VERSION ""

NS_ :

BS_:

BU_: Turbocharger OnBoardDataLogger OffBoardDiagnosticTool2 OffBoardDiagnosticTool1 FileServer ParkingBrakeController SeatControl2 FanDriveController SteeringColumnUnit CommunicationUnitRadio CommunicationUnitSatellite CommunicationUnitCellular PropulsionBatteryCharger ChassisController2 ChassisController1 EngineValveControl AuxiliaryHeater2 AuxiliaryHeater1 ClutchUnit RampControl InformationSystem1 SuspensionSystemController2 OilSensor VehicleDynamicStability ExhaustEmissionController TransmissionDisplay2 TransmissionDisplay1 ClimateControl2 WaterPumpController RearAxleSteeringController LightingOperatorControl SeatController1 IgnitionController2 IgnitionController1 TirePressureController CabController2 CabController1 PneumaticSystemController SuspensionSystemController1 HydraulicPumpController EnduranceBrakingSystem RetarderExhaustEngine2 OnBoardDiagnosticUnit HeadwayController RetarderExhaustEngine1 CabDisplay1 ManagementComputer VirtualTerminal OffVehicleGateway PowerTakeOffFront HitchControl AuxiliaryValveControl BodyController TractorTrailerBridge1 StarterSystem ElectricalSystem VehicleSecurity VehicleNavigation AerodynamicControl ElectricalChargingSystem ClimateControl1 TripRecorder InstrumentCluster SuspensionDriveAxle2 SuspensionDriveAxle1 SuspensionSteerAxle SteeringController FuelSystem CruiseControl RetarderDriveline RetarderEngine BrakesDriveAxle2 BrakesDriveAxle1 BrakesSystemController BrakesSteerAxle AxleDrive2 AxleDrive1 AxleSteering PowerTakeOff ShiftConsoleSecondary ShiftConsolePrimary Transmission2 Transmission1 Engine2 Engine1

BO_ 3221225472 VECTOR__INDEPENDENT_SIG_MSG: 0 Vector__XXX
 SG_ TrailerWeight : 0|16@1+ (2,0) [0|128510] "kg" Vector__XXX
 SG_ ReferenceTirePressSetting : 0|8@1+ (8,0) [0|2000] "kPa" Vector__XXX
 SG_ ReferenceTirePress : 0|8@1+ (8,0) [0|2000] "kPa" Vector__XXX
 SG_ TirePressThresholdDetection : 0|3@1+ (1,0) [0|7] "" Vector__XXX
 SG_ TireAirLeakageRate : 0|16@1+ (0.1,0) [0|6425.5] "Pa/s" Vector__XXX
 SG_ CTIWheelEndElectricalFault : 0|2@1+ (1,0) [0|3] "" Vector__XXX
 SG_ CTITireStatus : 0|2@1+ (1,0) [0|3] "" Vector__XXX
 SG_ CTIWheelSensorStatus : 0|2@1+ (1,0) [0|3] "" Vector__XXX
 SG_ TireTemp : 0|16@1+ (0.03125,-273) [-273|1734.96875] "deg C" Vector__XXX
 SG_ TirePress : 0|8@1+ (4,0) [0|1000] "kPa" Vector__XXX
 SG_ EngTorqueMode : 0|4@1+ (1,0) [0|15] "" Vector__XXX
 SG_ EngTrqMd_Corrected : 0|8@1+ (1,0) [0|255] "" Vector__XXX
 SG_ EngTrqMd_Corrected : 0|8@1+ (1,0) [0|255] "" Vector__XXX
 SG_ SrcAddrssOfCtrllngDvcFrEngCntrl : 0|8@1+ (1,0) [0|255] "" Vector__XXX
 SG_ ActlEngPrcntTrqueHighResolution : 0|4@1+ (0.125,0) [0|0.875] "%" Vector__XXX
 SG_ EngDemandPercentTorque : 0|8@1+ (1,-125) [-125|125] "%" Vector__XXX
 SG_ EngStarterMode : 0|4@1+ (1,0) [0|15] "" Vector__XXX
 SG_ EngSpeed : 0|16@1+ (0.125,0) [0|8031.875] "rpm" Vector__XXX
 SG_ ActualEngPercentTorque : 0|8@1+ (1,-125) [-125|125] "%" Vector__XXX
 SG_ DriversDemandEngPercentTorque : 0|8@1+ (1,-125) [-125|125] "%" Vector__XXX
 SG_ MessageCounter : 0|4@1+ (1,0) [0|15] "" Vector__XXX
 SG_ ControlPurpose : 0|5@1+ (1,0) [0|31] "" Vector__XXX
 SG_ TransmissionRate : 0|3@1+ (1,0) [0|7] "" Vector__XXX
 SG_ EngRqedTorque_TorqueLimit : 0|8@1+ (1,-125) [-125|125] "%" Vector__XXX
 SG_ EngRqedSpeed_SpeedLimit : 0|16@1+ (0.125,0) [0|8031.875] "rpm" Vector__XXX
 SG_ OverrideCtrlModePriority : 0|2@1+ (1,0) [0|3] "" Vector__XXX
 SG_ EngRqedSpeedCtrlConditions : 0|2@1+ (1,0) [0|3] "" Vector__XXX
 SG_ EngOverrideCtrlMode : 0|2@1+ (1,0) [0|3] "" Vector__XXX
 SG_ MessageChecksum : 0|4@1+ (1,0) [0|15] "" Vector__XXX
 SG_ EngineRequestedTorqueHiRes : 0|4@1+ (0.125,0) [0|0.875] "%" Vector__XXX
 SG_ TransCurrentRange : 0|16@1+ (1,0) [0|255] "" Vector__XXX
 SG_ TransRqedRange : 0|16@1+ (1,0) [0|255] "per" Vector__XXX
 SG_ TransCurrentGear : 0|8@1+ (1,-125) [-125|125] "" Vector__XXX
 SG_ TransActualGearRatio : 0|16@1+ (0.001,0) [0|64.255] "" Vector__XXX
 SG_ TransSelectedGear : 0|8@1+ (1,-125) [-125|125] "" Vector__XXX
 SG_ TrnsTrqueConverterLockupEngaged : 0|2@1+ (1,0) [0|3] "" Vector__XXX
 SG_ TrnsTrqCnvrtrLckpTrnstnInPrcess : 0|2@1+ (1,0) [0|3] "" Vector__XXX
 SG_ SrcAddrssOfCtrllngDvcFrTrnsCntrl : 0|8@1+ (1,0) [0|255] "" Vector__XXX
 SG_ MomentaryEngMaxPowerEnable : 0|2@1+ (1,0) [0|3] "" Vector__XXX
 SG_ TransInputShaftSpeed : 0|16@1+ (0.125,0) [0|8031.875] "rpm" Vector__XXX
 SG_ ProgressiveShiftDisable : 0|2@1+ (1,0) [0|3] "" Vector__XXX
 SG_ EngMomentaryOverspeedEnable : 0|2@1+ (1,0) [0|3] "" Vector__XXX
 SG_ PercentClutchSlip : 0|8@1+ (0.4,0) [0|100] "%" Vector__XXX
 SG_ TransOutputShaftSpeed : 0|16@1+ (0.125,0) [0|8031.875] "rpm" Vector__XXX
 SG_ TransShiftInProcess : 0|2@1+ (1,0) [0|3] "" Vector__XXX
 SG_ TransDrivelineEngaged : 0|2@1+ (1,0) [0|3] "" Vector__XXX
 SG_ UnitNumber : 0|8@1+ (1,0) [0|255] "" Vector__XXX
 SG_ SerialNumber : 0|8@1+ (1,0) [0|255] "" Vector__XXX
 SG_ Model : 0|8@1+ (1,0) [0|255] "" Vector__XXX
 SG_ Make : 0|8@1+ (1,0) [0|255] "" Vector__XXX
 SG_ DTC5 : 0|32@1+ (1,0) [0|4294967295] "" Vector__XXX
 SG_ DTC4 : 0|32@1+ (1,0) [0|4294967295] "" Vector__XXX
 SG_ DTC3 : 0|32@1+ (1,0) [0|4294967295] "" Vector__XXX
 SG_ DTC2 : 0|32@1+ (1,0) [0|4294967295] "" Vector__XXX

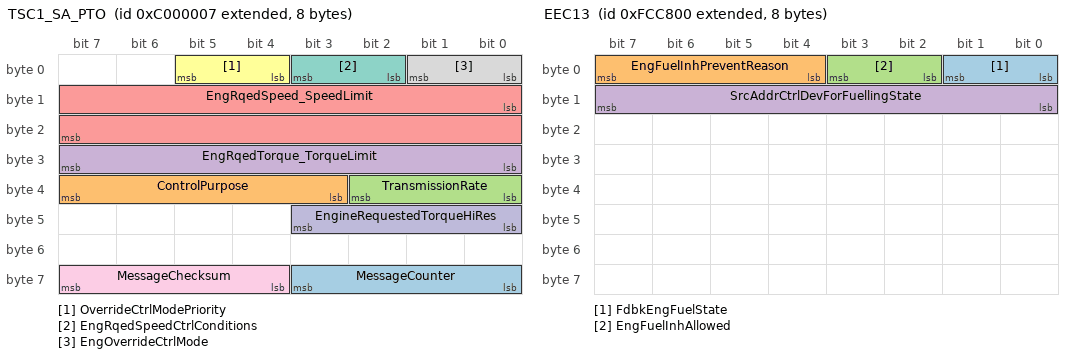
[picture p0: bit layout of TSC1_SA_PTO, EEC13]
BO_ 2348810247 TSC1_SA_PTO: 8 Vector__XXX
 SG_ MessageCounter : 56|4@1+ (1,0) [0|15] "" Vector__XXX
 SG_ ControlPurpose : 35|5@1+ (1,0) [0|31] "" Vector__XXX
 SG_ TransmissionRate : 32|3@1+ (1,0) [0|7] "" Vector__XXX
 SG_ EngRqedTorque_TorqueLimit : 24|8@1+ (1,-125) [-125|125] "%" Vector__XXX
 SG_ EngRqedSpeed_SpeedLimit : 8|16@1+ (0.125,0) [0|8031.875] "rpm" Vector__XXX
 SG_ OverrideCtrlModePriority : 4|2@1+ (1,0) [0|3] "" Vector__XXX
 SG_ EngRqedSpeedCtrlConditions : 2|2@1+ (1,0) [0|3] "" Vector__XXX
 SG_ EngOverrideCtrlMode : 0|2@1+ (1,0) [0|3] "" Vector__XXX
 SG_ MessageChecksum : 60|4@1+ (1,0) [0|15] "" Vector__XXX
 SG_ EngineRequestedTorqueHiRes : 40|4@1+ (0.125,0) [0|0.875] "%" Vector__XXX

BO_ 2558984192 ESR: 8 Vector__XXX
 SG_ DesEngFuelState : 0|2@1+ (1,0) [0|0] "" Vector__XXX

BO_ 2164049920 EEC13: 8 Vector__XXX
 SG_ FdbkEngFuelState : 0|2@1+ (1,0) [0|0] "" Vector__XXX
 SG_ EngFuelInhPreventReason : 4|4@1+ (1,0) [0|0] "" Vector__XXX
 SG_ EngFuelInhAllowed : 2|2@1+ (1,0) [0|0] "" Vector__XXX
 SG_ SrcAddrCtrlDevForFuellingState : 8|8@1+ (1,0) [0|255] "" Vector__XXX

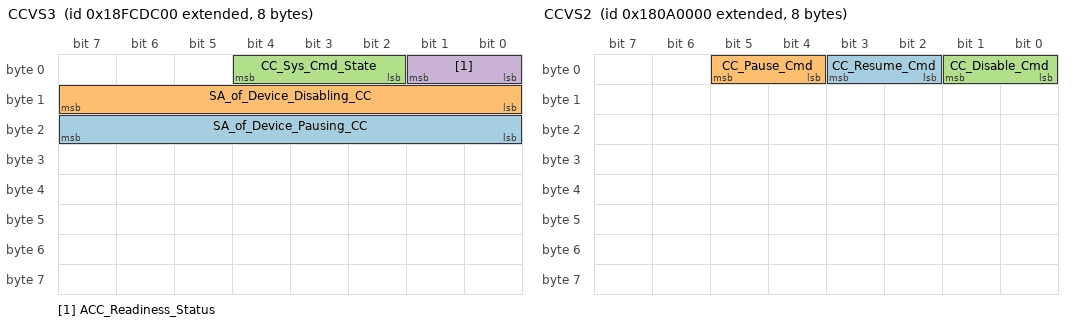
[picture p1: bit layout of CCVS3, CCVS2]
BO_ 2566708224 CCVS3: 8 Vector__XXX
 SG_ SA_of_Device_Pausing_CC : 16|8@1+ (1,0) [0|255] "" Vector__XXX
 SG_ SA_of_Device_Disabling_CC : 8|8@1+ (1,0) [0|255] "" Vector__XXX
 SG_ CC_Sys_Cmd_State : 2|3@1+ (1,0) [0|3] "" Vector__XXX
 SG_ ACC_Readiness_Status : 0|2@1+ (1,0) [0|3] "" Vector__XXX

BO_ 2550792192 CCVS2: 8 Vector__XXX
 SG_ CC_Resume_Cmd : 2|2@1+ (1,0) [0|3] "" Vector__XXX
 SG_ CC_Pause_Cmd : 4|2@1+ (1,0) [0|3] "" Vector__XXX
 SG_ CC_Disable_Cmd : 0|2@1+ (1,0) [0|3] "" Vector__XXX

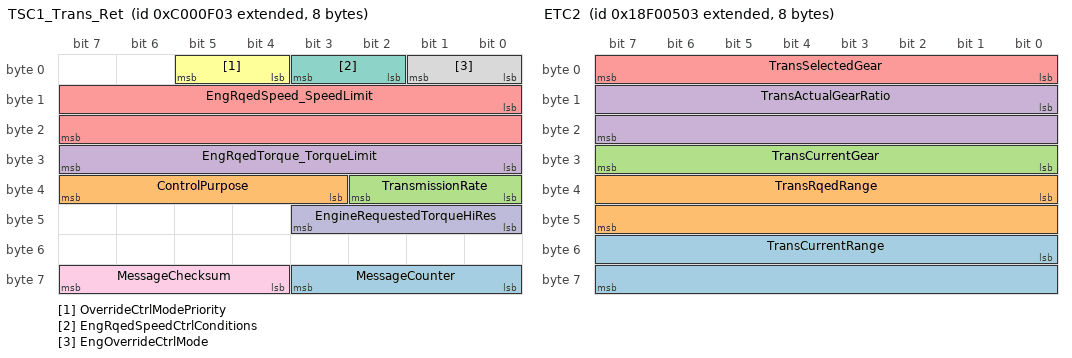
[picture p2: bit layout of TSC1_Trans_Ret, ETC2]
BO_ 2348814083 TSC1_Trans_Ret: 8 Vector__XXX
 SG_ MessageCounter : 56|4@1+ (1,0) [0|15] "" Vector__XXX
 SG_ ControlPurpose : 35|5@1+ (1,0) [0|31] "" Vector__XXX
 SG_ TransmissionRate : 32|3@1+ (1,0) [0|7] "" Vector__XXX
 SG_ EngRqedTorque_TorqueLimit : 24|8@1+ (1,-125) [-125|125] "%" Vector__XXX
 SG_ EngRqedSpeed_SpeedLimit : 8|16@1+ (0.125,0) [0|8031.875] "rpm" Vector__XXX
 SG_ OverrideCtrlModePriority : 4|2@1+ (1,0) [0|3] "" Vector__XXX
 SG_ EngRqedSpeedCtrlConditions : 2|2@1+ (1,0) [0|3] "" Vector__XXX
 SG_ EngOverrideCtrlMode : 0|2@1+ (1,0) [0|3] "" Vector__XXX
 SG_ MessageChecksum : 60|4@1+ (1,0) [0|15] "" Vector__XXX
 SG_ EngineRequestedTorqueHiRes : 40|4@1+ (0.125,0) [0|0.875] "%" Vector__XXX

BO_ 2565866755 ETC2: 8 Vector__XXX
 SG_ TransCurrentRange : 48|16@1+ (1,0) [0|255] "" Vector__XXX
 SG_ TransRqedRange : 32|16@1+ (1,0) [0|255] "per" Vector__XXX
 SG_ TransCurrentGear : 24|8@1+ (1,-125) [-125|125] "" Vector__XXX
 SG_ TransActualGearRatio : 8|16@1+ (0.001,0) [0|64.255] "" Vector__XXX
 SG_ TransSelectedGear : 0|8@1+ (1,-125) [-125|125] "" Vector__XXX

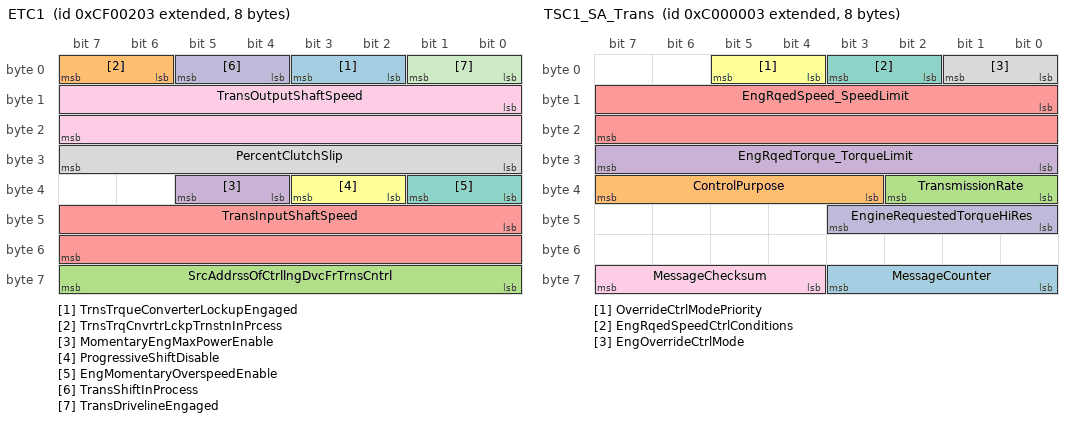
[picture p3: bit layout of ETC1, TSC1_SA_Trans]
BO_ 2364539395 ETC1: 8 Vector__XXX
 SG_ TrnsTrqueConverterLockupEngaged : 2|2@1+ (1,0) [0|3] "" Vector__XXX
 SG_ TrnsTrqCnvrtrLckpTrnstnInPrcess : 6|2@1+ (1,0) [0|3] "" Vector__XXX
 SG_ SrcAddrssOfCtrllngDvcFrTrnsCntrl : 56|8@1+ (1,0) [0|255] "" Vector__XXX
 SG_ MomentaryEngMaxPowerEnable : 36|2@1+ (1,0) [0|3] "" Vector__XXX
 SG_ TransInputShaftSpeed : 40|16@1+ (0.125,0) [0|8031.875] "rpm" Vector__XXX
 SG_ ProgressiveShiftDisable : 34|2@1+ (1,0) [0|3] "" Vector__XXX
 SG_ EngMomentaryOverspeedEnable : 32|2@1+ (1,0) [0|3] "" Vector__XXX
 SG_ PercentClutchSlip : 24|8@1+ (0.4,0) [0|100] "%" Vector__XXX
 SG_ TransOutputShaftSpeed : 8|16@1+ (0.125,0) [0|8031.875] "rpm" Vector__XXX
 SG_ TransShiftInProcess : 4|2@1+ (1,0) [0|3] "" Vector__XXX
 SG_ TransDrivelineEngaged : 0|2@1+ (1,0) [0|3] "" Vector__XXX

BO_ 2348810243 TSC1_SA_Trans: 8 Vector__XXX
 SG_ MessageCounter : 56|4@1+ (1,0) [0|15] "" Vector__XXX
 SG_ ControlPurpose : 35|5@1+ (1,0) [0|31] "" Vector__XXX
 SG_ TransmissionRate : 32|3@1+ (1,0) [0|7] "" Vector__XXX
 SG_ EngRqedTorque_TorqueLimit : 24|8@1+ (1,-125) [-125|125] "%" Vector__XXX
 SG_ EngRqedSpeed_SpeedLimit : 8|16@1+ (0.125,0) [0|8031.875] "rpm" Vector__XXX
 SG_ OverrideCtrlModePriority : 4|2@1+ (1,0) [0|3] "" Vector__XXX
 SG_ EngRqedSpeedCtrlConditions : 2|2@1+ (1,0) [0|3] "" Vector__XXX
 SG_ EngOverrideCtrlMode : 0|2@1+ (1,0) [0|3] "" Vector__XXX
 SG_ MessageChecksum : 60|4@1+ (1,0) [0|15] "" Vector__XXX
 SG_ EngineRequestedTorqueHiRes : 40|4@1+ (0.125,0) [0|0.875] "%" Vector__XXX

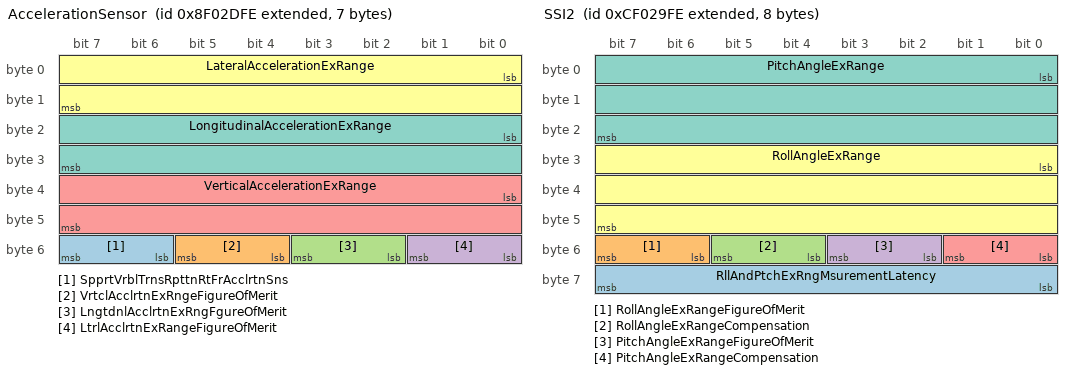
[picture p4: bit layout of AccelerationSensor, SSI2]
BO_ 2297441790 AccelerationSensor: 7 Vector__XXX
 SG_ SpprtVrblTrnsRpttnRtFrAcclrtnSns : 54|2@1+ (1,0) [0|3] "" Vector__XXX
 SG_ VrtclAcclrtnExRngeFigureOfMerit : 52|2@1+ (1,0) [0|3] "" Vector__XXX
 SG_ LngtdnlAcclrtnExRngFgureOfMerit : 50|2@1+ (1,0) [0|3] "" Vector__XXX
 SG_ LtrlAcclrtnExRangeFigureOfMerit : 48|2@1+ (1,0) [0|3] "" Vector__XXX
 SG_ VerticalAccelerationExRange : 32|16@1+ (0.01,-320) [-320|322.55] "m/s²" Vector__XXX
 SG_ LateralAccelerationExRange : 0|16@1+ (0.01,-320) [-320|322.55] "m/s²" Vector__XXX
 SG_ LongitudinalAccelerationExRange : 16|16@1+ (0.01,-320) [-320|322.55] "m/s²" Vector__XXX

BO_ 2566712062 VEP4: 8 Vector__XXX
 SG_ HybrdBatteryPackRemainingCharge : 0|16@1+ (0.0025,0) [0|160.6375] "%" Vector__XXX

BO_ 2364549630 SSI2: 8 Vector__XXX
 SG_ RllAndPtchExRngMsurementLatency : 56|8@1+ (0.5,0) [0|125] "ms" Vector__XXX
 SG_ RollAngleExRangeFigureOfMerit : 54|2@1+ (1,0) [0|3] "" Vector__XXX
 SG_ RollAngleExRangeCompensation : 52|2@1+ (1,0) [0|3] "" Vector__XXX
 SG_ PitchAngleExRangeFigureOfMerit : 50|2@1+ (1,0) [0|3] "" Vector__XXX
 SG_ PitchAngleExRangeCompensation : 48|2@1+ (1,0) [0|3] "" Vector__XXX
 SG_ RollAngleExRange : 24|24@1+ (3.0517578125E-005,-250) [-250|250.9999] "deg" Vector__XXX
 SG_ PitchAngleExRange : 0|24@1+ (3.0517578125E-005,-250) [-250|250.9999] "deg" Vector__XXX

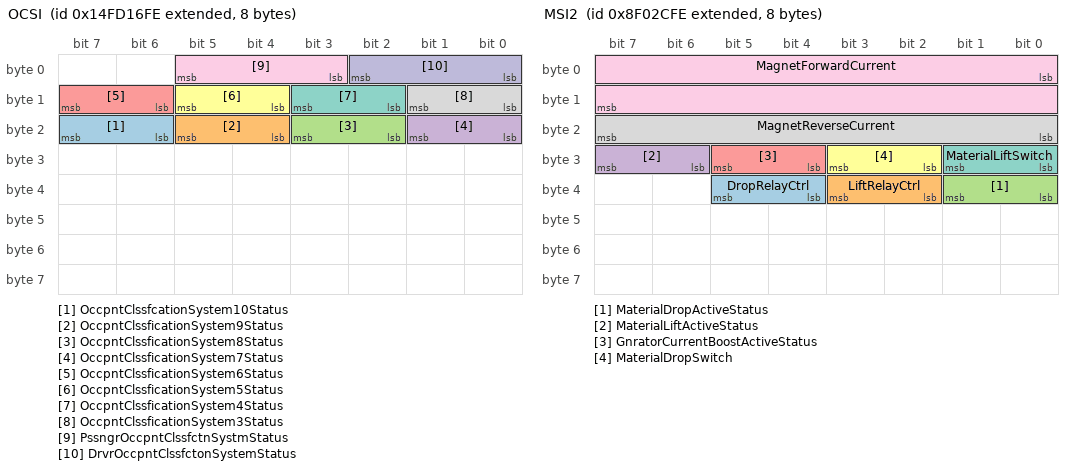
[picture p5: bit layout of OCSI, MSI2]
BO_ 2499614462 OCSI: 8 Vector__XXX
 SG_ OccpntClssfcationSystem10Status : 22|2@1+ (1,0) [0|3] "" Vector__XXX
 SG_ OccpntClssficationSystem9Status : 20|2@1+ (1,0) [0|3] "" Vector__XXX
 SG_ OccpntClssficationSystem8Status : 18|2@1+ (1,0) [0|3] "" Vector__XXX
 SG_ OccpntClssficationSystem7Status : 16|2@1+ (1,0) [0|3] "" Vector__XXX
 SG_ OccpntClssficationSystem6Status : 14|2@1+ (1,0) [0|3] "" Vector__XXX
 SG_ OccpntClssficationSystem5Status : 12|2@1+ (1,0) [0|3] "" Vector__XXX
 SG_ OccpntClssficationSystem4Status : 10|2@1+ (1,0) [0|3] "" Vector__XXX
 SG_ OccpntClssficationSystem3Status : 8|2@1+ (1,0) [0|3] "" Vector__XXX
 SG_ PssngrOccpntClssfctnSystmStatus : 3|3@1+ (1,0) [0|7] "" Vector__XXX
 SG_ DrvrOccpntClssfctonSystemStatus : 0|3@1+ (1,0) [0|7] "" Vector__XXX

BO_ 2560098046 NCS: 8 Vector__XXX
 SG_ CabNoiseCtrlTuningStatus : 2|4@1+ (1,0) [0|15] "" Vector__XXX
 SG_ CabNoiseCtrlStatus : 0|2@1+ (1,0) [0|3] "" Vector__XXX

BO_ 2560163582 NC1: 8 Vector__XXX
 SG_ CabNoiseCtrlTuningState : 2|3@1+ (1,0) [0|7] "" Vector__XXX
 SG_ CabNoiseCtrlState : 0|2@1+ (1,0) [0|3] "" Vector__XXX

BO_ 2297441534 MSI2: 8 Vector__XXX
 SG_ DropRelayCtrl : 36|2@1+ (1,0) [0|3] "" Vector__XXX
 SG_ LiftRelayCtrl : 34|2@1+ (1,0) [0|3] "" Vector__XXX
 SG_ MaterialDropActiveStatus : 32|2@1+ (1,0) [0|3] "" Vector__XXX
 SG_ MaterialLiftActiveStatus : 30|2@1+ (1,0) [0|3] "" Vector__XXX
 SG_ GnratorCurrentBoostActiveStatus : 28|2@1+ (1,0) [0|3] "" Vector__XXX
 SG_ MaterialDropSwitch : 26|2@1+ (1,0) [0|3] "" Vector__XXX
 SG_ MaterialLiftSwitch : 24|2@1+ (1,0) [0|3] "" Vector__XXX
 SG_ MagnetReverseCurrent : 16|8@1+ (1,0) [0|250] "A" Vector__XXX
 SG_ MagnetForwardCurrent : 0|16@1+ (1,0) [0|64255] "Amps" Vector__XXX

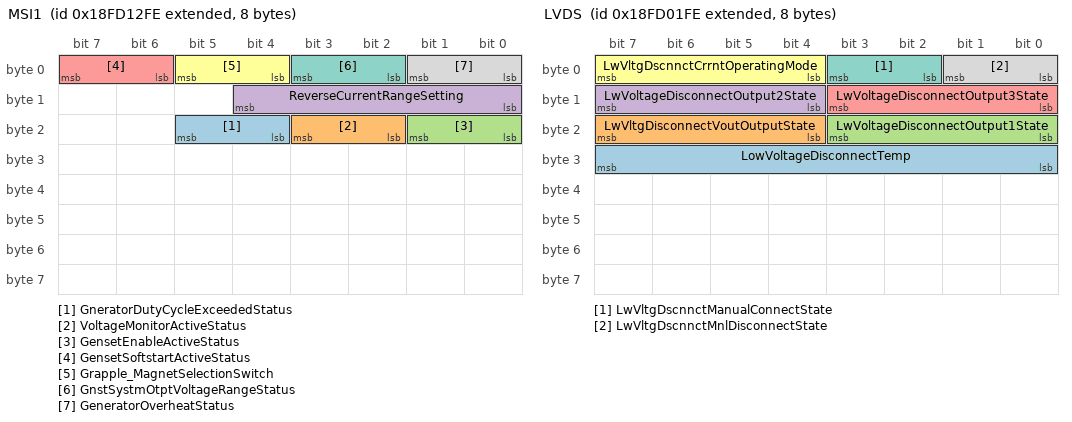
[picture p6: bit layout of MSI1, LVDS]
BO_ 2566722302 MSI1: 8 Vector__XXX
 SG_ GneratorDutyCycleExceededStatus : 20|2@1+ (1,0) [0|3] "" Vector__XXX
 SG_ VoltageMonitorActiveStatus : 18|2@1+ (1,0) [0|3] "" Vector__XXX
 SG_ GensetEnableActiveStatus : 16|2@1+ (1,0) [0|3] "" Vector__XXX
 SG_ ReverseCurrentRangeSetting : 8|5@1+ (1,0) [0|31] "" Vector__XXX
 SG_ GensetSoftstartActiveStatus : 6|2@1+ (1,0) [0|3] "" Vector__XXX
 SG_ Grapple_MagnetSelectionSwitch : 4|2@1+ (1,0) [0|3] "" Vector__XXX
 SG_ GnstSystmOtptVoltageRangeStatus : 2|2@1+ (1,0) [0|3] "" Vector__XXX
 SG_ GeneratorOverheatStatus : 0|2@1+ (1,0) [0|3] "" Vector__XXX

BO_ 2566722558 MSCI: 8 Vector__XXX
 SG_ MagnetRatedPower : 8|16@1+ (0.5,0) [0|32127.5] "kW" Vector__XXX
 SG_ MagnetBoostTime : 0|8@1+ (0.25,0) [0|62.5] "s" Vector__XXX

BO_ 2560032510 LVDSOM: 8 Vector__XXX
 SG_ LwVltgDscnnctDsredOperatingMode : 0|4@1+ (1,0) [0|15] "" Vector__XXX

BO_ 2566717950 LVDS: 8 Vector__XXX
 SG_ LowVoltageDisconnectTemp : 24|8@1+ (1,-40) [-40|210] "deg C" Vector__XXX
 SG_ LwVltgDisconnectVoutOutputState : 20|4@1+ (1,0) [0|15] "" Vector__XXX
 SG_ LwVoltageDisconnectOutput1State : 16|4@1+ (1,0) [0|15] "" Vector__XXX
 SG_ LwVoltageDisconnectOutput2State : 12|4@1+ (1,0) [0|15] "" Vector__XXX
 SG_ LwVoltageDisconnectOutput3State : 8|4@1+ (1,0) [0|15] "" Vector__XXX
 SG_ LwVltgDscnnctCrrntOperatingMode : 4|4@1+ (1,0) [0|15] "" Vector__XXX
 SG_ LwVltgDscnnctManualConnectState : 2|2@1+ (1,0) [0|3] "" Vector__XXX
 SG_ LwVltgDscnnctMnlDisconnectState : 0|2@1+ (1,0) [0|3] "" Vector__XXX

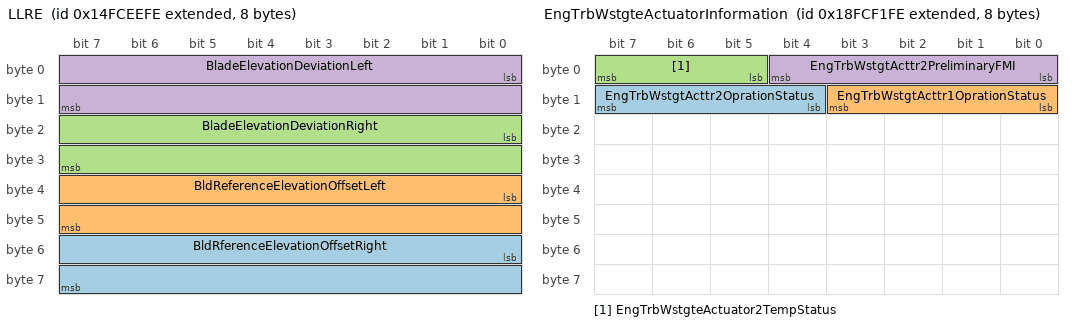
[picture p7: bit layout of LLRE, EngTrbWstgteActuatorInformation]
BO_ 2499604222 LLRE: 8 Vector__XXX
 SG_ BldRferenceElevationOffsetRight : 48|16@1+ (1,-32000) [-32000|32255] "mm" Vector__XXX
 SG_ BldReferenceElevationOffsetLeft : 32|16@1+ (1,-32000) [-32000|32255] "mm" Vector__XXX
 SG_ BladeElevationDeviationRight : 16|16@1+ (1,-32000) [-32000|32255] "mm" Vector__XXX
 SG_ BladeElevationDeviationLeft : 0|16@1+ (1,-32000) [-32000|32255] "mm" Vector__XXX

BO_ 2358902526 JLCM: 8 Vector__XXX
 SG_ Joystick3Lamp10Cmd : 58|2@1+ (1,0) [0|3] "" Vector__XXX
 SG_ Joystick3Lamp9Cmd : 56|2@1+ (1,0) [0|3] "" Vector__XXX
 SG_ Joystick3Lamp8Cmd : 54|2@1+ (1,0) [0|3] "" Vector__XXX
 SG_ Joystick3Lamp7Cmd : 52|2@1+ (1,0) [0|3] "" Vector__XXX
 SG_ Joystick3Lamp6Cmd : 50|2@1+ (1,0) [0|3] "" Vector__XXX
 SG_ Joystick3Lamp5Cmd : 48|2@1+ (1,0) [0|3] "" Vector__XXX
 SG_ Joystick3Lamp4Cmd : 46|2@1+ (1,0) [0|3] "" Vector__XXX
 SG_ Joystick3Lamp3Cmd : 44|2@1+ (1,0) [0|3] "" Vector__XXX
 SG_ Joystick3Lamp2Cmd : 42|2@1+ (1,0) [0|3] "" Vector__XXX
 SG_ Joystick3Lamp1Cmd : 40|2@1+ (1,0) [0|3] "" Vector__XXX
 SG_ Joystick2Lamp10Cmd : 38|2@1+ (1,0) [0|3] "" Vector__XXX
 SG_ Joystick2Lamp9Cmd : 36|2@1+ (1,0) [0|3] "" Vector__XXX
 SG_ Joystick2Lamp8Cmd : 34|2@1+ (1,0) [0|3] "" Vector__XXX
 SG_ Joystick2Lamp7Cmd : 32|2@1+ (1,0) [0|3] "" Vector__XXX
 SG_ Joystick2Lamp6Cmd : 30|2@1+ (1,0) [0|3] "" Vector__XXX
 SG_ Joystick2Lamp5Cmd : 28|2@1+ (1,0) [0|3] "" Vector__XXX
 SG_ Joystick2Lamp4Cmd : 26|2@1+ (1,0) [0|3] "" Vector__XXX
 SG_ Joystick2Lamp3Cmd : 24|2@1+ (1,0) [0|3] "" Vector__XXX
 SG_ Joystick2Lamp2Cmd : 22|2@1+ (1,0) [0|3] "" Vector__XXX
 SG_ Joystick2Lamp1Cmd : 20|2@1+ (1,0) [0|3] "" Vector__XXX
 SG_ Joystick1Lamp10Cmd : 18|2@1+ (1,0) [0|3] "" Vector__XXX
 SG_ Joystick1Lamp9Cmd : 16|2@1+ (1,0) [0|3] "" Vector__XXX
 SG_ Joystick1Lamp8Cmd : 14|2@1+ (1,0) [0|3] "" Vector__XXX
 SG_ Joystick1Lamp7Cmd : 12|2@1+ (1,0) [0|3] "" Vector__XXX
 SG_ Joystick1Lamp6Cmd : 10|2@1+ (1,0) [0|3] "" Vector__XXX
 SG_ Joystick1Lamp5Cmd : 8|2@1+ (1,0) [0|3] "" Vector__XXX
 SG_ Joystick1Lamp4Cmd : 6|2@1+ (1,0) [0|3] "" Vector__XXX
 SG_ Joystick1Lamp3Cmd : 4|2@1+ (1,0) [0|3] "" Vector__XXX
 SG_ Joystick1Lamp2Cmd : 2|2@1+ (1,0) [0|3] "" Vector__XXX
 SG_ Joystick1Lamp1Cmd : 0|2@1+ (1,0) [0|3] "" Vector__XXX

BO_ 2566711550 IVAC: 8 Vector__XXX
 SG_ IntkVlvActtnSystmOlPrss2SlndCtrl : 2|2@1+ (1,0) [0|3] "" Vector__XXX
 SG_ IntkVlvActtnSystmOlPrss1SlndCtrl : 0|2@1+ (1,0) [0|3] "" Vector__XXX

BO_ 2633832958 ILI: 200 Vector__XXX
 SG_ SpecialIgnitorLoop90Resistance : 1584|16@1+ (0.1,0) [0|6425.5] "ohm" Vector__XXX
 SG_ SpecialIgnitorLoop89Resistance : 1568|16@1+ (0.1,0) [0|6425.5] "ohm" Vector__XXX
 SG_ SpecialIgnitorLoop88Resistance : 1552|16@1+ (0.1,0) [0|6425.5] "ohm" Vector__XXX
 SG_ SpecialIgnitorLoop87Resistance : 1536|16@1+ (0.1,0) [0|6425.5] "ohm" Vector__XXX
 SG_ SpecialIgnitorLoop86Resistance : 1520|16@1+ (0.1,0) [0|6425.5] "ohm" Vector__XXX
 SG_ SpecialIgnitorLoop85Resistance : 1504|16@1+ (0.1,0) [0|6425.5] "ohm" Vector__XXX
 SG_ SpecialIgnitorLoop84Resistance : 1488|16@1+ (0.1,0) [0|6425.5] "ohm" Vector__XXX
 SG_ SpecialIgnitorLoop83Resistance : 1472|16@1+ (0.1,0) [0|6425.5] "ohm" Vector__XXX
 SG_ SpecialIgnitorLoop82Resistance : 1456|16@1+ (0.1,0) [0|6425.5] "ohm" Vector__XXX
 SG_ SpecialIgnitorLoop81Resistance : 1440|16@1+ (0.1,0) [0|6425.5] "ohm" Vector__XXX
 SG_ SpecialIgnitorLoop80Resistance : 1424|16@1+ (0.1,0) [0|6425.5] "ohm" Vector__XXX
 SG_ SpecialIgnitorLoop79Resistance : 1408|16@1+ (0.1,0) [0|6425.5] "ohm" Vector__XXX
 SG_ SpecialIgnitorLoop78Resistance : 1392|16@1+ (0.1,0) [0|6425.5] "ohm" Vector__XXX
 SG_ SpecialIgnitorLoop77Resistance : 1376|16@1+ (0.1,0) [0|6425.5] "ohm" Vector__XXX
 SG_ SpecialIgnitorLoop76Resistance : 1360|16@1+ (0.1,0) [0|6425.5] "ohm" Vector__XXX
 SG_ SpecialIgnitorLoop75Resistance : 1344|16@1+ (0.1,0) [0|6425.5] "ohm" Vector__XXX
 SG_ SpecialIgnitorLoop74Resistance : 1328|16@1+ (0.1,0) [0|6425.5] "ohm" Vector__XXX
 SG_ SpecialIgnitorLoop73Resistance : 1312|16@1+ (0.1,0) [0|6425.5] "ohm" Vector__XXX
 SG_ SpecialIgnitorLoop72Resistance : 1296|16@1+ (0.1,0) [0|6425.5] "ohm" Vector__XXX
 SG_ SpecialIgnitorLoop71Resistance : 1280|16@1+ (0.1,0) [0|6425.5] "ohm" Vector__XXX
 SG_ SpecialIgnitorLoop70Resistance : 1264|16@1+ (0.1,0) [0|6425.5] "ohm" Vector__XXX
 SG_ SpecialIgnitorLoop69Resistance : 1248|16@1+ (0.1,0) [0|6425.5] "ohm" Vector__XXX
 SG_ SpecialIgnitorLoop68Resistance : 1232|16@1+ (0.1,0) [0|6425.5] "ohm" Vector__XXX
 SG_ SpecialIgnitorLoop67Resistance : 1216|16@1+ (0.1,0) [0|6425.5] "ohm" Vector__XXX
 SG_ SpecialIgnitorLoop66Resistance : 1200|16@1+ (0.1,0) [0|6425.5] "ohm" Vector__XXX
 SG_ SpecialIgnitorLoop65Resistance : 1184|16@1+ (0.1,0) [0|6425.5] "ohm" Vector__XXX
 SG_ SpecialIgnitorLoop64Resistance : 1168|16@1+ (0.1,0) [0|6425.5] "ohm" Vector__XXX
 SG_ SpecialIgnitorLoop63Resistance : 1152|16@1+ (0.1,0) [0|6425.5] "ohm" Vector__XXX
 SG_ SpecialIgnitorLoop61Resistance : 1120|16@1+ (0.1,0) [0|6425.5] "ohm" Vector__XXX
 SG_ SpecialIgnitorLoop60Resistance : 1104|16@1+ (0.1,0) [0|6425.5] "ohm" Vector__XXX
 SG_ SpecialIgnitorLoop59Resistance : 1088|16@1+ (0.1,0) [0|6425.5] "ohm" Vector__XXX
 SG_ SpecialIgnitorLoop58Resistance : 1072|16@1+ (0.1,0) [0|6425.5] "ohm" Vector__XXX
 SG_ SpecialIgnitorLoop57Resistance : 1056|16@1+ (0.1,0) [0|6425.5] "ohm" Vector__XXX
 SG_ SpecialIgnitorLoop56Resistance : 1040|16@1+ (0.1,0) [0|6425.5] "ohm" Vector__XXX
 SG_ SpecialIgnitorLoop55Resistance : 1024|16@1+ (0.1,0) [0|6425.5] "ohm" Vector__XXX
 SG_ SpecialIgnitorLoop54Resistance : 1008|16@1+ (0.1,0) [0|6425.5] "ohm" Vector__XXX
 SG_ SpecialIgnitorLoop53Resistance : 992|16@1+ (0.1,0) [0|6425.5] "ohm" Vector__XXX
 SG_ SpecialIgnitorLoop52Resistance : 976|16@1+ (0.1,0) [0|6425.5] "ohm" Vector__XXX
 SG_ SpecialIgnitorLoop51Resistance : 960|16@1+ (0.1,0) [0|6425.5] "ohm" Vector__XXX
 SG_ SpecialIgnitorLoop50Resistance : 944|16@1+ (0.1,0) [0|6425.5] "ohm" Vector__XXX
 SG_ SpecialIgnitorLoop49Resistance : 928|16@1+ (0.1,0) [0|6425.5] "ohm" Vector__XXX
 SG_ SpecialIgnitorLoop48Resistance : 912|16@1+ (0.1,0) [0|6425.5] "ohm" Vector__XXX
 SG_ SpecialIgnitorLoop47Resistance : 896|16@1+ (0.1,0) [0|6425.5] "ohm" Vector__XXX
 SG_ SpecialIgnitorLoop46Resistance : 880|16@1+ (0.1,0) [0|6425.5] "ohm" Vector__XXX
 SG_ SpecialIgnitorLoop45Resistance : 864|16@1+ (0.1,0) [0|6425.5] "ohm" Vector__XXX
 SG_ SpecialIgnitorLoop44Resistance : 848|16@1+ (0.1,0) [0|6425.5] "ohm" Vector__XXX
 SG_ SpecialIgnitorLoop43Resistance : 832|16@1+ (0.1,0) [0|6425.5] "ohm" Vector__XXX
 SG_ SpecialIgnitorLoop42Resistance : 816|16@1+ (0.1,0) [0|6425.5] "ohm" Vector__XXX
 SG_ SpecialIgnitorLoop41Resistance : 800|16@1+ (0.1,0) [0|6425.5] "ohm" Vector__XXX
 SG_ SpecialIgnitorLoop40Resistance : 784|16@1+ (0.1,0) [0|6425.5] "ohm" Vector__XXX
 SG_ SpecialIgnitorLoop39Resistance : 768|16@1+ (0.1,0) [0|6425.5] "ohm" Vector__XXX
 SG_ SpecialIgnitorLoop38Resistance : 752|16@1+ (0.1,0) [0|6425.5] "ohm" Vector__XXX
 SG_ SpecialIgnitorLoop37Resistance : 736|16@1+ (0.1,0) [0|6425.5] "ohm" Vector__XXX
 SG_ SpecialIgnitorLoop36Resistance : 720|16@1+ (0.1,0) [0|6425.5] "ohm" Vector__XXX
 SG_ SpecialIgnitorLoop35Resistance : 704|16@1+ (0.1,0) [0|6425.5] "ohm" Vector__XXX
 SG_ SpecialIgnitorLoop34Resistance : 688|16@1+ (0.1,0) [0|6425.5] "ohm" Vector__XXX
 SG_ SpecialIgnitorLoop33Resistance : 672|16@1+ (0.1,0) [0|6425.5] "ohm" Vector__XXX
 SG_ SpecialIgnitorLoop32Resistance : 656|16@1+ (0.1,0) [0|6425.5] "ohm" Vector__XXX
 SG_ SpecialIgnitorLoop31Resistance : 640|16@1+ (0.1,0) [0|6425.5] "ohm" Vector__XXX
 SG_ SpecialIgnitorLoop30Resistance : 624|16@1+ (0.1,0) [0|6425.5] "ohm" Vector__XXX
 SG_ SpecialIgnitorLoop29Resistance : 608|16@1+ (0.1,0) [0|6425.5] "ohm" Vector__XXX
 SG_ SpecialIgnitorLoop28Resistance : 592|16@1+ (0.1,0) [0|6425.5] "ohm" Vector__XXX
 SG_ SpecialIgnitorLoop27Resistance : 576|16@1+ (0.1,0) [0|6425.5] "ohm" Vector__XXX
 SG_ SpecialIgnitorLoop26Resistance : 560|16@1+ (0.1,0) [0|6425.5] "ohm" Vector__XXX
 SG_ SpecialIgnitorLoop25Resistance : 544|16@1+ (0.1,0) [0|6425.5] "ohm" Vector__XXX
 SG_ SpecialIgnitorLoop24Resistance : 528|16@1+ (0.1,0) [0|6425.5] "ohm" Vector__XXX
 SG_ SpecialIgnitorLoop23Resistance : 512|16@1+ (0.1,0) [0|6425.5] "ohm" Vector__XXX
 SG_ SpecialIgnitorLoop22Resistance : 496|16@1+ (0.1,0) [0|6425.5] "ohm" Vector__XXX
 SG_ SpecialIgnitorLoop21Resistance : 480|16@1+ (0.1,0) [0|6425.5] "ohm" Vector__XXX
 SG_ SpecialIgnitorLoop20Resistance : 464|16@1+ (0.1,0) [0|6425.5] "ohm" Vector__XXX
 SG_ SpecialIgnitorLoop19Resistance : 448|16@1+ (0.1,0) [0|6425.5] "ohm" Vector__XXX
 SG_ SpecialIgnitorLoop18Resistance : 432|16@1+ (0.1,0) [0|6425.5] "ohm" Vector__XXX
 SG_ SpecialIgnitorLoop17Resistance : 416|16@1+ (0.1,0) [0|6425.5] "ohm" Vector__XXX
 SG_ SpecialIgnitorLoop16Resistance : 400|16@1+ (0.1,0) [0|6425.5] "ohm" Vector__XXX
 SG_ SpecialIgnitorLoop15Resistance : 384|16@1+ (0.1,0) [0|6425.5] "ohm" Vector__XXX
 SG_ SpecialIgnitorLoop14Resistance : 368|16@1+ (0.1,0) [0|6425.5] "ohm" Vector__XXX
 SG_ SpecialIgnitorLoop13Resistance : 352|16@1+ (0.1,0) [0|6425.5] "ohm" Vector__XXX
 SG_ SpecialIgnitorLoop12Resistance : 336|16@1+ (0.1,0) [0|6425.5] "ohm" Vector__XXX
 SG_ SpecialIgnitorLoop11Resistance : 320|16@1+ (0.1,0) [0|6425.5] "ohm" Vector__XXX
 SG_ SpecialIgnitorLoop10Resistance : 304|16@1+ (0.1,0) [0|6425.5] "ohm" Vector__XXX
 SG_ SpecialIgnitorLoop9Resistance : 288|16@1+ (0.1,0) [0|6425.5] "ohm" Vector__XXX
 SG_ SpecialIgnitorLoop8Resistance : 272|16@1+ (0.1,0) [0|6425.5] "ohm" Vector__XXX
 SG_ SpecialIgnitorLoop7Resistance : 256|16@1+ (0.1,0) [0|6425.5] "ohm" Vector__XXX
 SG_ SpecialIgnitorLoop6Resistance : 240|16@1+ (0.1,0) [0|6425.5] "ohm" Vector__XXX
 SG_ SpecialIgnitorLoop5Resistance : 224|16@1+ (0.1,0) [0|6425.5] "ohm" Vector__XXX
 SG_ SpecialIgnitorLoop4Resistance : 208|16@1+ (0.1,0) [0|6425.5] "ohm" Vector__XXX
 SG_ SpecialIgnitorLoop3Resistance : 192|16@1+ (0.1,0) [0|6425.5] "ohm" Vector__XXX
 SG_ SpecialIgnitorLoop2Resistance : 176|16@1+ (0.1,0) [0|6425.5] "ohm" Vector__XXX
 SG_ SpecialIgnitorLoop1Resistance : 160|16@1+ (0.1,0) [0|6425.5] "ohm" Vector__XXX
 SG_ SdBgIgnitorLoop2RightResistance : 144|16@1+ (0.1,0) [0|6425.5] "ohm" Vector__XXX
 SG_ SdBgIgnitorLoop1RightResistance : 128|16@1+ (0.1,0) [0|6425.5] "ohm" Vector__XXX
 SG_ SdBagIgnitorLoop2LeftResistance : 112|16@1+ (0.1,0) [0|6425.5] "ohm" Vector__XXX
 SG_ SdBagIgnitorLoop1LeftResistance : 96|16@1+ (0.1,0) [0|6425.5] "ohm" Vector__XXX
 SG_ PssngrBltTnsnrIgntrLpResistance : 80|16@1+ (0.1,0) [0|6425.5] "ohm" Vector__XXX
 SG_ DrvrBltTnsnrIgntrLoopResistance : 64|16@1+ (0.1,0) [0|6425.5] "ohm" Vector__XXX
 SG_ PssngrArbgIgntrLp2ndStgRsstance : 48|16@1+ (0.1,0) [0|6425.5] "ohm" Vector__XXX
 SG_ DrvrArbgIgntrLp2ndStgResistance : 32|16@1+ (0.1,0) [0|6425.5] "ohm" Vector__XXX
 SG_ PssngrArbgIgntrLp1stStgRsstance : 16|16@1+ (0.1,0) [0|6425.5] "ohm" Vector__XXX
 SG_ DrvrArbgIgntrLp1stStgResistance : 0|16@1+ (0.1,0) [0|6425.5] "ohm" Vector__XXX

BO_ 2566719998 HRLFC: 8 Vector__XXX
 SG_ HighResolutionEngTotalFuelUsed : 32|32@1+ (0.001,0) [0|4211081.215] "L" Vector__XXX
 SG_ HighResolutionEngTripFuel : 0|32@1+ (0.001,0) [0|4211081.215] "L" Vector__XXX

BO_ 2565877502 EngTrboWastegateActuatorCtrlCmd: 8 Vector__XXX
 SG_ EngTurboWastegateActuator2Cmd : 16|16@1+ (0.0025,0) [0|160.6375] "%" Vector__XXX
 SG_ EngTurboWastegateActuator1Cmd : 0|16@1+ (0.0025,0) [0|160.6375] "%" Vector__XXX

BO_ 2566713854 EngTrbWstgteActuatorInformation: 8 Vector__XXX
 SG_ EngTrbWstgtActtr2OprationStatus : 12|4@1+ (1,0) [0|15] "" Vector__XXX
 SG_ EngTrbWstgtActtr1OprationStatus : 8|4@1+ (1,0) [0|15] "" Vector__XXX
 SG_ EngTrbWstgteActuator2TempStatus : 5|3@1+ (1,0) [0|7] "" Vector__XXX
 SG_ EngTrbWstgtActtr2PreliminaryFMI : 0|5@1+ (1,0) [0|31] "" Vector__XXX

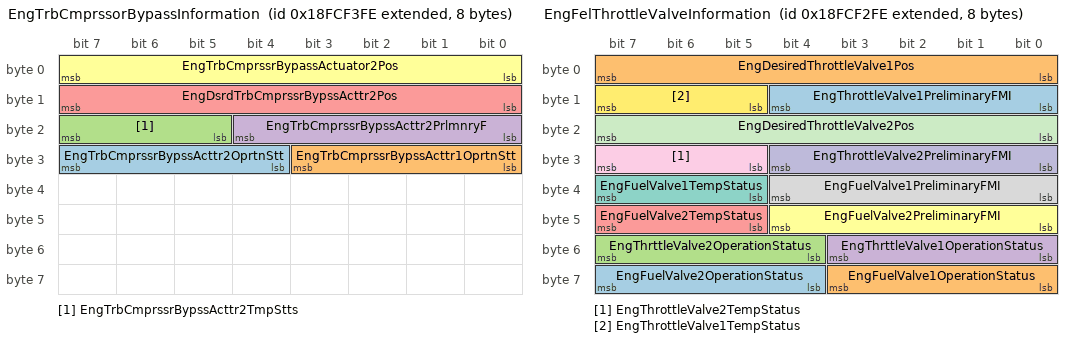
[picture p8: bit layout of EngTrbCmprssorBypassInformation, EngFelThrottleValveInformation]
BO_ 2566714366 EngTrbCmprssorBypassInformation: 8 Vector__XXX
 SG_ EngTrbCmprssrBypssActtr2OprtnStt : 28|4@1+ (1,0) [0|15] "" Vector__XXX
 SG_ EngTrbCmprssrBypssActtr1OprtnStt : 24|4@1+ (1,0) [0|15] "" Vector__XXX
 SG_ EngTrbCmprssrBypssActtr2TmpStts : 21|3@1+ (1,0) [0|7] "" Vector__XXX
 SG_ EngTrbCmprssrBypssActtr2PrlmnryF : 16|5@1+ (1,0) [0|31] "" Vector__XXX
 SG_ EngDsrdTrbCmprssrBypssActtr2Pos : 8|8@1+ (0.4,0) [0|100] "%" Vector__XXX
 SG_ EngTrbCmprssrBypassActuator2Pos : 0|8@1+ (0.4,0) [0|100] "%" Vector__XXX

BO_ 2566714110 EngFelThrottleValveInformation: 8 Vector__XXX
 SG_ EngFuelValve2OperationStatus : 60|4@1+ (1,0) [0|15] "" Vector__XXX
 SG_ EngFuelValve1OperationStatus : 56|4@1+ (1,0) [0|15] "" Vector__XXX
 SG_ EngThrttleValve2OperationStatus : 52|4@1+ (1,0) [0|15] "" Vector__XXX
 SG_ EngThrttleValve1OperationStatus : 48|4@1+ (1,0) [0|15] "" Vector__XXX
 SG_ EngFuelValve2TempStatus : 45|3@1+ (1,0) [0|7] "" Vector__XXX
 SG_ EngFuelValve2PreliminaryFMI : 40|5@1+ (1,0) [0|31] "" Vector__XXX
 SG_ EngFuelValve1TempStatus : 37|3@1+ (1,0) [0|7] "" Vector__XXX
 SG_ EngFuelValve1PreliminaryFMI : 32|5@1+ (1,0) [0|31] "" Vector__XXX
 SG_ EngThrottleValve2TempStatus : 29|3@1+ (1,0) [0|7] "" Vector__XXX
 SG_ EngThrottleValve2PreliminaryFMI : 24|5@1+ (1,0) [0|31] "" Vector__XXX
 SG_ EngDesiredThrottleValve2Pos : 16|8@1+ (0.4,0) [0|100] "%" Vector__XXX
 SG_ EngThrottleValve1TempStatus : 13|3@1+ (1,0) [0|7] "" Vector__XXX
 SG_ EngThrottleValve1PreliminaryFMI : 8|5@1+ (1,0) [0|31] "" Vector__XXX
 SG_ EngDesiredThrottleValve1Pos : 0|8@1+ (0.4,0) [0|100] "%" Vector__XXX

BO_ 2566717438 ET5: 8 Vector__XXX
 SG_ EngExhstGsRcrcltn2MxrIntakeTemp : 16|16@1+ (0.03125,-273) [-273|1734.96875] "deg C" Vector__XXX
 SG_ EngExhaustGasRecirculation2Temp : 0|16@1+ (0.03125,-273) [-273|1734.96875] "deg C" Vector__XXX

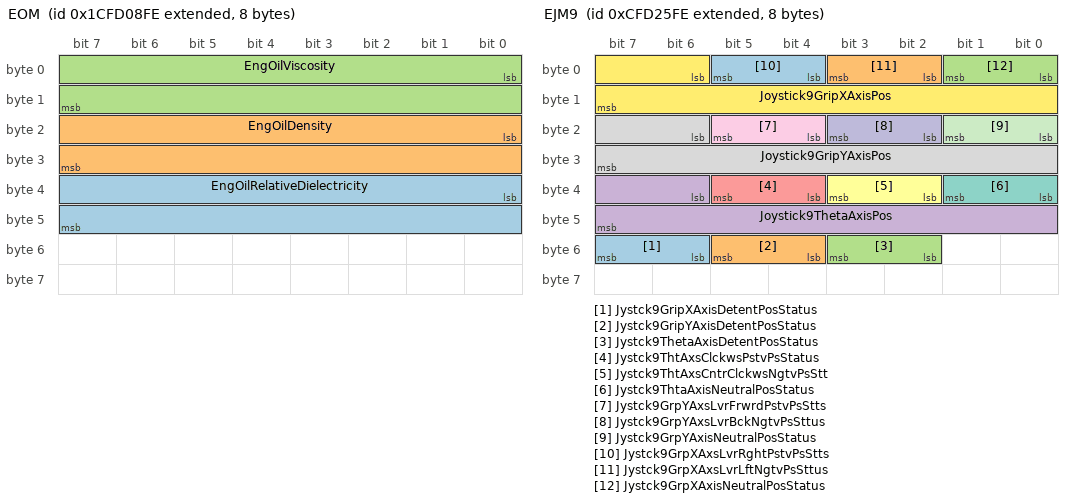
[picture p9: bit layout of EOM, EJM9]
BO_ 2633828606 EOM: 8 Vector__XXX
 SG_ EngOilRelativeDielectricity : 32|16@1+ (0.0001220703125,0) [0|7.844] "" Vector__XXX
 SG_ EngOilDensity : 16|16@1+ (3.052E-005,0) [0|1.961] "g/cc" Vector__XXX
 SG_ EngOilViscosity : 0|16@1+ (0.015625,0) [0|1003.984375] "Cp" Vector__XXX

BO_ 2499607550 EMAP: 8 Vector__XXX
 SG_ EngExhstMnfldBnk2FlwBlncVlvActtr : 16|16@1+ (0.0025,0) [0|160.6375] "%" Vector__XXX
 SG_ EngExhstMnfldBnk1FlwBlncVlvActtr : 0|16@1+ (0.0025,0) [0|160.6375] "%" Vector__XXX

BO_ 2633825534 EMAC: 8 Vector__XXX
 SG_ EngExhstMnfldBnk2FlwBlncVlv_0000 : 16|16@1+ (0.0025,0) [0|160.6375] "%" Vector__XXX
 SG_ EngExhstMnfldBnk1FlwBlncVlv_0000 : 0|16@1+ (0.0025,0) [0|160.6375] "%" Vector__XXX

BO_ 2365400574 EJM9: 8 Vector__XXX
 SG_ Jystck9GripXAxisDetentPosStatus : 54|2@1+ (1,0) [0|3] "" Vector__XXX
 SG_ Jystck9GripYAxisDetentPosStatus : 52|2@1+ (1,0) [0|3] "" Vector__XXX
 SG_ Jystck9ThetaAxisDetentPosStatus : 50|2@1+ (1,0) [0|3] "" Vector__XXX
 SG_ Joystick9ThetaAxisPos : 38|10@1+ (0.1,0) [0|102] "%" Vector__XXX
 SG_ Jystck9ThtAxsClckwsPstvPsStatus : 36|2@1+ (1,0) [0|3] "" Vector__XXX
 SG_ Jystck9ThtAxsCntrClckwsNgtvPsStt : 34|2@1+ (1,0) [0|3] "" Vector__XXX
 SG_ Jystck9ThtaAxisNeutralPosStatus : 32|2@1+ (1,0) [0|3] "" Vector__XXX
 SG_ Joystick9GripYAxisPos : 22|10@1+ (0.1,0) [0|102] "%" Vector__XXX
 SG_ Jystck9GrpYAxsLvrFrwrdPstvPsStts : 20|2@1+ (1,0) [0|3] "" Vector__XXX
 SG_ Jystck9GrpYAxsLvrBckNgtvPsSttus : 18|2@1+ (1,0) [0|3] "" Vector__XXX
 SG_ Jystck9GrpYAxisNeutralPosStatus : 16|2@1+ (1,0) [0|3] "" Vector__XXX
 SG_ Joystick9GripXAxisPos : 6|10@1+ (0.1,0) [0|102] "%" Vector__XXX
 SG_ Jystck9GrpXAxsLvrRghtPstvPsStts : 4|2@1+ (1,0) [0|3] "" Vector__XXX
 SG_ Jystck9GrpXAxsLvrLftNgtvPsSttus : 2|2@1+ (1,0) [0|3] "" Vector__XXX
 SG_ Jystck9GrpXAxisNeutralPosStatus : 0|2@1+ (1,0) [0|3] "" Vector__XXX

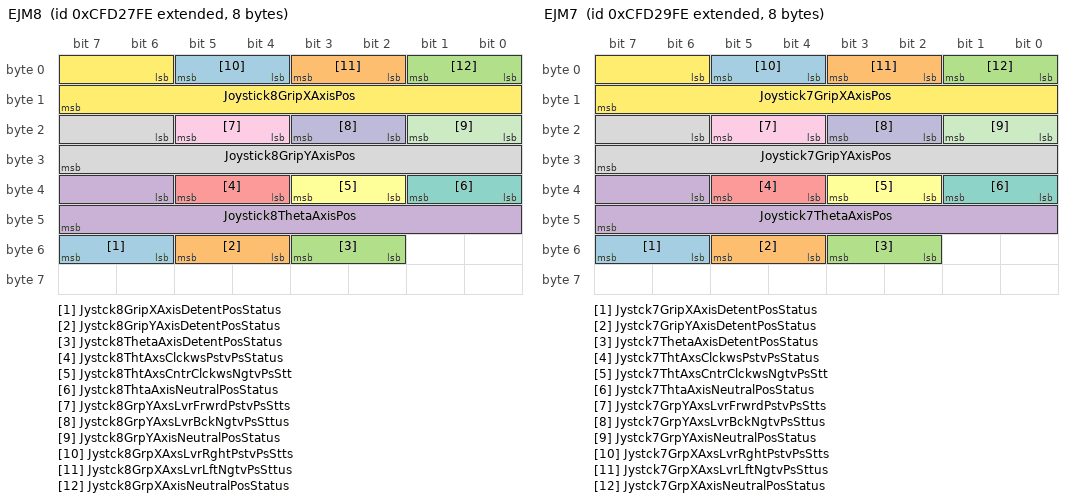
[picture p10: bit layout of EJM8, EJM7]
BO_ 2365401086 EJM8: 8 Vector__XXX
 SG_ Jystck8GripXAxisDetentPosStatus : 54|2@1+ (1,0) [0|3] "" Vector__XXX
 SG_ Jystck8GripYAxisDetentPosStatus : 52|2@1+ (1,0) [0|3] "" Vector__XXX
 SG_ Jystck8ThetaAxisDetentPosStatus : 50|2@1+ (1,0) [0|3] "" Vector__XXX
 SG_ Joystick8ThetaAxisPos : 38|10@1+ (0.1,0) [0|102] "%" Vector__XXX
 SG_ Jystck8ThtAxsClckwsPstvPsStatus : 36|2@1+ (1,0) [0|3] "" Vector__XXX
 SG_ Jystck8ThtAxsCntrClckwsNgtvPsStt : 34|2@1+ (1,0) [0|3] "" Vector__XXX
 SG_ Jystck8ThtaAxisNeutralPosStatus : 32|2@1+ (1,0) [0|3] "" Vector__XXX
 SG_ Joystick8GripYAxisPos : 22|10@1+ (0.1,0) [0|102] "%" Vector__XXX
 SG_ Jystck8GrpYAxsLvrFrwrdPstvPsStts : 20|2@1+ (1,0) [0|3] "" Vector__XXX
 SG_ Jystck8GrpYAxsLvrBckNgtvPsSttus : 18|2@1+ (1,0) [0|3] "" Vector__XXX
 SG_ Jystck8GrpYAxisNeutralPosStatus : 16|2@1+ (1,0) [0|3] "" Vector__XXX
 SG_ Joystick8GripXAxisPos : 6|10@1+ (0.1,0) [0|102] "%" Vector__XXX
 SG_ Jystck8GrpXAxsLvrRghtPstvPsStts : 4|2@1+ (1,0) [0|3] "" Vector__XXX
 SG_ Jystck8GrpXAxsLvrLftNgtvPsSttus : 2|2@1+ (1,0) [0|3] "" Vector__XXX
 SG_ Jystck8GrpXAxisNeutralPosStatus : 0|2@1+ (1,0) [0|3] "" Vector__XXX

BO_ 2365401598 EJM7: 8 Vector__XXX
 SG_ Jystck7GripXAxisDetentPosStatus : 54|2@1+ (1,0) [0|3] "" Vector__XXX
 SG_ Jystck7GripYAxisDetentPosStatus : 52|2@1+ (1,0) [0|3] "" Vector__XXX
 SG_ Jystck7ThetaAxisDetentPosStatus : 50|2@1+ (1,0) [0|3] "" Vector__XXX
 SG_ Joystick7ThetaAxisPos : 38|10@1+ (0.1,0) [0|102] "%" Vector__XXX
 SG_ Jystck7ThtAxsClckwsPstvPsStatus : 36|2@1+ (1,0) [0|3] "" Vector__XXX
 SG_ Jystck7ThtAxsCntrClckwsNgtvPsStt : 34|2@1+ (1,0) [0|3] "" Vector__XXX
 SG_ Jystck7ThtaAxisNeutralPosStatus : 32|2@1+ (1,0) [0|3] "" Vector__XXX
 SG_ Joystick7GripYAxisPos : 22|10@1+ (0.1,0) [0|102] "%" Vector__XXX
 SG_ Jystck7GrpYAxsLvrFrwrdPstvPsStts : 20|2@1+ (1,0) [0|3] "" Vector__XXX
 SG_ Jystck7GrpYAxsLvrBckNgtvPsSttus : 18|2@1+ (1,0) [0|3] "" Vector__XXX
 SG_ Jystck7GrpYAxisNeutralPosStatus : 16|2@1+ (1,0) [0|3] "" Vector__XXX
 SG_ Joystick7GripXAxisPos : 6|10@1+ (0.1,0) [0|102] "%" Vector__XXX
 SG_ Jystck7GrpXAxsLvrRghtPstvPsStts : 4|2@1+ (1,0) [0|3] "" Vector__XXX
 SG_ Jystck7GrpXAxsLvrLftNgtvPsSttus : 2|2@1+ (1,0) [0|3] "" Vector__XXX
 SG_ Jystck7GrpXAxisNeutralPosStatus : 0|2@1+ (1,0) [0|3] "" Vector__XXX

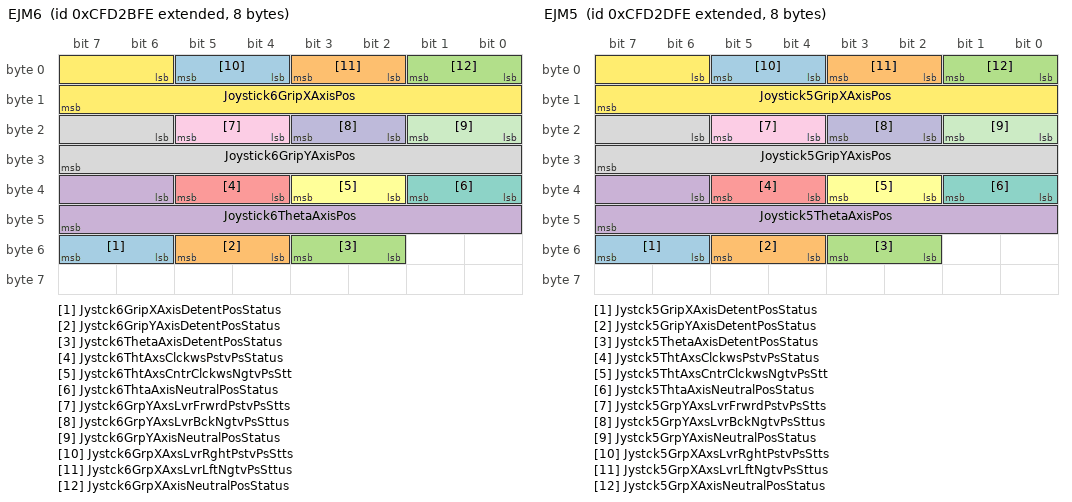
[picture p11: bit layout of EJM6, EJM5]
BO_ 2365402110 EJM6: 8 Vector__XXX
 SG_ Jystck6GripXAxisDetentPosStatus : 54|2@1+ (1,0) [0|3] "" Vector__XXX
 SG_ Jystck6GripYAxisDetentPosStatus : 52|2@1+ (1,0) [0|3] "" Vector__XXX
 SG_ Jystck6ThetaAxisDetentPosStatus : 50|2@1+ (1,0) [0|3] "" Vector__XXX
 SG_ Joystick6ThetaAxisPos : 38|10@1+ (0.1,0) [0|102] "%" Vector__XXX
 SG_ Jystck6ThtAxsClckwsPstvPsStatus : 36|2@1+ (1,0) [0|3] "" Vector__XXX
 SG_ Jystck6ThtAxsCntrClckwsNgtvPsStt : 34|2@1+ (1,0) [0|3] "" Vector__XXX
 SG_ Jystck6ThtaAxisNeutralPosStatus : 32|2@1+ (1,0) [0|3] "" Vector__XXX
 SG_ Joystick6GripYAxisPos : 22|10@1+ (0.1,0) [0|102] "%" Vector__XXX
 SG_ Jystck6GrpYAxsLvrFrwrdPstvPsStts : 20|2@1+ (1,0) [0|3] "" Vector__XXX
 SG_ Jystck6GrpYAxsLvrBckNgtvPsSttus : 18|2@1+ (1,0) [0|3] "" Vector__XXX
 SG_ Jystck6GrpYAxisNeutralPosStatus : 16|2@1+ (1,0) [0|3] "" Vector__XXX
 SG_ Joystick6GripXAxisPos : 6|10@1+ (0.1,0) [0|102] "%" Vector__XXX
 SG_ Jystck6GrpXAxsLvrRghtPstvPsStts : 4|2@1+ (1,0) [0|3] "" Vector__XXX
 SG_ Jystck6GrpXAxsLvrLftNgtvPsSttus : 2|2@1+ (1,0) [0|3] "" Vector__XXX
 SG_ Jystck6GrpXAxisNeutralPosStatus : 0|2@1+ (1,0) [0|3] "" Vector__XXX

BO_ 2365402622 EJM5: 8 Vector__XXX
 SG_ Jystck5GripXAxisDetentPosStatus : 54|2@1+ (1,0) [0|3] "" Vector__XXX
 SG_ Jystck5GripYAxisDetentPosStatus : 52|2@1+ (1,0) [0|3] "" Vector__XXX
 SG_ Jystck5ThetaAxisDetentPosStatus : 50|2@1+ (1,0) [0|3] "" Vector__XXX
 SG_ Joystick5ThetaAxisPos : 38|10@1+ (0.1,0) [0|102] "%" Vector__XXX
 SG_ Jystck5ThtAxsClckwsPstvPsStatus : 36|2@1+ (1,0) [0|3] "" Vector__XXX
 SG_ Jystck5ThtAxsCntrClckwsNgtvPsStt : 34|2@1+ (1,0) [0|3] "" Vector__XXX
 SG_ Jystck5ThtaAxisNeutralPosStatus : 32|2@1+ (1,0) [0|3] "" Vector__XXX
 SG_ Joystick5GripYAxisPos : 22|10@1+ (0.1,0) [0|102] "%" Vector__XXX
 SG_ Jystck5GrpYAxsLvrFrwrdPstvPsStts : 20|2@1+ (1,0) [0|3] "" Vector__XXX
 SG_ Jystck5GrpYAxsLvrBckNgtvPsSttus : 18|2@1+ (1,0) [0|3] "" Vector__XXX
 SG_ Jystck5GrpYAxisNeutralPosStatus : 16|2@1+ (1,0) [0|3] "" Vector__XXX
 SG_ Joystick5GripXAxisPos : 6|10@1+ (0.1,0) [0|102] "%" Vector__XXX
 SG_ Jystck5GrpXAxsLvrRghtPstvPsStts : 4|2@1+ (1,0) [0|3] "" Vector__XXX
 SG_ Jystck5GrpXAxsLvrLftNgtvPsSttus : 2|2@1+ (1,0) [0|3] "" Vector__XXX
 SG_ Jystck5GrpXAxisNeutralPosStatus : 0|2@1+ (1,0) [0|3] "" Vector__XXX

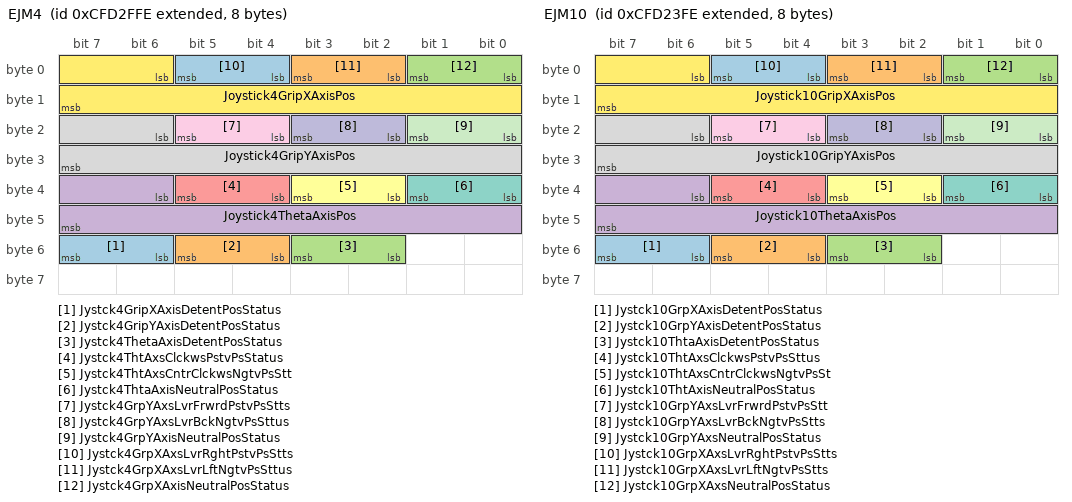
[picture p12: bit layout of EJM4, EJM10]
BO_ 2365403134 EJM4: 8 Vector__XXX
 SG_ Jystck4GripXAxisDetentPosStatus : 54|2@1+ (1,0) [0|3] "" Vector__XXX
 SG_ Jystck4GripYAxisDetentPosStatus : 52|2@1+ (1,0) [0|3] "" Vector__XXX
 SG_ Jystck4ThetaAxisDetentPosStatus : 50|2@1+ (1,0) [0|3] "" Vector__XXX
 SG_ Joystick4ThetaAxisPos : 38|10@1+ (0.1,0) [0|102] "%" Vector__XXX
 SG_ Jystck4ThtAxsClckwsPstvPsStatus : 36|2@1+ (1,0) [0|3] "" Vector__XXX
 SG_ Jystck4ThtAxsCntrClckwsNgtvPsStt : 34|2@1+ (1,0) [0|3] "" Vector__XXX
 SG_ Jystck4ThtaAxisNeutralPosStatus : 32|2@1+ (1,0) [0|3] "" Vector__XXX
 SG_ Joystick4GripYAxisPos : 22|10@1+ (0.1,0) [0|102] "%" Vector__XXX
 SG_ Jystck4GrpYAxsLvrFrwrdPstvPsStts : 20|2@1+ (1,0) [0|3] "" Vector__XXX
 SG_ Jystck4GrpYAxsLvrBckNgtvPsSttus : 18|2@1+ (1,0) [0|3] "" Vector__XXX
 SG_ Jystck4GrpYAxisNeutralPosStatus : 16|2@1+ (1,0) [0|3] "" Vector__XXX
 SG_ Joystick4GripXAxisPos : 6|10@1+ (0.1,0) [0|102] "%" Vector__XXX
 SG_ Jystck4GrpXAxsLvrRghtPstvPsStts : 4|2@1+ (1,0) [0|3] "" Vector__XXX
 SG_ Jystck4GrpXAxsLvrLftNgtvPsSttus : 2|2@1+ (1,0) [0|3] "" Vector__XXX
 SG_ Jystck4GrpXAxisNeutralPosStatus : 0|2@1+ (1,0) [0|3] "" Vector__XXX

BO_ 2365400062 EJM10: 8 Vector__XXX
 SG_ Jystck10GrpXAxisDetentPosStatus : 54|2@1+ (1,0) [0|3] "" Vector__XXX
 SG_ Jystck10GrpYAxisDetentPosStatus : 52|2@1+ (1,0) [0|3] "" Vector__XXX
 SG_ Jystck10ThtaAxisDetentPosStatus : 50|2@1+ (1,0) [0|3] "" Vector__XXX
 SG_ Joystick10ThetaAxisPos : 38|10@1+ (0.1,0) [0|102] "%" Vector__XXX
 SG_ Jystck10ThtAxsClckwsPstvPsSttus : 36|2@1+ (1,0) [0|3] "" Vector__XXX
 SG_ Jystck10ThtAxsCntrClckwsNgtvPsSt : 34|2@1+ (1,0) [0|3] "" Vector__XXX
 SG_ Jystck10ThtAxisNeutralPosStatus : 32|2@1+ (1,0) [0|3] "" Vector__XXX
 SG_ Joystick10GripYAxisPos : 22|10@1+ (0.1,0) [0|102] "%" Vector__XXX
 SG_ Jystck10GrpYAxsLvrFrwrdPstvPsStt : 20|2@1+ (1,0) [0|3] "" Vector__XXX
 SG_ Jystck10GrpYAxsLvrBckNgtvPsStts : 18|2@1+ (1,0) [0|3] "" Vector__XXX
 SG_ Jystck10GrpYAxsNeutralPosStatus : 16|2@1+ (1,0) [0|3] "" Vector__XXX
 SG_ Joystick10GripXAxisPos : 6|10@1+ (0.1,0) [0|102] "%" Vector__XXX
 SG_ Jystck10GrpXAxsLvrRghtPstvPsStts : 4|2@1+ (1,0) [0|3] "" Vector__XXX
 SG_ Jystck10GrpXAxsLvrLftNgtvPsStts : 2|2@1+ (1,0) [0|3] "" Vector__XXX
 SG_ Jystck10GrpXAxsNeutralPosStatus : 0|2@1+ (1,0) [0|3] "" Vector__XXX

BO_ 2566713598 EFS2: 8 Vector__XXX
 SG_ EngFuelFilterIntakeAbsPress : 0|8@1+ (2,0) [0|500] "kPa" Vector__XXX

BO_ 2499604478 EFL_P11: 8 Vector__XXX
 SG_ EngExhstGsRcrcltn1IntkeAbsPress : 0|16@1+ (0.1,0) [0|6425.5] "kPa" Vector__XXX

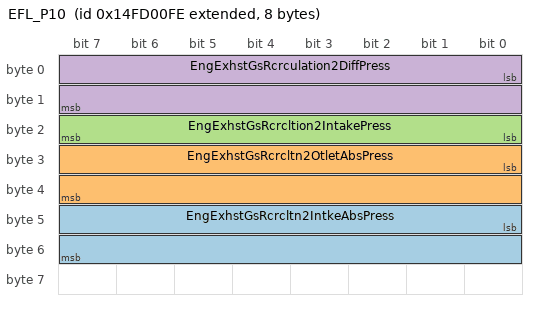
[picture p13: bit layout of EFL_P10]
BO_ 2499608830 EFL_P10: 8 Vector__XXX
 SG_ EngExhstGsRcrcltn2IntkeAbsPress : 40|16@1+ (0.1,0) [0|6425.5] "kPa" Vector__XXX
 SG_ EngExhstGsRcrcltn2OtletAbsPress : 24|16@1+ (0.1,0) [0|6425.5] "kPa" Vector__XXX
 SG_ EngExhstGsRcrcltion2IntakePress : 16|8@1+ (2,0) [0|500] "kPa" Vector__XXX
 SG_ EngExhstGsRcrculation2DiffPress : 0|16@1+ (0.0078125,-250) [-250|251.99] "kPa" Vector__XXX

CM_ BO_ 3221225472 "This is a message for not used signals, created by Vector CANdb++ DBC OLE DB Provider.";
CM_ SG_ 3221225472 TrailerWeight "Total mass of freight-carrying vehicle designed to be pulled by truck, including the weight of the contents.";
CM_ SG_ 3221225472 ReferenceTirePressSetting "Reference value of the tire pressure setting as basis for the tire pressure monitoring";
CM_ SG_ 3221225472 ReferenceTirePress "Reference value of the tire pressure as basis for the tire pressure monitoring";
CM_ SG_ 3221225472 TirePressThresholdDetection "Signal indicating the pressure level of the tire.";
CM_ SG_ 3221225472 TireAirLeakageRate "The pressure loss rate of a tire.";
CM_ SG_ 3221225472 CTIWheelEndElectricalFault "Indicates the status of electrical fault on CTI wheel interface.";
CM_ SG_ 3221225472 CTITireStatus "Indicates the status of the tire.";
CM_ SG_ 3221225472 CTIWheelSensorStatus "Indicates whether the wheel is being monitored by the CTI controller.";
CM_ SG_ 3221225472 TireTemp "Temperature at the surface of the tire sidewall.";
CM_ SG_ 3221225472 TirePress "Pressure at which air is contained in cavity formed by tire and rim.";
CM_ SG_ 3221225472 EngTorqueMode "State signal which indicates which engine torque mode is currently generating, limiting, or controlling the torque.";
CM_ SG_ 3221225472 EngTrqMd_Corrected "State signal which indicates which engine torque mode is currently generating, limiting, or controlling the torque.State signal which indicates which engine torque mode is currently generating, limiting, or controlling the torque.";
CM_ SG_ 3221225472 SrcAddrssOfCtrllngDvcFrEngCntrl "The source address of the SAE J1939 device currently controlling the engine.";
CM_ SG_ 3221225472 ActlEngPrcntTrqueHighResolution "This parameter displays an additional torque in percent of the reference engine torque.";
CM_ SG_ 3221225472 EngDemandPercentTorque "The requested torque output of the engine by all dynamic internal inputs, including smoke control, noise control and low";
CM_ SG_ 3221225472 EngStarterMode "There are several phases in a starting action and different reasons why a start cannot take place.";
CM_ SG_ 3221225472 EngSpeed "Actual engine speed which is calculated over a minimum crankshaft angle of 720 degrees divided by the number of cylinders.";
CM_ SG_ 3221225472 ActualEngPercentTorque "The calculated output torque of the engine.";
CM_ SG_ 3221225472 DriversDemandEngPercentTorque "The requested torque output of the engine by the driver.";
CM_ SG_ 3221225472 MessageCounter "The message counter is used to detect situations where the transmitting ECU malfunction repeats the same frame all the time.";
CM_ SG_ 3221225472 ControlPurpose "State signal which indicates which control mode the sending device is using to generate the TSC1 command.";
CM_ SG_ 3221225472 TransmissionRate "This parameter indicates the transmission rate at which the sending device will transmit the TSC1 message.";
CM_ SG_ 3221225472 EngRqedTorque_TorqueLimit "Parameter provided to the engine or retarder in the torque/speed control message for controlling or limiting the output torque.";
CM_ SG_ 3221225472 EngRqedSpeed_SpeedLimit "Parameter provided to the engine from external sources in the torque/speed control message.";
CM_ SG_ 3221225472 EngRqedSpeedCtrlConditions "This mode tells the engine control system the governor characteristics that are desired during speed control.";
CM_ SG_ 3221225472 MessageChecksum "The checksum is used to verify the signal path from the transmitting device to the receiving device.";
CM_ SG_ 3221225472 EngineRequestedTorqueHiRes "This parameter displays an additional torque in percent of the reference engine torque.";
CM_ SG_ 3221225472 TransCurrentRange "Range currently being commanded by the transmission control system.";
CM_ SG_ 3221225472 TransRqedRange "Range selected by the operator.";
CM_ SG_ 3221225472 TransCurrentGear "The gear currently engaged in the transmission or the last gear engaged while the transmission is in the process of";
CM_ SG_ 3221225472 TransActualGearRatio "Actual ratio of input shaft speed to output shaft speed.";
CM_ SG_ 3221225472 TransSelectedGear "The gear that the transmission will attempt to achieve during the current shift if a shift is in progress, or the next shift if one";
CM_ SG_ 3221225472 TrnsTrqueConverterLockupEngaged "State signal which indicates whether the torque converter lockup is engaged.";
CM_ SG_ 3221225472 TrnsTrqCnvrtrLckpTrnstnInPrcess "State signal indicating whether or not the transmission torque converter lock up clutch is transitioning between being";
CM_ SG_ 3221225472 SrcAddrssOfCtrllngDvcFrTrnsCntrl "The source address of the SAE J1939 device currently controlling the transmission.";
CM_ SG_ 3221225472 MomentaryEngMaxPowerEnable "Momentarily Requesting highest torque map from the engine control";
CM_ SG_ 3221225472 TransInputShaftSpeed "Rotational velocity of the primary shaft transferring power into the transmission.";
CM_ SG_ 3221225472 ProgressiveShiftDisable "Command signal used to indicate that progressive shifting by the engine should be disallowed.";
CM_ SG_ 3221225472 EngMomentaryOverspeedEnable "Command signal used to indicate that the engine speed may be boosted up to the maximum engine overspeed value to";
CM_ SG_ 3221225472 PercentClutchSlip "Parameter which represents the ratio of input shaft speed to current engine speed (in percent).";
CM_ SG_ 3221225472 TransOutputShaftSpeed "Calculated speed of the transmission output shaft.";
CM_ SG_ 3221225472 TransShiftInProcess "Indicates that the transmission is in process of shifting from the current gear to the selected gear.";
CM_ SG_ 3221225472 TransDrivelineEngaged "Driveline engaged indicates the transmission controlled portion of the driveline is engaged sufficiently to allow a transfer";
CM_ BO_ 2348810247 "Torque/Speed Control 1";
CM_ SG_ 2348810247 MessageCounter "The message counter is used to detect situations where the transmitting ECU malfunction repeats the same frame all the time.";
CM_ SG_ 2348810247 ControlPurpose "State signal which indicates which control mode the sending device is using to generate the TSC1 command.";
CM_ SG_ 2348810247 TransmissionRate "This parameter indicates the transmission rate at which the sending device will transmit the TSC1 message.";
CM_ SG_ 2348810247 EngRqedTorque_TorqueLimit "Parameter provided to the engine or retarder in the torque/speed control message for controlling or limiting the output torque.";
CM_ SG_ 2348810247 EngRqedSpeed_SpeedLimit "Parameter provided to the engine from external sources in the torque/speed control message.";
CM_ SG_ 2348810247 EngRqedSpeedCtrlConditions "This mode tells the engine control system the governor characteristics that are desired during speed control.";
CM_ SG_ 2348810247 MessageChecksum "The checksum is used to verify the signal path from the transmitting device to the receiving device.";
CM_ SG_ 2348810247 EngineRequestedTorqueHiRes "This parameter displays an additional torque in percent of the reference engine torque.";
CM_ BO_ 2348814083 "Torque/Speed Control 1";
CM_ SG_ 2348814083 MessageCounter "The message counter is used to detect situations where the transmitting ECU malfunction repeats the same frame all the time.";
CM_ SG_ 2348814083 ControlPurpose "State signal which indicates which control mode the sending device is using to generate the TSC1 command.";
CM_ SG_ 2348814083 TransmissionRate "This parameter indicates the transmission rate at which the sending device will transmit the TSC1 message.";
CM_ SG_ 2348814083 EngRqedTorque_TorqueLimit "Parameter provided to the engine or retarder in the torque/speed control message for controlling or limiting the output torque.";
CM_ SG_ 2348814083 EngRqedSpeed_SpeedLimit "Parameter provided to the engine from external sources in the torque/speed control message.";
CM_ SG_ 2348814083 EngRqedSpeedCtrlConditions "This mode tells the engine control system the governor characteristics that are desired during speed control.";
CM_ SG_ 2348814083 MessageChecksum "The checksum is used to verify the signal path from the transmitting device to the receiving device.";
CM_ SG_ 2348814083 EngineRequestedTorqueHiRes "This parameter displays an additional torque in percent of the reference engine torque.";
CM_ BO_ 2565866755 "Electronic Transmission Controller 2";
CM_ SG_ 2565866755 TransCurrentRange "Range currently being commanded by the transmission control system.";
CM_ SG_ 2565866755 TransRqedRange "Range selected by the operator.";
CM_ SG_ 2565866755 TransCurrentGear "The gear currently engaged in the transmission or the last gear engaged while the transmission is in the process of";
CM_ SG_ 2565866755 TransActualGearRatio "Actual ratio of input shaft speed to output shaft speed.";
CM_ SG_ 2565866755 TransSelectedGear "The gear that the transmission will attempt to achieve during the current shift if a shift is in progress, or the next shift if one";
CM_ BO_ 2364539395 "Electronic Transmission Controller 1";
CM_ SG_ 2364539395 TrnsTrqueConverterLockupEngaged "State signal which indicates whether the torque converter lockup is engaged.";
CM_ SG_ 2364539395 TrnsTrqCnvrtrLckpTrnstnInPrcess "State signal indicating whether or not the transmission torque converter lock up clutch is transitioning between being";
CM_ SG_ 2364539395 SrcAddrssOfCtrllngDvcFrTrnsCntrl "The source address of the SAE J1939 device currently controlling the transmission.";
CM_ SG_ 2364539395 MomentaryEngMaxPowerEnable "Momentarily Requesting highest torque map from the engine control";
CM_ SG_ 2364539395 TransInputShaftSpeed "Rotational velocity of the primary shaft transferring power into the transmission.";
CM_ SG_ 2364539395 ProgressiveShiftDisable "Command signal used to indicate that progressive shifting by the engine should be disallowed.";
CM_ SG_ 2364539395 EngMomentaryOverspeedEnable "Command signal used to indicate that the engine speed may be boosted up to the maximum engine overspeed value to";
CM_ SG_ 2364539395 PercentClutchSlip "Parameter which represents the ratio of input shaft speed to current engine speed (in percent).";
CM_ SG_ 2364539395 TransOutputShaftSpeed "Calculated speed of the transmission output shaft.";
CM_ SG_ 2364539395 TransShiftInProcess "Indicates that the transmission is in process of shifting from the current gear to the selected gear.";
CM_ SG_ 2364539395 TransDrivelineEngaged "Driveline engaged indicates the transmission controlled portion of the driveline is engaged sufficiently to allow a transfer";
CM_ BO_ 2348810243 "Torque/Speed Control 1";
CM_ SG_ 2348810243 MessageCounter "The message counter is used to detect situations where the transmitting ECU malfunction repeats the same frame all the time.";
CM_ SG_ 2348810243 ControlPurpose "State signal which indicates which control mode the sending device is using to generate the TSC1 command.";
CM_ SG_ 2348810243 TransmissionRate "This parameter indicates the transmission rate at which the sending device will transmit the TSC1 message.";
CM_ SG_ 2348810243 EngRqedTorque_TorqueLimit "Parameter provided to the engine or retarder in the torque/speed control message for controlling or limiting the output torque.";
CM_ SG_ 2348810243 EngRqedSpeed_SpeedLimit "Parameter provided to the engine from external sources in the torque/speed control message.";
CM_ SG_ 2348810243 EngRqedSpeedCtrlConditions "This mode tells the engine control system the governor characteristics that are desired during speed control.";
CM_ SG_ 2348810243 MessageChecksum "The checksum is used to verify the signal path from the transmitting device to the receiving device.";
CM_ SG_ 2348810243 EngineRequestedTorqueHiRes "This parameter displays an additional torque in percent of the reference engine torque.";
CM_ BO_ 2297441790 "The acceleration sensor message shall provide a measurement of the vehicle's acceleration in the lateral, longitudinal,
and vertical axes.";
CM_ SG_ 2297441790 SpprtVrblTrnsRpttnRtFrAcclrtnSns "Indicates which acceleration transmission rate are supported by the ECU in addition to the required 10 ms transmission";
CM_ SG_ 2297441790 VrtclAcclrtnExRngeFigureOfMerit "Figure of merit for vertical acceleration measurement.";
CM_ SG_ 2297441790 LngtdnlAcclrtnExRngFgureOfMerit "Figure of merit for longitudinal acceleration measurement.";
CM_ SG_ 2297441790 LtrlAcclrtnExRangeFigureOfMerit "Figure of merit for lateral acceleration measurement.";
CM_ SG_ 2297441790 VerticalAccelerationExRange "Indicates vertical acceleration of the vehicle and the effect of gravity.";
CM_ SG_ 2297441790 LateralAccelerationExRange "Indicates lateral acceleration of the vehicle.";
CM_ SG_ 2297441790 LongitudinalAccelerationExRange "Indicates longitudinal acceleration of the vehicle.";
CM_ BO_ 2566712062 "Vehicle Electrical Power #4";
CM_ SG_ 2566712062 HybrdBatteryPackRemainingCharge "Indicates the hybrid battery pack remaining charge.";
CM_ BO_ 2364549630 "Slope Sensor Information 2";
CM_ SG_ 2364549630 RllAndPtchExRngMsurementLatency "Time between start of sensor processing and CAN transmission";
CM_ SG_ 2364549630 RollAngleExRangeFigureOfMerit "Figure of merit for roll angle measurement.";
CM_ SG_ 2364549630 RollAngleExRangeCompensation "Compensated mode for the roll measurement.";
CM_ SG_ 2364549630 PitchAngleExRangeFigureOfMerit "Figure of merit for pitch angle measurement.";
CM_ SG_ 2364549630 PitchAngleExRangeCompensation "Compensated mode for the pitch measurement.";
CM_ SG_ 2364549630 RollAngleExRange "The angle between the vehicle y-axis and the ground plane.";
CM_ SG_ 2364549630 PitchAngleExRange "The angle between the vehicle x-axis and the ground plane.";
CM_ BO_ 2499614462 "Occupant Classification System Information";
CM_ SG_ 2499614462 OccpntClssfcationSystem10Status "State of Occupant Classification System for seat position 10.";
CM_ SG_ 2499614462 OccpntClssficationSystem9Status "State of Occupant Classification System for seat position 9.";
CM_ SG_ 2499614462 OccpntClssficationSystem8Status "State of Occupant Classification System for seat position 8.";
CM_ SG_ 2499614462 OccpntClssficationSystem7Status "State of Occupant Classification System for seat position 7.";
CM_ SG_ 2499614462 OccpntClssficationSystem6Status "State of Occupant Classification System for seat position 6.";
CM_ SG_ 2499614462 OccpntClssficationSystem5Status "State of Occupant Classification System for seat position 5.";
CM_ SG_ 2499614462 OccpntClssficationSystem4Status "State of Occupant Classification System for seat position 4.";
CM_ SG_ 2499614462 OccpntClssficationSystem3Status "State of Occupant Classification System for seat position 3.";
CM_ SG_ 2499614462 PssngrOccpntClssfctnSystmStatus "State of Occupant Classification System for passenger.";
CM_ SG_ 2499614462 DrvrOccpntClssfctonSystemStatus "State of Occupant Classification System for driver.";
CM_ BO_ 2560098046 "Noise Control Status";
CM_ SG_ 2560098046 CabNoiseCtrlTuningStatus "This parameter returns the current status of tuning function of the Cab Noise Control system.";
CM_ SG_ 2560098046 CabNoiseCtrlStatus "This parameter returns the current status of the Cab Noise Control system.";
CM_ BO_ 2560163582 "Noise Control 1";
CM_ SG_ 2560163582 CabNoiseCtrlTuningState "Command values for the Tuning State of the Cab Noise Control System.";
CM_ SG_ 2560163582 CabNoiseCtrlState "Command signal to change the state of the Cab Noise Control System to on-line or off-line";
CM_ BO_ 2297441534 "Magnet Status Information 2";
CM_ SG_ 2297441534 DropRelayCtrl "Command signal used to Engage and Disengage the Drop Relay controlling a Steady-State Magnet.";
CM_ SG_ 2297441534 LiftRelayCtrl "Command signal used to Engage and Disengage the Lift Relay controlling a Steady-State Magnet.";
CM_ SG_ 2297441534 MaterialDropActiveStatus "The status of Material Drop Relay.";
CM_ SG_ 2297441534 MaterialLiftActiveStatus "The status of Material Lift Relay.";
CM_ SG_ 2297441534 GnratorCurrentBoostActiveStatus "Status of generator current boost relay that can boost the generator output current for picking-up material operations.";
CM_ SG_ 2297441534 MaterialDropSwitch "This is a switch that can be used to enable the drop functionality of the Material Handler machine.";
CM_ SG_ 2297441534 MaterialLiftSwitch "This is a switch that can be used to enable the lift functionality of the Material Handler machine.";
CM_ SG_ 2297441534 MagnetReverseCurrent "A reverse current being supplied to the electric magnet to reduce the forward current generated magnet field as quick as";
CM_ SG_ 2297441534 MagnetForwardCurrent "The forward current being supplied by the generator to the electric magnet to create a magnet field to lift material.";
CM_ BO_ 2566722302 "Magnet Status Information 1";
CM_ SG_ 2566722302 GneratorDutyCycleExceededStatus "The status of the duty cycle of the generator usage, indicating if the generator has been on for too much time within a";
CM_ SG_ 2566722302 VoltageMonitorActiveStatus "Status of Voltage Monitor Relay.";
CM_ SG_ 2566722302 GensetEnableActiveStatus "Status of the Genset Enable Relay that enables or disables the Genset.";
CM_ SG_ 2566722302 ReverseCurrentRangeSetting "The operator setting for the Reverse Current.";
CM_ SG_ 2566722302 GensetSoftstartActiveStatus "The Genset Softstart Active Status refers to the status of the genset softstart relay.";
CM_ SG_ 2566722302 Grapple_MagnetSelectionSwitch "This is a switch that can be used to select either the Grapple or Magnet function of the material handler machine.";
CM_ SG_ 2566722302 GnstSystmOtptVoltageRangeStatus "Status of generator voltage in or out of desired operating range.";
CM_ SG_ 2566722302 GeneratorOverheatStatus "The Status of Generator being Overheated.";
CM_ BO_ 2566722558 "Magnet System Configuration Information";
CM_ SG_ 2566722558 MagnetRatedPower "The rated power that the magnet can accept during material holding operations.";
CM_ SG_ 2566722558 MagnetBoostTime "The duration of time after the activation of the magnet circuit that a relatively high current is sent to the magnet for";
CM_ BO_ 2560032510 "Low Voltage Disconnect Set Operating Mode";
CM_ SG_ 2560032510 LwVltgDscnnctDsredOperatingMode "Desired Operating Mode of the LVD.";
CM_ BO_ 2566717950 "Low Voltage Disconnect Status";
CM_ SG_ 2566717950 LowVoltageDisconnectTemp "Internal temperature of the LVD.";
CM_ SG_ 2566717950 LwVltgDisconnectVoutOutputState "State of the Vout Output from the LVD.";
CM_ SG_ 2566717950 LwVoltageDisconnectOutput1State "State of the Output #1 from the LVD.";
CM_ SG_ 2566717950 LwVoltageDisconnectOutput2State "State of the Output #2 from the LVD.";
CM_ SG_ 2566717950 LwVoltageDisconnectOutput3State "State of the Output #3 from the LVD.";
CM_ SG_ 2566717950 LwVltgDscnnctCrrntOperatingMode "Current operating mode of the LVD.";
CM_ SG_ 2566717950 LwVltgDscnnctManualConnectState "State of the Manual Connect hardwired input to the LVD.";
CM_ SG_ 2566717950 LwVltgDscnnctMnlDisconnectState "State of the Manual Disconnect hardwired input to the LVD.";
CM_ BO_ 2499604222 "Land Leveling System Reference Elevation Data";
CM_ SG_ 2499604222 BldRferenceElevationOffsetRight "Indicates the blade's right elevation offset with respect to the reference elevation.";
CM_ SG_ 2499604222 BldReferenceElevationOffsetLeft "Indicates the blade's left elevation offset with respect to the reference elevation.";
CM_ SG_ 2499604222 BladeElevationDeviationRight "Indicate the blade's right elevation deviation with respect to the reference elevation.";
CM_ SG_ 2499604222 BladeElevationDeviationLeft "Indicate the blade's left elevation deviation with respect to the reference elevation.";
CM_ BO_ 2358902526 "Joystick Lamp Command Message";
CM_ SG_ 2358902526 Joystick3Lamp10Cmd "Tells joystick 3 to switch on/off/blinking lamp 10.";
CM_ SG_ 2358902526 Joystick3Lamp9Cmd "Tells joystick 3 to switch on/off/blinking lamp 9.";
CM_ SG_ 2358902526 Joystick3Lamp8Cmd "Tells joystick 3 to switch on/off/blinking lamp 8.";
CM_ SG_ 2358902526 Joystick3Lamp7Cmd "Tells joystick 3 to switch on/off/blinking lamp 7.";
CM_ SG_ 2358902526 Joystick3Lamp6Cmd "Tells joystick 3 to switch on/off/blinking lamp 6.";
CM_ SG_ 2358902526 Joystick3Lamp5Cmd "Tells joystick 3 to switch on/off/blinking lamp 5.";
CM_ SG_ 2358902526 Joystick3Lamp4Cmd "Tells joystick 3 to switch on/off/blinking lamp 4.";
CM_ SG_ 2358902526 Joystick3Lamp3Cmd "Tells joystick 3 to switch on/off/blinking lamp 3.";
CM_ SG_ 2358902526 Joystick3Lamp2Cmd "Tells joystick 3 to switch on/off/blinking lamp 2.";
CM_ SG_ 2358902526 Joystick3Lamp1Cmd "Tells joystick 3 to switch on/off/blinking lamp 1.";
CM_ SG_ 2358902526 Joystick2Lamp10Cmd "Tells joystick 2 to switch on/off/blinking lamp 10.";
CM_ SG_ 2358902526 Joystick2Lamp9Cmd "Tells joystick 2 to switch on/off/blinking lamp 9.";
CM_ SG_ 2358902526 Joystick2Lamp8Cmd "Tells joystick 2 to switch on/off/blinking lamp 8.";
CM_ SG_ 2358902526 Joystick2Lamp7Cmd "Tells joystick 2 to switch on/off/blinking lamp 7.";
CM_ SG_ 2358902526 Joystick2Lamp6Cmd "Tells joystick 2 to switch on/off/blinking lamp 6.";
CM_ SG_ 2358902526 Joystick2Lamp5Cmd "Tells joystick 2 to switch on/off/blinking lamp 5.";
CM_ SG_ 2358902526 Joystick2Lamp4Cmd "Tells joystick 2 to switch on/off/blinking lamp 4.";
CM_ SG_ 2358902526 Joystick2Lamp3Cmd "Tells joystick 2 to switch on/off/blinking lamp 3.";
CM_ SG_ 2358902526 Joystick2Lamp2Cmd "Tells joystick 2 to switch on/off/blinking lamp 2.";
CM_ SG_ 2358902526 Joystick2Lamp1Cmd "Tells joystick 2 to switch on/off/blinking lamp 1.";
CM_ SG_ 2358902526 Joystick1Lamp10Cmd "Tells joystick 1 to switch on/off/blinking lamp 10.";
CM_ SG_ 2358902526 Joystick1Lamp9Cmd "Tells joystick 1 to switch on/off/blinking lamp 9.";
CM_ SG_ 2358902526 Joystick1Lamp8Cmd "Tells joystick 1 to switch on/off/blinking lamp 8.";
CM_ SG_ 2358902526 Joystick1Lamp7Cmd "Tells joystick 1 to switch on/off/blinking lamp 7.";
CM_ SG_ 2358902526 Joystick1Lamp6Cmd "Tells joystick 1 to switch on/off/blinking lamp 6.";
CM_ SG_ 2358902526 Joystick1Lamp5Cmd "Tells joystick 1 to switch on/off/blinking lamp 5.";
CM_ SG_ 2358902526 Joystick1Lamp4Cmd "Tells joystick 1 to switch on/off/blinking lamp 4.";
CM_ SG_ 2358902526 Joystick1Lamp3Cmd "Tells joystick 1 to switch on/off/blinking lamp 3.";
CM_ SG_ 2358902526 Joystick1Lamp2Cmd "Tells joystick 1 to switch on/off/blinking lamp 2.";
CM_ SG_ 2358902526 Joystick1Lamp1Cmd "Tells joystick 1 to switch on/off/blinking lamp 1.";
CM_ BO_ 2566711550 "Intake Valve Actuation Control";
CM_ SG_ 2566711550 IntkVlvActtnSystmOlPrss2SlndCtrl "Indicates the current command to the solenoid that controls the intake valve actuation system oil pressure 2 valve.";
CM_ SG_ 2566711550 IntkVlvActtnSystmOlPrss1SlndCtrl "Indicates the current command to the solenoid that controls the intake valve actuation system oil pressure 1 valve.";
CM_ BO_ 2633832958 "Ignitor Loop Information";
CM_ SG_ 2633832958 SpecialIgnitorLoop90Resistance "Resistance of Special Ignitor Loop 90.";
CM_ SG_ 2633832958 SpecialIgnitorLoop89Resistance "Resistance of Special Ignitor Loop 89.";
CM_ SG_ 2633832958 SpecialIgnitorLoop88Resistance "Resistance of Special Ignitor Loop 88.";
CM_ SG_ 2633832958 SpecialIgnitorLoop87Resistance "Resistance of Special Ignitor Loop 87.";
CM_ SG_ 2633832958 SpecialIgnitorLoop86Resistance "Resistance of Special Ignitor Loop 86.";
CM_ SG_ 2633832958 SpecialIgnitorLoop85Resistance "Resistance of Special Ignitor Loop 85.";
CM_ SG_ 2633832958 SpecialIgnitorLoop84Resistance "Resistance of Special Ignitor Loop 84.";
CM_ SG_ 2633832958 SpecialIgnitorLoop83Resistance "Resistance of Special Ignitor Loop 83.";
CM_ SG_ 2633832958 SpecialIgnitorLoop82Resistance "Resistance of Special Ignitor Loop 82.";
CM_ SG_ 2633832958 SpecialIgnitorLoop81Resistance "Resistance of Special Ignitor Loop 81.";
CM_ SG_ 2633832958 SpecialIgnitorLoop80Resistance "Resistance of Special Ignitor Loop 80.";
CM_ SG_ 2633832958 SpecialIgnitorLoop79Resistance "Resistance of Special Ignitor Loop 79.";
CM_ SG_ 2633832958 SpecialIgnitorLoop78Resistance "Resistance of Special Ignitor Loop 78.";
CM_ SG_ 2633832958 SpecialIgnitorLoop77Resistance "Resistance of Special Ignitor Loop 77.";
CM_ SG_ 2633832958 SpecialIgnitorLoop76Resistance "Resistance of Special Ignitor Loop 76.";
CM_ SG_ 2633832958 SpecialIgnitorLoop75Resistance "Resistance of Special Ignitor Loop 75.";
CM_ SG_ 2633832958 SpecialIgnitorLoop74Resistance "Resistance of Special Ignitor Loop 74.";
CM_ SG_ 2633832958 SpecialIgnitorLoop73Resistance "Resistance of Special Ignitor Loop 73.";
CM_ SG_ 2633832958 SpecialIgnitorLoop72Resistance "Resistance of Special Ignitor Loop 72.";
CM_ SG_ 2633832958 SpecialIgnitorLoop71Resistance "Resistance of Special Ignitor Loop 71.";
CM_ SG_ 2633832958 SpecialIgnitorLoop70Resistance "Resistance of Special Ignitor Loop 70.";
CM_ SG_ 2633832958 SpecialIgnitorLoop69Resistance "Resistance of Special Ignitor Loop 69.";
CM_ SG_ 2633832958 SpecialIgnitorLoop68Resistance "Resistance of Special Ignitor Loop 68.";
CM_ SG_ 2633832958 SpecialIgnitorLoop67Resistance "Resistance of Special Ignitor Loop 67.";
CM_ SG_ 2633832958 SpecialIgnitorLoop66Resistance "Resistance of Special Ignitor Loop 66.";
CM_ SG_ 2633832958 SpecialIgnitorLoop65Resistance "Resistance of Special Ignitor Loop 65.";
CM_ SG_ 2633832958 SpecialIgnitorLoop64Resistance "Resistance of Special Ignitor Loop 64.";
CM_ SG_ 2633832958 SpecialIgnitorLoop63Resistance "Resistance of Special Ignitor Loop 63.";
CM_ SG_ 2633832958 SpecialIgnitorLoop61Resistance "Resistance of Special Ignitor Loop 61.";
CM_ SG_ 2633832958 SpecialIgnitorLoop60Resistance "Resistance of Special Ignitor Loop 60.";
CM_ SG_ 2633832958 SpecialIgnitorLoop59Resistance "Resistance of Special Ignitor Loop 59.";
CM_ SG_ 2633832958 SpecialIgnitorLoop58Resistance "Resistance of Special Ignitor Loop 58.";
CM_ SG_ 2633832958 SpecialIgnitorLoop57Resistance "Resistance of Special Ignitor Loop 57.";
CM_ SG_ 2633832958 SpecialIgnitorLoop56Resistance "Resistance of Special Ignitor Loop 56.";
CM_ SG_ 2633832958 SpecialIgnitorLoop55Resistance "Resistance of Special Ignitor Loop 55.";
CM_ SG_ 2633832958 SpecialIgnitorLoop54Resistance "Resistance of Special Ignitor Loop 54.";
CM_ SG_ 2633832958 SpecialIgnitorLoop53Resistance "Resistance of Special Ignitor Loop 53.";
CM_ SG_ 2633832958 SpecialIgnitorLoop52Resistance "Resistance of Special Ignitor Loop 52.";
CM_ SG_ 2633832958 SpecialIgnitorLoop51Resistance "Resistance of Special Ignitor Loop 51.";
CM_ SG_ 2633832958 SpecialIgnitorLoop50Resistance "Resistance of Special Ignitor Loop 50.";
CM_ SG_ 2633832958 SpecialIgnitorLoop49Resistance "Resistance of Special Ignitor Loop 49.";
CM_ SG_ 2633832958 SpecialIgnitorLoop48Resistance "Resistance of Special Ignitor Loop 48.";
CM_ SG_ 2633832958 SpecialIgnitorLoop47Resistance "Resistance of Special Ignitor Loop 47.";
CM_ SG_ 2633832958 SpecialIgnitorLoop46Resistance "Resistance of Special Ignitor Loop 46.";
CM_ SG_ 2633832958 SpecialIgnitorLoop45Resistance "Resistance of Special Ignitor Loop 45.";
CM_ SG_ 2633832958 SpecialIgnitorLoop44Resistance "Resistance of Special Ignitor Loop 44.";
CM_ SG_ 2633832958 SpecialIgnitorLoop43Resistance "Resistance of Special Ignitor Loop 43.";
CM_ SG_ 2633832958 SpecialIgnitorLoop42Resistance "Resistance of Special Ignitor Loop 42.";
CM_ SG_ 2633832958 SpecialIgnitorLoop41Resistance "Resistance of Special Ignitor Loop 41.";
CM_ SG_ 2633832958 SpecialIgnitorLoop40Resistance "Resistance of Special Ignitor Loop 40.";
CM_ SG_ 2633832958 SpecialIgnitorLoop39Resistance "Resistance of Special Ignitor Loop 39.";
CM_ SG_ 2633832958 SpecialIgnitorLoop38Resistance "Resistance of Special Ignitor Loop 38.";
CM_ SG_ 2633832958 SpecialIgnitorLoop37Resistance "Resistance of Special Ignitor Loop 37.";
CM_ SG_ 2633832958 SpecialIgnitorLoop36Resistance "Resistance of Special Ignitor Loop 36.";
CM_ SG_ 2633832958 SpecialIgnitorLoop35Resistance "Resistance of Special Ignitor Loop 35.";
CM_ SG_ 2633832958 SpecialIgnitorLoop34Resistance "Resistance of Special Ignitor Loop 34.";
CM_ SG_ 2633832958 SpecialIgnitorLoop33Resistance "Resistance of Special Ignitor Loop 33.";
CM_ SG_ 2633832958 SpecialIgnitorLoop32Resistance "Resistance of Special Ignitor Loop 32.";
CM_ SG_ 2633832958 SpecialIgnitorLoop31Resistance "Resistance of Special Ignitor Loop 31.";
CM_ SG_ 2633832958 SpecialIgnitorLoop30Resistance "Resistance of Special Ignitor Loop 30.";
CM_ SG_ 2633832958 SpecialIgnitorLoop29Resistance "Resistance of Special Ignitor Loop 29.";
CM_ SG_ 2633832958 SpecialIgnitorLoop28Resistance "Resistance of Special Ignitor Loop 28.";
CM_ SG_ 2633832958 SpecialIgnitorLoop27Resistance "Resistance of Special Ignitor Loop 27.";
CM_ SG_ 2633832958 SpecialIgnitorLoop26Resistance "Resistance of Special Ignitor Loop 26.";
CM_ SG_ 2633832958 SpecialIgnitorLoop25Resistance "Resistance of Special Ignitor Loop 25.";
CM_ SG_ 2633832958 SpecialIgnitorLoop24Resistance "Resistance of Special Ignitor Loop 24.";
CM_ SG_ 2633832958 SpecialIgnitorLoop23Resistance "Resistance of Special Ignitor Loop 23.";
CM_ SG_ 2633832958 SpecialIgnitorLoop22Resistance "Resistance of Special Ignitor Loop 22.";
CM_ SG_ 2633832958 SpecialIgnitorLoop21Resistance "Resistance of Special Ignitor Loop 21.";
CM_ SG_ 2633832958 SpecialIgnitorLoop20Resistance "Resistance of Special Ignitor Loop 20.";
CM_ SG_ 2633832958 SpecialIgnitorLoop19Resistance "Resistance of Special Ignitor Loop 19.";
CM_ SG_ 2633832958 SpecialIgnitorLoop18Resistance "Resistance of Special Ignitor Loop 18.";
CM_ SG_ 2633832958 SpecialIgnitorLoop17Resistance "Resistance of Special Ignitor Loop 17.";
CM_ SG_ 2633832958 SpecialIgnitorLoop16Resistance "Resistance of Special Ignitor Loop 16.";
CM_ SG_ 2633832958 SpecialIgnitorLoop15Resistance "Resistance of Special Ignitor Loop 15.";
CM_ SG_ 2633832958 SpecialIgnitorLoop14Resistance "Resistance of Special Ignitor Loop 14.";
CM_ SG_ 2633832958 SpecialIgnitorLoop13Resistance "Resistance of Special Ignitor Loop 13.";
CM_ SG_ 2633832958 SpecialIgnitorLoop12Resistance "Resistance of Special Ignitor Loop 12.";
CM_ SG_ 2633832958 SpecialIgnitorLoop11Resistance "Resistance of Special Ignitor Loop 11.";
CM_ SG_ 2633832958 SpecialIgnitorLoop10Resistance "Resistance of Special Ignitor Loop 10.";
CM_ SG_ 2633832958 SpecialIgnitorLoop9Resistance "Resistance of Special Ignitor Loop 9.";
CM_ SG_ 2633832958 SpecialIgnitorLoop8Resistance "Resistance of Special Ignitor Loop 8.";
CM_ SG_ 2633832958 SpecialIgnitorLoop7Resistance "Resistance of Special Ignitor Loop 7.";
CM_ SG_ 2633832958 SpecialIgnitorLoop6Resistance "Resistance of Special Ignitor Loop 6.";
CM_ SG_ 2633832958 SpecialIgnitorLoop5Resistance "Resistance of Special Ignitor Loop 5.";
CM_ SG_ 2633832958 SpecialIgnitorLoop4Resistance "Resistance of Special Ignitor Loop 4.";
CM_ SG_ 2633832958 SpecialIgnitorLoop3Resistance "Resistance of Special Ignitor Loop 3.";
CM_ SG_ 2633832958 SpecialIgnitorLoop2Resistance "Resistance of Special Ignitor Loop 2.";
CM_ SG_ 2633832958 SpecialIgnitorLoop1Resistance "Resistance of Special Ignitor Loop 1.";
CM_ SG_ 2633832958 SdBgIgnitorLoop2RightResistance "Resistance of Side Bag Ignitor Loop 2 - Right.";
CM_ SG_ 2633832958 SdBgIgnitorLoop1RightResistance "Resistance of Side Bag Ignitor Loop 1 - Right.";
CM_ SG_ 2633832958 SdBagIgnitorLoop2LeftResistance "Resistance of Side Bag Ignitor Loop 2 - Left.";
CM_ SG_ 2633832958 SdBagIgnitorLoop1LeftResistance "Resistance of Side Bag Ignitor Loop 1 - Left.";
CM_ SG_ 2633832958 PssngrBltTnsnrIgntrLpResistance "Resistance of Passenger Belt Tensioner Ignitor Loop 1st Stage.";
CM_ SG_ 2633832958 DrvrBltTnsnrIgntrLoopResistance "Resistance of Driver Belt Tensioner Ignitor Loop 1st Stage.";
CM_ SG_ 2633832958 PssngrArbgIgntrLp2ndStgRsstance "Resistance of Passenger Airbag Ignitor Loop 2nd Stage.";
CM_ SG_ 2633832958 DrvrArbgIgntrLp2ndStgResistance "Resistance of Driver Airbag Ignitor Loop 2nd Stage.";
CM_ SG_ 2633832958 PssngrArbgIgntrLp1stStgRsstance "Resistance of Passenger Airbag Ignitor Loop 1st Stage.";
CM_ SG_ 2633832958 DrvrArbgIgntrLp1stStgResistance "Resistance of Driver Airbag Ignitor Loop 1st Stage.";
CM_ BO_ 2566719998 "High Resolution Fuel Consumption (Liquid)";
CM_ SG_ 2566719998 HighResolutionEngTotalFuelUsed "Accumulated amount of fuel used during vehicle operation.";
CM_ SG_ 2566719998 HighResolutionEngTripFuel "Fuel consumed during all or part of a journey.";
CM_ BO_ 2565877502 "Engine Turbocharger Wastegate Actuator Control Command";
CM_ SG_ 2565877502 EngTurboWastegateActuator2Cmd "The command to a Turbocharger Wastegate actuator 2, normalized to percent, where 0% nominally represents fully";
CM_ SG_ 2565877502 EngTurboWastegateActuator1Cmd "The ccommand to a Turbocharger Wastegate actuator 1, normalized to percent, where 0% nominally represents fully";
CM_ BO_ 2566713854 "Engine Turbocharger Wastegate Actuator Information";
CM_ SG_ 2566713854 EngTrbWstgtActtr2OprationStatus "Used to identify the status of Engine Turbocharger Wastegate Actuator 2";
CM_ SG_ 2566713854 EngTrbWstgtActtr1OprationStatus "Used to identify the status of Engine Turbocharger Wastegate Actuator 1";
CM_ SG_ 2566713854 EngTrbWstgteActuator2TempStatus "Used to identify the status of the Engine Turbocharger Wastegate Actuator 2 drive circuitry temperature.";
CM_ SG_ 2566713854 EngTrbWstgtActtr2PreliminaryFMI "Used to identify the applicable J1939-73 FMI detected in the Engine Turbocharger Wastegate Actuator 2 by the";
CM_ BO_ 2566714366 "Engine Turbocharger Compressor Bypass Information";
CM_ SG_ 2566714366 EngTrbCmprssrBypssActtr2OprtnStt "Used to identify the status of Engine Turbocharger Compressor Bypass Actuator 2";
CM_ SG_ 2566714366 EngTrbCmprssrBypssActtr1OprtnStt "Used to identify the status of Engine Turbocharger Compressor Bypass Actuator 1";
CM_ SG_ 2566714366 EngTrbCmprssrBypssActtr2TmpStts "Used to identify the status of the Engine Turbocharger Compresssor Bypass Actuator 2 drive circuitry temperature.";
CM_ SG_ 2566714366 EngTrbCmprssrBypssActtr2PrlmnryF "Used to identify the applicable J1939-73 FMI detected in the Engine Turbocharger Compressor Bypass Actuator 1 by the";
CM_ SG_ 2566714366 EngDsrdTrbCmprssrBypssActtr2Pos "The desired position of the Engine Turbocharger Compressor Bypass actuator 2 by the engine ECM, where 0%";
CM_ SG_ 2566714366 EngTrbCmprssrBypassActuator2Pos "Measures the position of the turbocharger compressor bypass actuator 2, where 0% represents bypass fully closed and";
CM_ BO_ 2566714110 "Engine Fuel/Throttle Valve Information";
CM_ SG_ 2566714110 EngFuelValve2OperationStatus "Used to identify the status of Engine Fuel Valve 2";
CM_ SG_ 2566714110 EngFuelValve1OperationStatus "Used to identify the status of Engine Fuel Valve 1";
CM_ SG_ 2566714110 EngThrttleValve2OperationStatus "Used to identify the status of Engine Throttle Valve 2";
CM_ SG_ 2566714110 EngThrttleValve1OperationStatus "Used to identify the status of Engine Throttle Valve 1";
CM_ SG_ 2566714110 EngFuelValve2TempStatus "Used to identify the status of the Engine Fuel valve 2 drive circuitry temperature.";
CM_ SG_ 2566714110 EngFuelValve2PreliminaryFMI "Used to identify the applicable J1939-73 FMI detected in the Engine Fuel Valve 2 by the manufacturers software.";
CM_ SG_ 2566714110 EngFuelValve1TempStatus "Used to identify the status of the Engine Fuel valve 1 drive circuitry temperature.";
CM_ SG_ 2566714110 EngFuelValve1PreliminaryFMI "Used to identify the applicable J1939-73 FMI detected in the Engine Fuel Valve 1 by the manufacturers software.";
CM_ SG_ 2566714110 EngThrottleValve2TempStatus "Used to identify the status of the Engine Throttle Valve 2 drive circuitry temperature.";
CM_ SG_ 2566714110 EngThrottleValve2PreliminaryFMI "Used to identify the applicable J1939-73 FMI detected in the Engine Throttle Valve 2 by the manufacturers software.";
CM_ SG_ 2566714110 EngDesiredThrottleValve2Pos "The desired position of the Throttle valve 2 that is regulating the fluid, usually air/fuel mixture to the engine as";
CM_ SG_ 2566714110 EngThrottleValve1TempStatus "Used to identify the status of the Engine Throttle Valve 1 drive circuitry temperature.";
CM_ SG_ 2566714110 EngThrottleValve1PreliminaryFMI "Used to identify the appplicable J1939-73 FMI detected in the Engine Throttle Valve 1 by the manufacturers software.";
CM_ SG_ 2566714110 EngDesiredThrottleValve1Pos "The desired position of the Throttle valve 1 that is regulating the fluid, usually air/fuel mixture to the engine as";
CM_ BO_ 2566717438 "Engine Temperature 5";
CM_ SG_ 2566717438 EngExhstGsRcrcltn2MxrIntakeTemp "The temperature of the EGR gas entering the intake of EGR2 system mixer.";
CM_ SG_ 2566717438 EngExhaustGasRecirculation2Temp "Temperature of Recirculated Exhaust Gas of EGR2";
CM_ BO_ 2633828606 "Engine oil message";
CM_ SG_ 2633828606 EngOilRelativeDielectricity "Engine oil relative dielectricity used to describe the engine oil quality.";
CM_ SG_ 2633828606 EngOilDensity "Density of the engine oil";
CM_ SG_ 2633828606 EngOilViscosity "Dynamic viscosity of the engine oil";
CM_ BO_ 2499607550 "Engine Manifold Actuator Position";
CM_ SG_ 2499607550 EngExhstMnfldBnk2FlwBlncVlvActtr "Actual percentage of maximum Engine Manifold Bank 2 Balance valve opening.";
CM_ SG_ 2499607550 EngExhstMnfldBnk1FlwBlncVlvActtr "Actual percentage of maximum Engine Exhaust Manifold Bank 1 Balance valve opening.";
CM_ BO_ 2633825534 "Engine Manifold Actuator Control";
CM_ SG_ 2633825534 EngExhstMnfldBnk2FlwBlncVlv_0000 "Commanded percentage of maximum Engine Ehaust Manifold Bank 2 Balance valve opening.";
CM_ SG_ 2633825534 EngExhstMnfldBnk1FlwBlncVlv_0000 "Commanded percentage of maximum Engine Exhaust Manifold Bank 1 Balance valve opening.";
CM_ BO_ 2365400574 "Extended Joystick Message 9";
CM_ SG_ 2365400574 Jystck9GripXAxisDetentPosStatus "Reports when the current joystick grip position is in the detent position for that axis of travel.";
CM_ SG_ 2365400574 Jystck9GripYAxisDetentPosStatus "Reports when the current joystick grip position is in the detent position for that axis of travel.";
CM_ SG_ 2365400574 Jystck9ThetaAxisDetentPosStatus "Reports when the current joystick position is in the detent position for that axis of travel.";
CM_ SG_ 2365400574 Joystick9ThetaAxisPos "The position of the joystick in the relative motion of travel from the neutral position.";
CM_ SG_ 2365400574 Jystck9ThtAxsClckwsPstvPsStatus "Reports when the current joystick position is on the positive travel side (forward, right, clockwise, up) relative to the";
CM_ SG_ 2365400574 Jystck9ThtAxsCntrClckwsNgtvPsStt "Reports when the current joystick position is on the negative travel side (back, left, counterclockwise, down) relative to the";
CM_ SG_ 2365400574 Jystck9ThtaAxisNeutralPosStatus "Reports when the current joystick position is in the neutral position for that axis of travel.";
CM_ SG_ 2365400574 Joystick9GripYAxisPos "The position of the joystick grip in the relative motion of travel from the neutral position.";
CM_ SG_ 2365400574 Jystck9GrpYAxsLvrFrwrdPstvPsStts "Reports when the current joystick grip position is on the positive travel side (forward, right, clockwise, up) relative to the";
CM_ SG_ 2365400574 Jystck9GrpYAxsLvrBckNgtvPsSttus "Reports when the current joystick grip position is on the negative travel side (back, left, counterclockwise, down) relative";
CM_ SG_ 2365400574 Jystck9GrpYAxisNeutralPosStatus "Reports when the current joystick grip position is in the neutral position for that axis of travel.";
CM_ SG_ 2365400574 Joystick9GripXAxisPos "The position of the joystick grip in the relative motion of travel from the neutral position.";
CM_ SG_ 2365400574 Jystck9GrpXAxsLvrRghtPstvPsStts "Reports when the current joystick grip position is on the positive travel side (forward, right, clockwise, up) relative to the";
CM_ SG_ 2365400574 Jystck9GrpXAxsLvrLftNgtvPsSttus "Reports when the current joystick grip position is on the negative travel side (back, left, counterclockwise, down) relative";
CM_ SG_ 2365400574 Jystck9GrpXAxisNeutralPosStatus "Reports when the current joystick grip position is in the neutral position for that axis of travel.";
CM_ BO_ 2365401086 "Extended Joystick Message 8";
CM_ SG_ 2365401086 Jystck8GripXAxisDetentPosStatus "Reports when the current joystick grip position is in the detent position for that axis of travel.";
CM_ SG_ 2365401086 Jystck8GripYAxisDetentPosStatus "Reports when the current joystick grip position is in the detent position for that axis of travel.";
CM_ SG_ 2365401086 Jystck8ThetaAxisDetentPosStatus "Reports when the current joystick position is in the detent position for that axis of travel.";
CM_ SG_ 2365401086 Joystick8ThetaAxisPos "The position of the joystick in the relative motion of travel from the neutral position.";
CM_ SG_ 2365401086 Jystck8ThtAxsClckwsPstvPsStatus "Reports when the current joystick position is on the positive travel side (forward, right, clockwise, up) relative to the";
CM_ SG_ 2365401086 Jystck8ThtAxsCntrClckwsNgtvPsStt "Reports when the current joystick position is on the negative travel side (back, left, counterclockwise, down) relative to the";
CM_ SG_ 2365401086 Jystck8ThtaAxisNeutralPosStatus "Reports when the current joystick position is in the neutral position for that axis of travel.";
CM_ SG_ 2365401086 Joystick8GripYAxisPos "The position of the joystick grip in the relative motion of travel from the neutral position.";
CM_ SG_ 2365401086 Jystck8GrpYAxsLvrFrwrdPstvPsStts "Reports when the current joystick grip position is on the positive travel side (forward, right, clockwise, up) relative to the";
CM_ SG_ 2365401086 Jystck8GrpYAxsLvrBckNgtvPsSttus "Reports when the current joystick grip position is on the negative travel side (back, left, counterclockwise, down) relative";
CM_ SG_ 2365401086 Jystck8GrpYAxisNeutralPosStatus "Reports when the current joystick grip position is in the neutral position for that axis of travel.";
CM_ SG_ 2365401086 Joystick8GripXAxisPos "The position of the joystick grip in the relative motion of travel from the neutral position.";
CM_ SG_ 2365401086 Jystck8GrpXAxsLvrRghtPstvPsStts "Reports when the current joystick grip position is on the positive travel side (forward, right, clockwise, up) relative to the";
CM_ SG_ 2365401086 Jystck8GrpXAxsLvrLftNgtvPsSttus "Reports when the current joystick grip position is on the negative travel side (back, left, counterclockwise, down) relative";
CM_ SG_ 2365401086 Jystck8GrpXAxisNeutralPosStatus "Reports when the current joystick grip position is in the neutral position for that axis of travel.";
CM_ BO_ 2365401598 "Extended Joystick Message 7";
CM_ SG_ 2365401598 Jystck7GripXAxisDetentPosStatus "Reports when the current joystick grip position is in the detent position for that axis of travel.";
CM_ SG_ 2365401598 Jystck7GripYAxisDetentPosStatus "Reports when the current joystick grip position is in the detent position for that axis of travel.";
CM_ SG_ 2365401598 Jystck7ThetaAxisDetentPosStatus "Reports when the current joystick position is in the detent position for that axis of travel.";
CM_ SG_ 2365401598 Joystick7ThetaAxisPos "The position of the joystick in the relative motion of travel from the neutral position.";
CM_ SG_ 2365401598 Jystck7ThtAxsClckwsPstvPsStatus "Reports when the current joystick position is on the positive travel side (forward, right, clockwise, up) relative to the";
CM_ SG_ 2365401598 Jystck7ThtAxsCntrClckwsNgtvPsStt "Reports when the current joystick position is on the negative travel side (back, left, counterclockwise, down) relative to the";
CM_ SG_ 2365401598 Jystck7ThtaAxisNeutralPosStatus "Reports when the current joystick position is in the neutral position for that axis of travel.";
CM_ SG_ 2365401598 Joystick7GripYAxisPos "The position of the joystick grip in the relative motion of travel from the neutral position.";
CM_ SG_ 2365401598 Jystck7GrpYAxsLvrFrwrdPstvPsStts "Reports when the current joystick grip position is on the positive travel side (forward, right, clockwise, up) relative to the";
CM_ SG_ 2365401598 Jystck7GrpYAxsLvrBckNgtvPsSttus "Reports when the current joystick grip position is on the negative travel side (back, left, counterclockwise, down) relative";
CM_ SG_ 2365401598 Jystck7GrpYAxisNeutralPosStatus "Reports when the current joystick grip position is in the neutral position for that axis of travel.";
CM_ SG_ 2365401598 Joystick7GripXAxisPos "The position of the joystick grip in the relative motion of travel from the neutral position.";
CM_ SG_ 2365401598 Jystck7GrpXAxsLvrRghtPstvPsStts "Reports when the current joystick grip position is on the positive travel side (forward, right, clockwise, up) relative to the";
CM_ SG_ 2365401598 Jystck7GrpXAxsLvrLftNgtvPsSttus "Reports when the current joystick grip position is on the negative travel side (back, left, counterclockwise, down) relative";
CM_ SG_ 2365401598 Jystck7GrpXAxisNeutralPosStatus "Reports when the current joystick grip position is in the neutral position for that axis of travel.";
CM_ BO_ 2365402110 "Extended Joystick Message 6";
CM_ SG_ 2365402110 Jystck6GripXAxisDetentPosStatus "Reports when the current joystick grip position is in the detent position for that axis of travel.";
CM_ SG_ 2365402110 Jystck6GripYAxisDetentPosStatus "Reports when the current joystick grip position is in the detent position for that axis of travel.";
CM_ SG_ 2365402110 Jystck6ThetaAxisDetentPosStatus "Reports when the current joystick position is in the detent position for that axis of travel.";
CM_ SG_ 2365402110 Joystick6ThetaAxisPos "The position of the joystick in the relative motion of travel from the neutral position.";
CM_ SG_ 2365402110 Jystck6ThtAxsClckwsPstvPsStatus "Reports when the current joystick position is on the positive travel side (forward, right, clockwise, up) relative to the";
CM_ SG_ 2365402110 Jystck6ThtAxsCntrClckwsNgtvPsStt "Reports when the current joystick position is on the negative travel side (back, left, counterclockwise, down) relative to the";
CM_ SG_ 2365402110 Jystck6ThtaAxisNeutralPosStatus "Reports when the current joystick position is in the neutral position for that axis of travel.";
CM_ SG_ 2365402110 Joystick6GripYAxisPos "The position of the joystick grip in the relative motion of travel from the neutral position.";
CM_ SG_ 2365402110 Jystck6GrpYAxsLvrFrwrdPstvPsStts "Reports when the current joystick grip position is on the positive travel side (forward, right, clockwise, up) relative to the";
CM_ SG_ 2365402110 Jystck6GrpYAxsLvrBckNgtvPsSttus "Reports when the current joystick grip position is on the negative travel side (back, left, counterclockwise, down) relative";
CM_ SG_ 2365402110 Jystck6GrpYAxisNeutralPosStatus "Reports when the current joystick grip position is in the neutral position for that axis of travel.";
CM_ SG_ 2365402110 Joystick6GripXAxisPos "The position of the joystick grip in the relative motion of travel from the neutral position.";
CM_ SG_ 2365402110 Jystck6GrpXAxsLvrRghtPstvPsStts "Reports when the current joystick grip position is on the positive travel side (forward, right, clockwise, up) relative to the";
CM_ SG_ 2365402110 Jystck6GrpXAxsLvrLftNgtvPsSttus "Reports when the current joystick grip position is on the negative travel side (back, left, counterclockwise, down) relative";
CM_ SG_ 2365402110 Jystck6GrpXAxisNeutralPosStatus "Reports when the current joystick grip position is in the neutral position for that axis of travel.";
CM_ BO_ 2365402622 "Extended Joystick Message 5";
CM_ SG_ 2365402622 Jystck5GripXAxisDetentPosStatus "Reports when the current joystick grip position is in the detent position for that axis of travel.";
CM_ SG_ 2365402622 Jystck5GripYAxisDetentPosStatus "Reports when the current joystick grip position is in the detent position for that axis of travel.";
CM_ SG_ 2365402622 Jystck5ThetaAxisDetentPosStatus "Reports when the current joystick position is in the detent position for that axis of travel.";
CM_ SG_ 2365402622 Joystick5ThetaAxisPos "The position of the joystick in the relative motion of travel from the neutral position.";
CM_ SG_ 2365402622 Jystck5ThtAxsClckwsPstvPsStatus "Reports when the current joystick position is on the positive travel side (forward, right, clockwise, up) relative to the";
CM_ SG_ 2365402622 Jystck5ThtAxsCntrClckwsNgtvPsStt "Reports when the current joystick position is on the negative travel side (back, left, counterclockwise, down) relative to the";
CM_ SG_ 2365402622 Jystck5ThtaAxisNeutralPosStatus "Reports when the current joystick position is in the neutral position for that axis of travel.";
CM_ SG_ 2365402622 Joystick5GripYAxisPos "The position of the joystick grip in the relative motion of travel from the neutral position.";
CM_ SG_ 2365402622 Jystck5GrpYAxsLvrFrwrdPstvPsStts "Reports when the current joystick grip position is on the positive travel side (forward, right, clockwise, up) relative to the";
CM_ SG_ 2365402622 Jystck5GrpYAxsLvrBckNgtvPsSttus "Reports when the current joystick grip position is on the negative travel side (back, left, counterclockwise, down) relative";
CM_ SG_ 2365402622 Jystck5GrpYAxisNeutralPosStatus "Reports when the current joystick grip position is in the neutral position for that axis of travel.";
CM_ SG_ 2365402622 Joystick5GripXAxisPos "The position of the joystick grip in the relative motion of travel from the neutral position.";
CM_ SG_ 2365402622 Jystck5GrpXAxsLvrRghtPstvPsStts "Reports when the current joystick grip position is on the positive travel side (forward, right, clockwise, up) relative to the";
CM_ SG_ 2365402622 Jystck5GrpXAxsLvrLftNgtvPsSttus "Reports when the current joystick grip position is on the negative travel side (back, left, counterclockwise, down) relative";
CM_ SG_ 2365402622 Jystck5GrpXAxisNeutralPosStatus "Reports when the current joystick grip position is in the neutral position for that axis of travel.";
CM_ BO_ 2365403134 "Extended Joystick Message 4";
CM_ SG_ 2365403134 Jystck4GripXAxisDetentPosStatus "Reports when the current joystick grip position is in the detent position for that axis of travel.";
CM_ SG_ 2365403134 Jystck4GripYAxisDetentPosStatus "Reports when the current joystick grip position is in the detent position for that axis of travel.";
CM_ SG_ 2365403134 Jystck4ThetaAxisDetentPosStatus "Reports when the current joystick position is in the detent position for that axis of travel.";
CM_ SG_ 2365403134 Joystick4ThetaAxisPos "The position of the joystick in the relative motion of travel from the neutral position.";
CM_ SG_ 2365403134 Jystck4ThtAxsClckwsPstvPsStatus "Reports when the current joystick position is on the positive travel side (forward, right, clockwise, up) relative to the";
CM_ SG_ 2365403134 Jystck4ThtAxsCntrClckwsNgtvPsStt "Reports when the current joystick position is on the negative travel side (back, left, counterclockwise, down) relative to the";
CM_ SG_ 2365403134 Jystck4ThtaAxisNeutralPosStatus "Reports when the current joystick position is in the neutral position for that axis of travel.";
CM_ SG_ 2365403134 Joystick4GripYAxisPos "The position of the joystick grip in the relative motion of travel from the neutral position.";
CM_ SG_ 2365403134 Jystck4GrpYAxsLvrFrwrdPstvPsStts "Reports when the current joystick grip position is on the positive travel side (forward, right, clockwise, up) relative to the";
CM_ SG_ 2365403134 Jystck4GrpYAxsLvrBckNgtvPsSttus "Reports when the current joystick grip position is on the negative travel side (back, left, counterclockwise, down) relative";
CM_ SG_ 2365403134 Jystck4GrpYAxisNeutralPosStatus "Reports when the current joystick grip position is in the neutral position for that axis of travel.";
CM_ SG_ 2365403134 Joystick4GripXAxisPos "The position of the joystick grip in the relative motion of travel from the neutral position.";
CM_ SG_ 2365403134 Jystck4GrpXAxsLvrRghtPstvPsStts "Reports when the current joystick grip position is on the positive travel side (forward, right, clockwise, up) relative to the";
CM_ SG_ 2365403134 Jystck4GrpXAxsLvrLftNgtvPsSttus "Reports when the current joystick grip position is on the negative travel side (back, left, counterclockwise, down) relative";
CM_ SG_ 2365403134 Jystck4GrpXAxisNeutralPosStatus "Reports when the current joystick grip position is in the neutral position for that axis of travel.";
CM_ BO_ 2365400062 "Extended Joystick Message 10";
CM_ SG_ 2365400062 Jystck10GrpXAxisDetentPosStatus "Reports when the current joystick grip position is in the detent position for that axis of travel.";
CM_ SG_ 2365400062 Jystck10GrpYAxisDetentPosStatus "Reports when the current joystick grip position is in the detent position for that axis of travel.";
CM_ SG_ 2365400062 Jystck10ThtaAxisDetentPosStatus "Reports when the current joystick position is in the detent position for that axis of travel.";
CM_ SG_ 2365400062 Joystick10ThetaAxisPos "The position of the joystick in the relative motion of travel from the neutral position.";
CM_ SG_ 2365400062 Jystck10ThtAxsClckwsPstvPsSttus "Reports when the current joystick position is on the positive travel side (forward, right, clockwise, up) relative to the";
CM_ SG_ 2365400062 Jystck10ThtAxsCntrClckwsNgtvPsSt "Reports when the current joystick position is on the negative travel side (back, left, counterclockwise, down) relative to the";
CM_ SG_ 2365400062 Jystck10ThtAxisNeutralPosStatus "Reports when the current joystick position is in the neutral position for that axis of travel.";
CM_ SG_ 2365400062 Joystick10GripYAxisPos "The position of the joystick grip in the relative motion of travel from the neutral position.";
CM_ SG_ 2365400062 Jystck10GrpYAxsLvrFrwrdPstvPsStt "Reports when the current joystick grip position is on the positive travel side (forward, right, clockwise, up) relative to the";
CM_ SG_ 2365400062 Jystck10GrpYAxsLvrBckNgtvPsStts "Reports when the current joystick grip position is on the negative travel side (back, left, counterclockwise, down) relative";
CM_ SG_ 2365400062 Jystck10GrpYAxsNeutralPosStatus "Reports when the current joystick grip position is in the neutral position for that axis of travel.";
CM_ SG_ 2365400062 Joystick10GripXAxisPos "The position of the joystick grip in the relative motion of travel from the neutral position.";
CM_ SG_ 2365400062 Jystck10GrpXAxsLvrRghtPstvPsStts "Reports when the current joystick grip position is on the positive travel side (forward, right, clockwise, up) relative to the";
CM_ SG_ 2365400062 Jystck10GrpXAxsLvrLftNgtvPsStts "Reports when the current joystick grip position is on the negative travel side (back, left, counterclockwise, down) relative";
CM_ SG_ 2365400062 Jystck10GrpXAxsNeutralPosStatus "Reports when the current joystick grip position is in the neutral position for that axis of travel.";
CM_ BO_ 2566713598 "Engine Fuel/lube systems 2";
CM_ SG_ 2566713598 EngFuelFilterIntakeAbsPress "Absolute pressure of fuel at the intake of the fuel filter (suction side) located between the fuel tank and the fuel supply";
CM_ BO_ 2499604478 "Engine Fluid/Pressure 11";
CM_ SG_ 2499604478 EngExhstGsRcrcltn1IntkeAbsPress "EGR intake absolute pressure measured before the EGR 1 valve.";
CM_ BO_ 2499608830 "Engine Fluid/Pressure 10";
CM_ SG_ 2499608830 EngExhstGsRcrcltn2IntkeAbsPress "EGR intake absolute pressure measured before the EGR 2 valve.";
CM_ SG_ 2499608830 EngExhstGsRcrcltn2OtletAbsPress "Absolute Pressure immediately after the EGR2 valve";
CM_ SG_ 2499608830 EngExhstGsRcrcltion2IntakePress "EGR2 intake gauge pressure is measured after EGR2 cooler and before EGR2 valve";
CM_ SG_ 2499608830 EngExhstGsRcrculation2DiffPress "Differential Pressure across the Exhaust Gas Recirculation 2 (EGR2) system.";
BA_DEF_ SG_  "SigType" ENUM  "Default","Range","RangeSigned","ASCII","Discrete","Control","ReferencePGN","DTC","StringDelimiter","StringLength","StringLengthControl";
BA_DEF_ SG_  "GenSigStartValue" INT 0 10000;
BA_DEF_ SG_  "GenSigSendType" ENUM  "Cyclic","OnWrite","reserved","OnChange","reserved","reserved","reserved","NoSigSendType";
BA_DEF_ SG_  "GenSigILSupport" ENUM  "Yes","No";
BA_DEF_ SG_  "GenSigEVName" STRING ;
BA_DEF_ SG_  "SPN" INT 0 524287;
BA_DEF_ BO_  "GenMsgStartDelayTime" INT 0 100000;
BA_DEF_ BO_  "GenMsgILSupport" ENUM  "Yes","No";
BA_DEF_ BO_  "GenMsgRequestable" INT 0 1;
BA_DEF_ BO_  "GenMsgSendType" ENUM  "cyclic","reserved","cyclicIfActive","reserved","reserved","reserved","reserved","reserved","noMsgSendType";
BA_DEF_ BO_  "VFrameFormat" ENUM  "StandardCAN","ExtendedCAN","reserved";
BA_DEF_ BO_  "GenMsgCycleTime" INT 0 3600000;
BA_DEF_ BU_  "NmStationAddress" INT 0 255;
BA_DEF_  "DatabaseVersion" STRING ;
BA_DEF_  "BusType" STRING ;
BA_DEF_ SG_  "SystemSignalLongSymbol" STRING ;
BA_DEF_DEF_  "SigType" "Default";
BA_DEF_DEF_  "GenSigStartValue" 0;
BA_DEF_DEF_  "GenSigSendType" "NoSigSendType";
BA_DEF_DEF_  "GenSigILSupport" "Yes";
BA_DEF_DEF_  "GenSigEVName" "Env@Nodename_@Signame";
BA_DEF_DEF_  "SPN" 0;
BA_DEF_DEF_  "GenMsgStartDelayTime" 0;
BA_DEF_DEF_  "GenMsgILSupport" "Yes";
BA_DEF_DEF_  "GenMsgRequestable" 1;
BA_DEF_DEF_  "GenMsgSendType" "noMsgSendType";
BA_DEF_DEF_  "VFrameFormat" "";
BA_DEF_DEF_  "GenMsgCycleTime" 0;
BA_DEF_DEF_  "NmStationAddress" 254;
BA_DEF_DEF_  "DatabaseVersion" "";
BA_DEF_DEF_  "BusType" "";
BA_DEF_DEF_  "SystemSignalLongSymbol" "";
BA_ "DatabaseVersion" "7.2";
BA_ "BusType" "CAN";
BA_ "VFrameFormat" BO_ 2348810247 3;
BA_ "VFrameFormat" BO_ 2558984192 3;
BA_ "VFrameFormat" BO_ 2164049920 3;
BA_ "VFrameFormat" BO_ 2566708224 3;
BA_ "VFrameFormat" BO_ 2550792192 3;
BA_ "VFrameFormat" BO_ 2348814083 3;
BA_ "GenMsgSendType" BO_ 2565866755 0;
BA_ "GenMsgCycleTime" BO_ 2565866755 100;
BA_ "VFrameFormat" BO_ 2565866755 3;
BA_ "GenMsgSendType" BO_ 2364539395 0;
BA_ "GenMsgCycleTime" BO_ 2364539395 10;
BA_ "VFrameFormat" BO_ 2364539395 3;
BA_ "VFrameFormat" BO_ 2348810243 3;
BA_ "GenMsgSendType" BO_ 2297441790 0;
BA_ "GenMsgCycleTime" BO_ 2297441790 10;
BA_ "VFrameFormat" BO_ 2297441790 3;
BA_ "VFrameFormat" BO_ 2566712062 3;
BA_ "GenMsgSendType" BO_ 2364549630 0;
BA_ "GenMsgCycleTime" BO_ 2364549630 10;
BA_ "VFrameFormat" BO_ 2364549630 3;
BA_ "VFrameFormat" BO_ 2499614462 3;
BA_ "VFrameFormat" BO_ 2560098046 3;
BA_ "VFrameFormat" BO_ 2560163582 3;
BA_ "GenMsgSendType" BO_ 2297441534 0;
BA_ "GenMsgCycleTime" BO_ 2297441534 50;
BA_ "VFrameFormat" BO_ 2297441534 3;
BA_ "GenMsgSendType" BO_ 2566722302 0;
BA_ "GenMsgCycleTime" BO_ 2566722302 500;
BA_ "VFrameFormat" BO_ 2566722302 3;
BA_ "VFrameFormat" BO_ 2566722558 3;
BA_ "VFrameFormat" BO_ 2560032510 3;
BA_ "GenMsgSendType" BO_ 2566717950 0;
BA_ "GenMsgCycleTime" BO_ 2566717950 500;
BA_ "VFrameFormat" BO_ 2566717950 3;
BA_ "GenMsgSendType" BO_ 2499604222 0;
BA_ "GenMsgCycleTime" BO_ 2499604222 200;
BA_ "VFrameFormat" BO_ 2499604222 3;
BA_ "GenMsgSendType" BO_ 2358902526 0;
BA_ "GenMsgCycleTime" BO_ 2358902526 100;
BA_ "VFrameFormat" BO_ 2358902526 3;
BA_ "GenMsgSendType" BO_ 2566711550 0;
BA_ "GenMsgCycleTime" BO_ 2566711550 500;
BA_ "VFrameFormat" BO_ 2566711550 3;
BA_ "VFrameFormat" BO_ 2633832958 3;
BA_ "GenMsgSendType" BO_ 2566719998 0;
BA_ "GenMsgCycleTime" BO_ 2566719998 1000;
BA_ "VFrameFormat" BO_ 2566719998 3;
BA_ "VFrameFormat" BO_ 2565877502 3;
BA_ "GenMsgSendType" BO_ 2566713854 0;
BA_ "GenMsgCycleTime" BO_ 2566713854 100;
BA_ "VFrameFormat" BO_ 2566713854 3;
BA_ "GenMsgSendType" BO_ 2566714366 0;
BA_ "GenMsgCycleTime" BO_ 2566714366 100;
BA_ "VFrameFormat" BO_ 2566714366 3;
BA_ "GenMsgSendType" BO_ 2566714110 0;
BA_ "GenMsgCycleTime" BO_ 2566714110 100;
BA_ "VFrameFormat" BO_ 2566714110 3;
BA_ "GenMsgSendType" BO_ 2566717438 0;
BA_ "GenMsgCycleTime" BO_ 2566717438 1000;
BA_ "VFrameFormat" BO_ 2566717438 3;
BA_ "GenMsgSendType" BO_ 2633828606 0;
BA_ "GenMsgCycleTime" BO_ 2633828606 30000;
BA_ "VFrameFormat" BO_ 2633828606 3;
BA_ "VFrameFormat" BO_ 2499607550 3;
BA_ "VFrameFormat" BO_ 2633825534 3;
BA_ "VFrameFormat" BO_ 2365400574 3;
BA_ "VFrameFormat" BO_ 2365401086 3;
BA_ "VFrameFormat" BO_ 2365401598 3;
BA_ "VFrameFormat" BO_ 2365402110 3;
BA_ "VFrameFormat" BO_ 2365402622 3;
BA_ "VFrameFormat" BO_ 2365403134 3;
BA_ "VFrameFormat" BO_ 2365400062 3;
BA_ "GenMsgSendType" BO_ 2566713598 0;
BA_ "GenMsgCycleTime" BO_ 2566713598 500;
BA_ "VFrameFormat" BO_ 2566713598 3;
BA_ "GenMsgSendType" BO_ 2499604478 0;
BA_ "GenMsgCycleTime" BO_ 2499604478 500;
BA_ "VFrameFormat" BO_ 2499604478 3;
BA_ "GenMsgSendType" BO_ 2499608830 0;
BA_ "GenMsgCycleTime" BO_ 2499608830 500;
BA_ "VFrameFormat" BO_ 2499608830 3;
BA_ "SigType" SG_ 3221225472 TrailerWeight 1;
BA_ "SPN" SG_ 3221225472 TrailerWeight 180;
BA_ "SigType" SG_ 3221225472 ReferenceTirePressSetting 1;
BA_ "SPN" SG_ 3221225472 ReferenceTirePressSetting 3193;
BA_ "SigType" SG_ 3221225472 ReferenceTirePress 1;
BA_ "SPN" SG_ 3221225472 ReferenceTirePress 3191;
BA_ "SigType" SG_ 3221225472 TirePressThresholdDetection 4;
BA_ "SPN" SG_ 3221225472 TirePressThresholdDetection 2587;
BA_ "SigType" SG_ 3221225472 TireAirLeakageRate 1;
BA_ "SPN" SG_ 3221225472 TireAirLeakageRate 2586;
BA_ "SigType" SG_ 3221225472 CTIWheelEndElectricalFault 4;
BA_ "SPN" SG_ 3221225472 CTIWheelEndElectricalFault 1697;
BA_ "SigType" SG_ 3221225472 CTITireStatus 4;
BA_ "SPN" SG_ 3221225472 CTITireStatus 1698;
BA_ "SigType" SG_ 3221225472 CTIWheelSensorStatus 4;
BA_ "SPN" SG_ 3221225472 CTIWheelSensorStatus 1699;
BA_ "SigType" SG_ 3221225472 TireTemp 1;
BA_ "SPN" SG_ 3221225472 TireTemp 242;
BA_ "SigType" SG_ 3221225472 TirePress 1;
BA_ "SPN" SG_ 3221225472 TirePress 241;
BA_ "SigType" SG_ 3221225472 EngTorqueMode 4;
BA_ "SPN" SG_ 3221225472 EngTorqueMode 899;
BA_ "SigType" SG_ 3221225472 EngTrqMd_Corrected 4;
BA_ "SPN" SG_ 3221225472 EngTrqMd_Corrected 899;
BA_ "SigType" SG_ 3221225472 SrcAddrssOfCtrllngDvcFrEngCntrl 1;
BA_ "SPN" SG_ 3221225472 SrcAddrssOfCtrllngDvcFrEngCntrl 1483;
BA_ "SigType" SG_ 3221225472 ActlEngPrcntTrqueHighResolution 1;
BA_ "SPN" SG_ 3221225472 ActlEngPrcntTrqueHighResolution 4154;
BA_ "SigType" SG_ 3221225472 EngDemandPercentTorque 1;
BA_ "SPN" SG_ 3221225472 EngDemandPercentTorque 2432;
BA_ "SigType" SG_ 3221225472 EngStarterMode 4;
BA_ "SPN" SG_ 3221225472 EngStarterMode 1675;
BA_ "SigType" SG_ 3221225472 EngSpeed 1;
BA_ "SPN" SG_ 3221225472 EngSpeed 190;
BA_ "SigType" SG_ 3221225472 ActualEngPercentTorque 1;
BA_ "SPN" SG_ 3221225472 ActualEngPercentTorque 513;
BA_ "SigType" SG_ 3221225472 DriversDemandEngPercentTorque 1;
BA_ "SPN" SG_ 3221225472 DriversDemandEngPercentTorque 512;
BA_ "SPN" SG_ 3221225472 MessageCounter 4206;
BA_ "SPN" SG_ 3221225472 ControlPurpose 3350;
BA_ "SPN" SG_ 3221225472 TransmissionRate 3349;
BA_ "SigType" SG_ 3221225472 EngRqedTorque_TorqueLimit 1;
BA_ "SPN" SG_ 3221225472 EngRqedTorque_TorqueLimit 518;
BA_ "SigType" SG_ 3221225472 EngRqedSpeed_SpeedLimit 1;
BA_ "SPN" SG_ 3221225472 EngRqedSpeed_SpeedLimit 898;
BA_ "SPN" SG_ 3221225472 OverrideCtrlModePriority 897;
BA_ "SPN" SG_ 3221225472 EngRqedSpeedCtrlConditions 696;
BA_ "SPN" SG_ 3221225472 EngOverrideCtrlMode 695;
BA_ "SPN" SG_ 3221225472 MessageChecksum 4207;
BA_ "SPN" SG_ 3221225472 EngineRequestedTorqueHiRes 4191;
BA_ "SigType" SG_ 3221225472 TransCurrentRange 1;
BA_ "SPN" SG_ 3221225472 TransCurrentRange 163;
BA_ "SigType" SG_ 3221225472 TransRqedRange 1;
BA_ "SPN" SG_ 3221225472 TransRqedRange 162;
BA_ "SigType" SG_ 3221225472 TransCurrentGear 1;
BA_ "SPN" SG_ 3221225472 TransCurrentGear 523;
BA_ "SigType" SG_ 3221225472 TransActualGearRatio 1;
BA_ "SPN" SG_ 3221225472 TransActualGearRatio 526;
BA_ "SigType" SG_ 3221225472 TransSelectedGear 1;
BA_ "SPN" SG_ 3221225472 TransSelectedGear 524;
BA_ "SigType" SG_ 3221225472 TrnsTrqueConverterLockupEngaged 4;
BA_ "SPN" SG_ 3221225472 TrnsTrqueConverterLockupEngaged 573;
BA_ "SigType" SG_ 3221225472 TrnsTrqCnvrtrLckpTrnstnInPrcess 4;
BA_ "SPN" SG_ 3221225472 TrnsTrqCnvrtrLckpTrnstnInPrcess 4816;
BA_ "SigType" SG_ 3221225472 SrcAddrssOfCtrllngDvcFrTrnsCntrl 1;
BA_ "SPN" SG_ 3221225472 SrcAddrssOfCtrllngDvcFrTrnsCntrl 1482;
BA_ "SigType" SG_ 3221225472 MomentaryEngMaxPowerEnable 4;
BA_ "SPN" SG_ 3221225472 MomentaryEngMaxPowerEnable 5015;
BA_ "SigType" SG_ 3221225472 TransInputShaftSpeed 1;
BA_ "SPN" SG_ 3221225472 TransInputShaftSpeed 161;
BA_ "SigType" SG_ 3221225472 ProgressiveShiftDisable 4;
BA_ "SPN" SG_ 3221225472 ProgressiveShiftDisable 607;
BA_ "SigType" SG_ 3221225472 EngMomentaryOverspeedEnable 4;
BA_ "SPN" SG_ 3221225472 EngMomentaryOverspeedEnable 606;
BA_ "SigType" SG_ 3221225472 PercentClutchSlip 1;
BA_ "SPN" SG_ 3221225472 PercentClutchSlip 522;
BA_ "SigType" SG_ 3221225472 TransOutputShaftSpeed 1;
BA_ "SPN" SG_ 3221225472 TransOutputShaftSpeed 191;
BA_ "SigType" SG_ 3221225472 TransShiftInProcess 4;
BA_ "SPN" SG_ 3221225472 TransShiftInProcess 574;
BA_ "SigType" SG_ 3221225472 TransDrivelineEngaged 4;
BA_ "SPN" SG_ 3221225472 TransDrivelineEngaged 560;
BA_ "SPN" SG_ 2348810247 MessageCounter 4206;
BA_ "SPN" SG_ 2348810247 ControlPurpose 3350;
BA_ "SPN" SG_ 2348810247 TransmissionRate 3349;
BA_ "SigType" SG_ 2348810247 EngRqedTorque_TorqueLimit 1;
BA_ "SPN" SG_ 2348810247 EngRqedTorque_TorqueLimit 518;
BA_ "SigType" SG_ 2348810247 EngRqedSpeed_SpeedLimit 1;
BA_ "SPN" SG_ 2348810247 EngRqedSpeed_SpeedLimit 898;
BA_ "SPN" SG_ 2348810247 OverrideCtrlModePriority 897;
BA_ "SPN" SG_ 2348810247 EngRqedSpeedCtrlConditions 696;
BA_ "SPN" SG_ 2348810247 EngOverrideCtrlMode 695;
BA_ "SPN" SG_ 2348810247 MessageChecksum 4207;
BA_ "SPN" SG_ 2348810247 EngineRequestedTorqueHiRes 4191;
BA_ "SPN" SG_ 2348814083 MessageCounter 4206;
BA_ "SPN" SG_ 2348814083 ControlPurpose 3350;
BA_ "SPN" SG_ 2348814083 TransmissionRate 3349;
BA_ "SigType" SG_ 2348814083 EngRqedTorque_TorqueLimit 1;
BA_ "SPN" SG_ 2348814083 EngRqedTorque_TorqueLimit 518;
BA_ "SigType" SG_ 2348814083 EngRqedSpeed_SpeedLimit 1;
BA_ "SPN" SG_ 2348814083 EngRqedSpeed_SpeedLimit 898;
BA_ "SPN" SG_ 2348814083 OverrideCtrlModePriority 897;
BA_ "SPN" SG_ 2348814083 EngRqedSpeedCtrlConditions 696;
BA_ "SPN" SG_ 2348814083 EngOverrideCtrlMode 695;
BA_ "SPN" SG_ 2348814083 MessageChecksum 4207;
BA_ "SPN" SG_ 2348814083 EngineRequestedTorqueHiRes 4191;
BA_ "SigType" SG_ 2565866755 TransCurrentRange 1;
BA_ "SPN" SG_ 2565866755 TransCurrentRange 163;
BA_ "SigType" SG_ 2565866755 TransRqedRange 1;
BA_ "SPN" SG_ 2565866755 TransRqedRange 162;
BA_ "SigType" SG_ 2565866755 TransCurrentGear 1;
BA_ "SPN" SG_ 2565866755 TransCurrentGear 523;
BA_ "SigType" SG_ 2565866755 TransActualGearRatio 1;
BA_ "SPN" SG_ 2565866755 TransActualGearRatio 526;
BA_ "SigType" SG_ 2565866755 TransSelectedGear 1;
BA_ "SPN" SG_ 2565866755 TransSelectedGear 524;
BA_ "SigType" SG_ 2364539395 TrnsTrqueConverterLockupEngaged 4;
BA_ "SPN" SG_ 2364539395 TrnsTrqueConverterLockupEngaged 573;
BA_ "SigType" SG_ 2364539395 TrnsTrqCnvrtrLckpTrnstnInPrcess 4;
BA_ "SPN" SG_ 2364539395 TrnsTrqCnvrtrLckpTrnstnInPrcess 4816;
BA_ "SigType" SG_ 2364539395 SrcAddrssOfCtrllngDvcFrTrnsCntrl 1;
BA_ "SPN" SG_ 2364539395 SrcAddrssOfCtrllngDvcFrTrnsCntrl 1482;
BA_ "SigType" SG_ 2364539395 MomentaryEngMaxPowerEnable 4;
BA_ "SPN" SG_ 2364539395 MomentaryEngMaxPowerEnable 5015;
BA_ "SigType" SG_ 2364539395 TransInputShaftSpeed 1;
BA_ "SPN" SG_ 2364539395 TransInputShaftSpeed 161;
BA_ "SigType" SG_ 2364539395 ProgressiveShiftDisable 4;
BA_ "SPN" SG_ 2364539395 ProgressiveShiftDisable 607;
BA_ "SigType" SG_ 2364539395 EngMomentaryOverspeedEnable 4;
BA_ "SPN" SG_ 2364539395 EngMomentaryOverspeedEnable 606;
BA_ "SigType" SG_ 2364539395 PercentClutchSlip 1;
BA_ "SPN" SG_ 2364539395 PercentClutchSlip 522;
BA_ "SigType" SG_ 2364539395 TransOutputShaftSpeed 1;
BA_ "SPN" SG_ 2364539395 TransOutputShaftSpeed 191;
BA_ "SigType" SG_ 2364539395 TransShiftInProcess 4;
BA_ "SPN" SG_ 2364539395 TransShiftInProcess 574;
BA_ "SigType" SG_ 2364539395 TransDrivelineEngaged 4;
BA_ "SPN" SG_ 2364539395 TransDrivelineEngaged 560;
BA_ "SPN" SG_ 2348810243 MessageCounter 4206;
BA_ "SPN" SG_ 2348810243 ControlPurpose 3350;
BA_ "SPN" SG_ 2348810243 TransmissionRate 3349;
BA_ "SigType" SG_ 2348810243 EngRqedTorque_TorqueLimit 1;
BA_ "SPN" SG_ 2348810243 EngRqedTorque_TorqueLimit 518;
BA_ "SigType" SG_ 2348810243 EngRqedSpeed_SpeedLimit 1;
BA_ "SPN" SG_ 2348810243 EngRqedSpeed_SpeedLimit 898;
BA_ "SPN" SG_ 2348810243 OverrideCtrlModePriority 897;
BA_ "SPN" SG_ 2348810243 EngRqedSpeedCtrlConditions 696;
BA_ "SPN" SG_ 2348810243 EngOverrideCtrlMode 695;
BA_ "SPN" SG_ 2348810243 MessageChecksum 4207;
BA_ "SPN" SG_ 2348810243 EngineRequestedTorqueHiRes 4191;
BA_ "SigType" SG_ 2297441790 SpprtVrblTrnsRpttnRtFrAcclrtnSns 4;
BA_ "SPN" SG_ 2297441790 SpprtVrblTrnsRpttnRtFrAcclrtnSns 5353;
BA_ "SystemSignalLongSymbol" SG_ 2297441790 SpprtVrblTrnsRpttnRtFrAcclrtnSns "SpprtVrblTrnsRpttnRtFrAcclrtnSnsr";
BA_ "SigType" SG_ 2297441790 VrtclAcclrtnExRngeFigureOfMerit 4;
BA_ "SPN" SG_ 2297441790 VrtclAcclrtnExRngeFigureOfMerit 5352;
BA_ "SigType" SG_ 2297441790 LngtdnlAcclrtnExRngFgureOfMerit 4;
BA_ "SPN" SG_ 2297441790 LngtdnlAcclrtnExRngFgureOfMerit 5351;
BA_ "SigType" SG_ 2297441790 LtrlAcclrtnExRangeFigureOfMerit 4;
BA_ "SPN" SG_ 2297441790 LtrlAcclrtnExRangeFigureOfMerit 5350;
BA_ "SigType" SG_ 2297441790 VerticalAccelerationExRange 1;
BA_ "SPN" SG_ 2297441790 VerticalAccelerationExRange 5349;
BA_ "SigType" SG_ 2297441790 LateralAccelerationExRange 1;
BA_ "SPN" SG_ 2297441790 LateralAccelerationExRange 5347;
BA_ "SigType" SG_ 2297441790 LongitudinalAccelerationExRange 1;
BA_ "SPN" SG_ 2297441790 LongitudinalAccelerationExRange 5348;
BA_ "SigType" SG_ 2566712062 HybrdBatteryPackRemainingCharge 1;
BA_ "SPN" SG_ 2566712062 HybrdBatteryPackRemainingCharge 5464;
BA_ "SigType" SG_ 2364549630 RllAndPtchExRngMsurementLatency 1;
BA_ "SPN" SG_ 2364549630 RllAndPtchExRngMsurementLatency 4982;
BA_ "SigType" SG_ 2364549630 RollAngleExRangeFigureOfMerit 4;
BA_ "SPN" SG_ 2364549630 RollAngleExRangeFigureOfMerit 4981;
BA_ "SigType" SG_ 2364549630 RollAngleExRangeCompensation 4;
BA_ "SPN" SG_ 2364549630 RollAngleExRangeCompensation 4980;
BA_ "SigType" SG_ 2364549630 PitchAngleExRangeFigureOfMerit 4;
BA_ "SPN" SG_ 2364549630 PitchAngleExRangeFigureOfMerit 4979;
BA_ "SigType" SG_ 2364549630 PitchAngleExRangeCompensation 4;
BA_ "SPN" SG_ 2364549630 PitchAngleExRangeCompensation 4978;
BA_ "SigType" SG_ 2364549630 RollAngleExRange 1;
BA_ "SPN" SG_ 2364549630 RollAngleExRange 4977;
BA_ "SigType" SG_ 2364549630 PitchAngleExRange 1;
BA_ "SPN" SG_ 2364549630 PitchAngleExRange 4976;
BA_ "SigType" SG_ 2499614462 OccpntClssfcationSystem10Status 4;
BA_ "SPN" SG_ 2499614462 OccpntClssfcationSystem10Status 4972;
BA_ "SigType" SG_ 2499614462 OccpntClssficationSystem9Status 4;
BA_ "SPN" SG_ 2499614462 OccpntClssficationSystem9Status 4971;
BA_ "SigType" SG_ 2499614462 OccpntClssficationSystem8Status 4;
BA_ "SPN" SG_ 2499614462 OccpntClssficationSystem8Status 4970;
BA_ "SigType" SG_ 2499614462 OccpntClssficationSystem7Status 4;
BA_ "SPN" SG_ 2499614462 OccpntClssficationSystem7Status 4969;
BA_ "SigType" SG_ 2499614462 OccpntClssficationSystem6Status 4;
BA_ "SPN" SG_ 2499614462 OccpntClssficationSystem6Status 4968;
BA_ "SigType" SG_ 2499614462 OccpntClssficationSystem5Status 4;
BA_ "SPN" SG_ 2499614462 OccpntClssficationSystem5Status 4967;
BA_ "SigType" SG_ 2499614462 OccpntClssficationSystem4Status 4;
BA_ "SPN" SG_ 2499614462 OccpntClssficationSystem4Status 4966;
BA_ "SigType" SG_ 2499614462 OccpntClssficationSystem3Status 4;
BA_ "SPN" SG_ 2499614462 OccpntClssficationSystem3Status 4965;
BA_ "SigType" SG_ 2499614462 PssngrOccpntClssfctnSystmStatus 4;
BA_ "SPN" SG_ 2499614462 PssngrOccpntClssfctnSystmStatus 4964;
BA_ "SigType" SG_ 2499614462 DrvrOccpntClssfctonSystemStatus 4;
BA_ "SPN" SG_ 2499614462 DrvrOccpntClssfctonSystemStatus 4963;
BA_ "SigType" SG_ 2560098046 CabNoiseCtrlTuningStatus 4;
BA_ "SPN" SG_ 2560098046 CabNoiseCtrlTuningStatus 5060;
BA_ "SigType" SG_ 2560098046 CabNoiseCtrlStatus 4;
BA_ "SPN" SG_ 2560098046 CabNoiseCtrlStatus 5059;
BA_ "SigType" SG_ 2560163582 CabNoiseCtrlTuningState 4;
BA_ "SPN" SG_ 2560163582 CabNoiseCtrlTuningState 5058;
BA_ "SigType" SG_ 2560163582 CabNoiseCtrlState 4;
BA_ "SPN" SG_ 2560163582 CabNoiseCtrlState 5057;
BA_ "SigType" SG_ 2297441534 DropRelayCtrl 4;
BA_ "SPN" SG_ 2297441534 DropRelayCtrl 5403;
BA_ "SigType" SG_ 2297441534 LiftRelayCtrl 4;
BA_ "SPN" SG_ 2297441534 LiftRelayCtrl 5402;
BA_ "SigType" SG_ 2297441534 MaterialDropActiveStatus 4;
BA_ "SPN" SG_ 2297441534 MaterialDropActiveStatus 5014;
BA_ "SigType" SG_ 2297441534 MaterialLiftActiveStatus 4;
BA_ "SPN" SG_ 2297441534 MaterialLiftActiveStatus 5013;
BA_ "SigType" SG_ 2297441534 GnratorCurrentBoostActiveStatus 4;
BA_ "SPN" SG_ 2297441534 GnratorCurrentBoostActiveStatus 5012;
BA_ "SigType" SG_ 2297441534 MaterialDropSwitch 4;
BA_ "SPN" SG_ 2297441534 MaterialDropSwitch 5011;
BA_ "SigType" SG_ 2297441534 MaterialLiftSwitch 4;
BA_ "SPN" SG_ 2297441534 MaterialLiftSwitch 5010;
BA_ "SigType" SG_ 2297441534 MagnetReverseCurrent 1;
BA_ "SPN" SG_ 2297441534 MagnetReverseCurrent 5009;
BA_ "SigType" SG_ 2297441534 MagnetForwardCurrent 1;
BA_ "SPN" SG_ 2297441534 MagnetForwardCurrent 5008;
BA_ "SigType" SG_ 2566722302 GneratorDutyCycleExceededStatus 4;
BA_ "SPN" SG_ 2566722302 GneratorDutyCycleExceededStatus 5007;
BA_ "SigType" SG_ 2566722302 VoltageMonitorActiveStatus 4;
BA_ "SPN" SG_ 2566722302 VoltageMonitorActiveStatus 5006;
BA_ "SigType" SG_ 2566722302 GensetEnableActiveStatus 4;
BA_ "SPN" SG_ 2566722302 GensetEnableActiveStatus 5005;
BA_ "SigType" SG_ 2566722302 ReverseCurrentRangeSetting 4;
BA_ "SPN" SG_ 2566722302 ReverseCurrentRangeSetting 5002;
BA_ "SigType" SG_ 2566722302 GensetSoftstartActiveStatus 4;
BA_ "SPN" SG_ 2566722302 GensetSoftstartActiveStatus 5004;
BA_ "SigType" SG_ 2566722302 Grapple_MagnetSelectionSwitch 4;
BA_ "SPN" SG_ 2566722302 Grapple_MagnetSelectionSwitch 5003;
BA_ "SigType" SG_ 2566722302 GnstSystmOtptVoltageRangeStatus 4;
BA_ "SPN" SG_ 2566722302 GnstSystmOtptVoltageRangeStatus 5001;
BA_ "SigType" SG_ 2566722302 GeneratorOverheatStatus 4;
BA_ "SPN" SG_ 2566722302 GeneratorOverheatStatus 5000;
BA_ "SigType" SG_ 2566722558 MagnetRatedPower 1;
BA_ "SPN" SG_ 2566722558 MagnetRatedPower 4999;
BA_ "SigType" SG_ 2566722558 MagnetBoostTime 1;
BA_ "SPN" SG_ 2566722558 MagnetBoostTime 4998;
BA_ "SigType" SG_ 2560032510 LwVltgDscnnctDsredOperatingMode 4;
BA_ "SPN" SG_ 2560032510 LwVltgDscnnctDsredOperatingMode 5149;
BA_ "SigType" SG_ 2566717950 LowVoltageDisconnectTemp 1;
BA_ "SPN" SG_ 2566717950 LowVoltageDisconnectTemp 5148;
BA_ "SigType" SG_ 2566717950 LwVltgDisconnectVoutOutputState 4;
BA_ "SPN" SG_ 2566717950 LwVltgDisconnectVoutOutputState 5147;
BA_ "SigType" SG_ 2566717950 LwVoltageDisconnectOutput1State 4;
BA_ "SPN" SG_ 2566717950 LwVoltageDisconnectOutput1State 5146;
BA_ "SigType" SG_ 2566717950 LwVoltageDisconnectOutput2State 4;
BA_ "SPN" SG_ 2566717950 LwVoltageDisconnectOutput2State 5145;
BA_ "SigType" SG_ 2566717950 LwVoltageDisconnectOutput3State 4;
BA_ "SPN" SG_ 2566717950 LwVoltageDisconnectOutput3State 5144;
BA_ "SigType" SG_ 2566717950 LwVltgDscnnctCrrntOperatingMode 4;
BA_ "SPN" SG_ 2566717950 LwVltgDscnnctCrrntOperatingMode 5143;
BA_ "SigType" SG_ 2566717950 LwVltgDscnnctManualConnectState 4;
BA_ "SPN" SG_ 2566717950 LwVltgDscnnctManualConnectState 5142;
BA_ "SigType" SG_ 2566717950 LwVltgDscnnctMnlDisconnectState 4;
BA_ "SPN" SG_ 2566717950 LwVltgDscnnctMnlDisconnectState 5141;
BA_ "SigType" SG_ 2499604222 BldRferenceElevationOffsetRight 1;
BA_ "SPN" SG_ 2499604222 BldRferenceElevationOffsetRight 5413;
BA_ "SigType" SG_ 2499604222 BldReferenceElevationOffsetLeft 1;
BA_ "SPN" SG_ 2499604222 BldReferenceElevationOffsetLeft 5412;
BA_ "SigType" SG_ 2499604222 BladeElevationDeviationRight 1;
BA_ "SPN" SG_ 2499604222 BladeElevationDeviationRight 5411;
BA_ "SigType" SG_ 2499604222 BladeElevationDeviationLeft 1;
BA_ "SPN" SG_ 2499604222 BladeElevationDeviationLeft 5410;
BA_ "SigType" SG_ 2358902526 Joystick3Lamp10Cmd 4;
BA_ "SPN" SG_ 2358902526 Joystick3Lamp10Cmd 4489;
BA_ "SigType" SG_ 2358902526 Joystick3Lamp9Cmd 4;
BA_ "SPN" SG_ 2358902526 Joystick3Lamp9Cmd 4488;
BA_ "SigType" SG_ 2358902526 Joystick3Lamp8Cmd 4;
BA_ "SPN" SG_ 2358902526 Joystick3Lamp8Cmd 4487;
BA_ "SigType" SG_ 2358902526 Joystick3Lamp7Cmd 4;
BA_ "SPN" SG_ 2358902526 Joystick3Lamp7Cmd 4486;
BA_ "SigType" SG_ 2358902526 Joystick3Lamp6Cmd 4;
BA_ "SPN" SG_ 2358902526 Joystick3Lamp6Cmd 4485;
BA_ "SigType" SG_ 2358902526 Joystick3Lamp5Cmd 4;
BA_ "SPN" SG_ 2358902526 Joystick3Lamp5Cmd 4484;
BA_ "SigType" SG_ 2358902526 Joystick3Lamp4Cmd 4;
BA_ "SPN" SG_ 2358902526 Joystick3Lamp4Cmd 4483;
BA_ "SigType" SG_ 2358902526 Joystick3Lamp3Cmd 4;
BA_ "SPN" SG_ 2358902526 Joystick3Lamp3Cmd 4482;
BA_ "SigType" SG_ 2358902526 Joystick3Lamp2Cmd 4;
BA_ "SPN" SG_ 2358902526 Joystick3Lamp2Cmd 4481;
BA_ "SigType" SG_ 2358902526 Joystick3Lamp1Cmd 4;
BA_ "SPN" SG_ 2358902526 Joystick3Lamp1Cmd 4480;
BA_ "SigType" SG_ 2358902526 Joystick2Lamp10Cmd 4;
BA_ "SPN" SG_ 2358902526 Joystick2Lamp10Cmd 4479;
BA_ "SigType" SG_ 2358902526 Joystick2Lamp9Cmd 4;
BA_ "SPN" SG_ 2358902526 Joystick2Lamp9Cmd 4478;
BA_ "SigType" SG_ 2358902526 Joystick2Lamp8Cmd 4;
BA_ "SPN" SG_ 2358902526 Joystick2Lamp8Cmd 4477;
BA_ "SigType" SG_ 2358902526 Joystick2Lamp7Cmd 4;
BA_ "SPN" SG_ 2358902526 Joystick2Lamp7Cmd 4476;
BA_ "SigType" SG_ 2358902526 Joystick2Lamp6Cmd 4;
BA_ "SPN" SG_ 2358902526 Joystick2Lamp6Cmd 4475;
BA_ "SigType" SG_ 2358902526 Joystick2Lamp5Cmd 4;
BA_ "SPN" SG_ 2358902526 Joystick2Lamp5Cmd 4474;
BA_ "SigType" SG_ 2358902526 Joystick2Lamp4Cmd 4;
BA_ "SPN" SG_ 2358902526 Joystick2Lamp4Cmd 4473;
BA_ "SigType" SG_ 2358902526 Joystick2Lamp3Cmd 4;
BA_ "SPN" SG_ 2358902526 Joystick2Lamp3Cmd 4472;
BA_ "SigType" SG_ 2358902526 Joystick2Lamp2Cmd 4;
BA_ "SPN" SG_ 2358902526 Joystick2Lamp2Cmd 4471;
BA_ "SigType" SG_ 2358902526 Joystick2Lamp1Cmd 4;
BA_ "SPN" SG_ 2358902526 Joystick2Lamp1Cmd 4470;
BA_ "SigType" SG_ 2358902526 Joystick1Lamp10Cmd 4;
BA_ "SPN" SG_ 2358902526 Joystick1Lamp10Cmd 4469;
BA_ "SigType" SG_ 2358902526 Joystick1Lamp9Cmd 4;
BA_ "SPN" SG_ 2358902526 Joystick1Lamp9Cmd 4468;
BA_ "SigType" SG_ 2358902526 Joystick1Lamp8Cmd 4;
BA_ "SPN" SG_ 2358902526 Joystick1Lamp8Cmd 4467;
BA_ "SigType" SG_ 2358902526 Joystick1Lamp7Cmd 4;
BA_ "SPN" SG_ 2358902526 Joystick1Lamp7Cmd 4466;
BA_ "SigType" SG_ 2358902526 Joystick1Lamp6Cmd 4;
BA_ "SPN" SG_ 2358902526 Joystick1Lamp6Cmd 4465;
BA_ "SigType" SG_ 2358902526 Joystick1Lamp5Cmd 4;
BA_ "SPN" SG_ 2358902526 Joystick1Lamp5Cmd 4464;
BA_ "SigType" SG_ 2358902526 Joystick1Lamp4Cmd 4;
BA_ "SPN" SG_ 2358902526 Joystick1Lamp4Cmd 4463;
BA_ "SigType" SG_ 2358902526 Joystick1Lamp3Cmd 4;
BA_ "SPN" SG_ 2358902526 Joystick1Lamp3Cmd 4462;
BA_ "SigType" SG_ 2358902526 Joystick1Lamp2Cmd 4;
BA_ "SPN" SG_ 2358902526 Joystick1Lamp2Cmd 4461;
BA_ "SigType" SG_ 2358902526 Joystick1Lamp1Cmd 4;
BA_ "SPN" SG_ 2358902526 Joystick1Lamp1Cmd 4460;
BA_ "SigType" SG_ 2566711550 IntkVlvActtnSystmOlPrss2SlndCtrl 4;
BA_ "SPN" SG_ 2566711550 IntkVlvActtnSystmOlPrss2SlndCtrl 5500;
BA_ "SigType" SG_ 2566711550 IntkVlvActtnSystmOlPrss1SlndCtrl 4;
BA_ "SPN" SG_ 2566711550 IntkVlvActtnSystmOlPrss1SlndCtrl 5499;
BA_ "SigType" SG_ 2633832958 SpecialIgnitorLoop90Resistance 1;
BA_ "SPN" SG_ 2633832958 SpecialIgnitorLoop90Resistance 4917;
BA_ "SigType" SG_ 2633832958 SpecialIgnitorLoop89Resistance 1;
BA_ "SPN" SG_ 2633832958 SpecialIgnitorLoop89Resistance 4916;
BA_ "SigType" SG_ 2633832958 SpecialIgnitorLoop88Resistance 1;
BA_ "SPN" SG_ 2633832958 SpecialIgnitorLoop88Resistance 4915;
BA_ "SigType" SG_ 2633832958 SpecialIgnitorLoop87Resistance 1;
BA_ "SPN" SG_ 2633832958 SpecialIgnitorLoop87Resistance 4914;
BA_ "SigType" SG_ 2633832958 SpecialIgnitorLoop86Resistance 1;
BA_ "SPN" SG_ 2633832958 SpecialIgnitorLoop86Resistance 4913;
BA_ "SigType" SG_ 2633832958 SpecialIgnitorLoop85Resistance 1;
BA_ "SPN" SG_ 2633832958 SpecialIgnitorLoop85Resistance 4912;
BA_ "SigType" SG_ 2633832958 SpecialIgnitorLoop84Resistance 1;
BA_ "SPN" SG_ 2633832958 SpecialIgnitorLoop84Resistance 4911;
BA_ "SigType" SG_ 2633832958 SpecialIgnitorLoop83Resistance 1;
BA_ "SPN" SG_ 2633832958 SpecialIgnitorLoop83Resistance 4910;
BA_ "SigType" SG_ 2633832958 SpecialIgnitorLoop82Resistance 1;
BA_ "SPN" SG_ 2633832958 SpecialIgnitorLoop82Resistance 4909;
BA_ "SigType" SG_ 2633832958 SpecialIgnitorLoop81Resistance 1;
BA_ "SPN" SG_ 2633832958 SpecialIgnitorLoop81Resistance 4908;
BA_ "SigType" SG_ 2633832958 SpecialIgnitorLoop80Resistance 1;
BA_ "SPN" SG_ 2633832958 SpecialIgnitorLoop80Resistance 4907;
BA_ "SigType" SG_ 2633832958 SpecialIgnitorLoop79Resistance 1;
BA_ "SPN" SG_ 2633832958 SpecialIgnitorLoop79Resistance 4906;
BA_ "SigType" SG_ 2633832958 SpecialIgnitorLoop78Resistance 1;
BA_ "SPN" SG_ 2633832958 SpecialIgnitorLoop78Resistance 4905;
BA_ "SigType" SG_ 2633832958 SpecialIgnitorLoop77Resistance 1;
BA_ "SPN" SG_ 2633832958 SpecialIgnitorLoop77Resistance 4904;
BA_ "SigType" SG_ 2633832958 SpecialIgnitorLoop76Resistance 1;
BA_ "SPN" SG_ 2633832958 SpecialIgnitorLoop76Resistance 4903;
BA_ "SigType" SG_ 2633832958 SpecialIgnitorLoop75Resistance 1;
BA_ "SPN" SG_ 2633832958 SpecialIgnitorLoop75Resistance 4902;
BA_ "SigType" SG_ 2633832958 SpecialIgnitorLoop74Resistance 1;
BA_ "SPN" SG_ 2633832958 SpecialIgnitorLoop74Resistance 4901;
BA_ "SigType" SG_ 2633832958 SpecialIgnitorLoop73Resistance 1;
BA_ "SPN" SG_ 2633832958 SpecialIgnitorLoop73Resistance 4900;
BA_ "SigType" SG_ 2633832958 SpecialIgnitorLoop72Resistance 1;
BA_ "SPN" SG_ 2633832958 SpecialIgnitorLoop72Resistance 4899;
BA_ "SigType" SG_ 2633832958 SpecialIgnitorLoop71Resistance 1;
BA_ "SPN" SG_ 2633832958 SpecialIgnitorLoop71Resistance 4898;
BA_ "SigType" SG_ 2633832958 SpecialIgnitorLoop70Resistance 1;
BA_ "SPN" SG_ 2633832958 SpecialIgnitorLoop70Resistance 4897;
BA_ "SigType" SG_ 2633832958 SpecialIgnitorLoop69Resistance 1;
BA_ "SPN" SG_ 2633832958 SpecialIgnitorLoop69Resistance 4896;
BA_ "SigType" SG_ 2633832958 SpecialIgnitorLoop68Resistance 1;
BA_ "SPN" SG_ 2633832958 SpecialIgnitorLoop68Resistance 4895;
BA_ "SigType" SG_ 2633832958 SpecialIgnitorLoop67Resistance 1;
BA_ "SPN" SG_ 2633832958 SpecialIgnitorLoop67Resistance 4894;
BA_ "SigType" SG_ 2633832958 SpecialIgnitorLoop66Resistance 1;
BA_ "SPN" SG_ 2633832958 SpecialIgnitorLoop66Resistance 4893;
BA_ "SigType" SG_ 2633832958 SpecialIgnitorLoop65Resistance 1;
BA_ "SPN" SG_ 2633832958 SpecialIgnitorLoop65Resistance 4892;
BA_ "SigType" SG_ 2633832958 SpecialIgnitorLoop64Resistance 1;
BA_ "SPN" SG_ 2633832958 SpecialIgnitorLoop64Resistance 4891;
BA_ "SigType" SG_ 2633832958 SpecialIgnitorLoop63Resistance 1;
BA_ "SPN" SG_ 2633832958 SpecialIgnitorLoop63Resistance 4890;
BA_ "SigType" SG_ 2633832958 SpecialIgnitorLoop61Resistance 1;
BA_ "SPN" SG_ 2633832958 SpecialIgnitorLoop61Resistance 4888;
BA_ "SigType" SG_ 2633832958 SpecialIgnitorLoop60Resistance 1;
BA_ "SPN" SG_ 2633832958 SpecialIgnitorLoop60Resistance 4887;
BA_ "SigType" SG_ 2633832958 SpecialIgnitorLoop59Resistance 1;
BA_ "SPN" SG_ 2633832958 SpecialIgnitorLoop59Resistance 4886;
BA_ "SigType" SG_ 2633832958 SpecialIgnitorLoop58Resistance 1;
BA_ "SPN" SG_ 2633832958 SpecialIgnitorLoop58Resistance 4885;
BA_ "SigType" SG_ 2633832958 SpecialIgnitorLoop57Resistance 1;
BA_ "SPN" SG_ 2633832958 SpecialIgnitorLoop57Resistance 4884;
BA_ "SigType" SG_ 2633832958 SpecialIgnitorLoop56Resistance 1;
BA_ "SPN" SG_ 2633832958 SpecialIgnitorLoop56Resistance 4883;
BA_ "SigType" SG_ 2633832958 SpecialIgnitorLoop55Resistance 1;
BA_ "SPN" SG_ 2633832958 SpecialIgnitorLoop55Resistance 4882;
BA_ "SigType" SG_ 2633832958 SpecialIgnitorLoop54Resistance 1;
BA_ "SPN" SG_ 2633832958 SpecialIgnitorLoop54Resistance 4881;
BA_ "SigType" SG_ 2633832958 SpecialIgnitorLoop53Resistance 1;
BA_ "SPN" SG_ 2633832958 SpecialIgnitorLoop53Resistance 4880;
BA_ "SigType" SG_ 2633832958 SpecialIgnitorLoop52Resistance 1;
BA_ "SPN" SG_ 2633832958 SpecialIgnitorLoop52Resistance 4879;
BA_ "SigType" SG_ 2633832958 SpecialIgnitorLoop51Resistance 1;
BA_ "SPN" SG_ 2633832958 SpecialIgnitorLoop51Resistance 4878;
BA_ "SigType" SG_ 2633832958 SpecialIgnitorLoop50Resistance 1;
BA_ "SPN" SG_ 2633832958 SpecialIgnitorLoop50Resistance 4877;
BA_ "SigType" SG_ 2633832958 SpecialIgnitorLoop49Resistance 1;
BA_ "SPN" SG_ 2633832958 SpecialIgnitorLoop49Resistance 4876;
BA_ "SigType" SG_ 2633832958 SpecialIgnitorLoop48Resistance 1;
BA_ "SPN" SG_ 2633832958 SpecialIgnitorLoop48Resistance 4875;
BA_ "SigType" SG_ 2633832958 SpecialIgnitorLoop47Resistance 1;
BA_ "SPN" SG_ 2633832958 SpecialIgnitorLoop47Resistance 4874;
BA_ "SigType" SG_ 2633832958 SpecialIgnitorLoop46Resistance 1;
BA_ "SPN" SG_ 2633832958 SpecialIgnitorLoop46Resistance 4873;
BA_ "SigType" SG_ 2633832958 SpecialIgnitorLoop45Resistance 1;
BA_ "SPN" SG_ 2633832958 SpecialIgnitorLoop45Resistance 4872;
BA_ "SigType" SG_ 2633832958 SpecialIgnitorLoop44Resistance 1;
BA_ "SPN" SG_ 2633832958 SpecialIgnitorLoop44Resistance 4871;
BA_ "SigType" SG_ 2633832958 SpecialIgnitorLoop43Resistance 1;
BA_ "SPN" SG_ 2633832958 SpecialIgnitorLoop43Resistance 4870;
BA_ "SigType" SG_ 2633832958 SpecialIgnitorLoop42Resistance 1;
BA_ "SPN" SG_ 2633832958 SpecialIgnitorLoop42Resistance 4869;
BA_ "SigType" SG_ 2633832958 SpecialIgnitorLoop41Resistance 1;
BA_ "SPN" SG_ 2633832958 SpecialIgnitorLoop41Resistance 4868;
BA_ "SigType" SG_ 2633832958 SpecialIgnitorLoop40Resistance 1;
BA_ "SPN" SG_ 2633832958 SpecialIgnitorLoop40Resistance 4867;
BA_ "SigType" SG_ 2633832958 SpecialIgnitorLoop39Resistance 1;
BA_ "SPN" SG_ 2633832958 SpecialIgnitorLoop39Resistance 4866;
BA_ "SigType" SG_ 2633832958 SpecialIgnitorLoop38Resistance 1;
BA_ "SPN" SG_ 2633832958 SpecialIgnitorLoop38Resistance 4865;
BA_ "SigType" SG_ 2633832958 SpecialIgnitorLoop37Resistance 1;
BA_ "SPN" SG_ 2633832958 SpecialIgnitorLoop37Resistance 4864;
BA_ "SigType" SG_ 2633832958 SpecialIgnitorLoop36Resistance 1;
BA_ "SPN" SG_ 2633832958 SpecialIgnitorLoop36Resistance 4863;
BA_ "SigType" SG_ 2633832958 SpecialIgnitorLoop35Resistance 1;
BA_ "SPN" SG_ 2633832958 SpecialIgnitorLoop35Resistance 4862;
BA_ "SigType" SG_ 2633832958 SpecialIgnitorLoop34Resistance 1;
BA_ "SPN" SG_ 2633832958 SpecialIgnitorLoop34Resistance 4861;
BA_ "SigType" SG_ 2633832958 SpecialIgnitorLoop33Resistance 1;
BA_ "SPN" SG_ 2633832958 SpecialIgnitorLoop33Resistance 4860;
BA_ "SigType" SG_ 2633832958 SpecialIgnitorLoop32Resistance 1;
BA_ "SPN" SG_ 2633832958 SpecialIgnitorLoop32Resistance 4859;
BA_ "SigType" SG_ 2633832958 SpecialIgnitorLoop31Resistance 1;
BA_ "SPN" SG_ 2633832958 SpecialIgnitorLoop31Resistance 4858;
BA_ "SigType" SG_ 2633832958 SpecialIgnitorLoop30Resistance 1;
BA_ "SPN" SG_ 2633832958 SpecialIgnitorLoop30Resistance 4857;
BA_ "SigType" SG_ 2633832958 SpecialIgnitorLoop29Resistance 1;
BA_ "SPN" SG_ 2633832958 SpecialIgnitorLoop29Resistance 4856;
BA_ "SigType" SG_ 2633832958 SpecialIgnitorLoop28Resistance 1;
BA_ "SPN" SG_ 2633832958 SpecialIgnitorLoop28Resistance 4855;
BA_ "SigType" SG_ 2633832958 SpecialIgnitorLoop27Resistance 1;
BA_ "SPN" SG_ 2633832958 SpecialIgnitorLoop27Resistance 4854;
BA_ "SigType" SG_ 2633832958 SpecialIgnitorLoop26Resistance 1;
BA_ "SPN" SG_ 2633832958 SpecialIgnitorLoop26Resistance 4853;
BA_ "SigType" SG_ 2633832958 SpecialIgnitorLoop25Resistance 1;
BA_ "SPN" SG_ 2633832958 SpecialIgnitorLoop25Resistance 4852;
BA_ "SigType" SG_ 2633832958 SpecialIgnitorLoop24Resistance 1;
BA_ "SPN" SG_ 2633832958 SpecialIgnitorLoop24Resistance 4851;
BA_ "SigType" SG_ 2633832958 SpecialIgnitorLoop23Resistance 1;
BA_ "SPN" SG_ 2633832958 SpecialIgnitorLoop23Resistance 4850;
BA_ "SigType" SG_ 2633832958 SpecialIgnitorLoop22Resistance 1;
BA_ "SPN" SG_ 2633832958 SpecialIgnitorLoop22Resistance 4849;
BA_ "SigType" SG_ 2633832958 SpecialIgnitorLoop21Resistance 1;
BA_ "SPN" SG_ 2633832958 SpecialIgnitorLoop21Resistance 4848;
BA_ "SigType" SG_ 2633832958 SpecialIgnitorLoop20Resistance 1;
BA_ "SPN" SG_ 2633832958 SpecialIgnitorLoop20Resistance 4847;
BA_ "SigType" SG_ 2633832958 SpecialIgnitorLoop19Resistance 1;
BA_ "SPN" SG_ 2633832958 SpecialIgnitorLoop19Resistance 4846;
BA_ "SigType" SG_ 2633832958 SpecialIgnitorLoop18Resistance 1;
BA_ "SPN" SG_ 2633832958 SpecialIgnitorLoop18Resistance 4845;
BA_ "SigType" SG_ 2633832958 SpecialIgnitorLoop17Resistance 1;
BA_ "SPN" SG_ 2633832958 SpecialIgnitorLoop17Resistance 4844;
BA_ "SigType" SG_ 2633832958 SpecialIgnitorLoop16Resistance 1;
BA_ "SPN" SG_ 2633832958 SpecialIgnitorLoop16Resistance 4843;
BA_ "SigType" SG_ 2633832958 SpecialIgnitorLoop15Resistance 1;
BA_ "SPN" SG_ 2633832958 SpecialIgnitorLoop15Resistance 4842;
BA_ "SigType" SG_ 2633832958 SpecialIgnitorLoop14Resistance 1;
BA_ "SPN" SG_ 2633832958 SpecialIgnitorLoop14Resistance 4841;
BA_ "SigType" SG_ 2633832958 SpecialIgnitorLoop13Resistance 1;
BA_ "SPN" SG_ 2633832958 SpecialIgnitorLoop13Resistance 4840;
BA_ "SigType" SG_ 2633832958 SpecialIgnitorLoop12Resistance 1;
BA_ "SPN" SG_ 2633832958 SpecialIgnitorLoop12Resistance 4839;
BA_ "SigType" SG_ 2633832958 SpecialIgnitorLoop11Resistance 1;
BA_ "SPN" SG_ 2633832958 SpecialIgnitorLoop11Resistance 4838;
BA_ "SigType" SG_ 2633832958 SpecialIgnitorLoop10Resistance 1;
BA_ "SPN" SG_ 2633832958 SpecialIgnitorLoop10Resistance 4837;
BA_ "SigType" SG_ 2633832958 SpecialIgnitorLoop9Resistance 1;
BA_ "SPN" SG_ 2633832958 SpecialIgnitorLoop9Resistance 4836;
BA_ "SigType" SG_ 2633832958 SpecialIgnitorLoop8Resistance 1;
BA_ "SPN" SG_ 2633832958 SpecialIgnitorLoop8Resistance 4835;
BA_ "SigType" SG_ 2633832958 SpecialIgnitorLoop7Resistance 1;
BA_ "SPN" SG_ 2633832958 SpecialIgnitorLoop7Resistance 4834;
BA_ "SigType" SG_ 2633832958 SpecialIgnitorLoop6Resistance 1;
BA_ "SPN" SG_ 2633832958 SpecialIgnitorLoop6Resistance 4833;
BA_ "SigType" SG_ 2633832958 SpecialIgnitorLoop5Resistance 1;
BA_ "SPN" SG_ 2633832958 SpecialIgnitorLoop5Resistance 4832;
BA_ "SigType" SG_ 2633832958 SpecialIgnitorLoop4Resistance 1;
BA_ "SPN" SG_ 2633832958 SpecialIgnitorLoop4Resistance 4831;
BA_ "SigType" SG_ 2633832958 SpecialIgnitorLoop3Resistance 1;
BA_ "SPN" SG_ 2633832958 SpecialIgnitorLoop3Resistance 4830;
BA_ "SigType" SG_ 2633832958 SpecialIgnitorLoop2Resistance 1;
BA_ "SPN" SG_ 2633832958 SpecialIgnitorLoop2Resistance 4829;
BA_ "SigType" SG_ 2633832958 SpecialIgnitorLoop1Resistance 1;
BA_ "SPN" SG_ 2633832958 SpecialIgnitorLoop1Resistance 4828;
BA_ "SigType" SG_ 2633832958 SdBgIgnitorLoop2RightResistance 1;
BA_ "SPN" SG_ 2633832958 SdBgIgnitorLoop2RightResistance 4827;
BA_ "SigType" SG_ 2633832958 SdBgIgnitorLoop1RightResistance 1;
BA_ "SPN" SG_ 2633832958 SdBgIgnitorLoop1RightResistance 4826;
BA_ "SigType" SG_ 2633832958 SdBagIgnitorLoop2LeftResistance 1;
BA_ "SPN" SG_ 2633832958 SdBagIgnitorLoop2LeftResistance 4825;
BA_ "SigType" SG_ 2633832958 SdBagIgnitorLoop1LeftResistance 1;
BA_ "SPN" SG_ 2633832958 SdBagIgnitorLoop1LeftResistance 4824;
BA_ "SigType" SG_ 2633832958 PssngrBltTnsnrIgntrLpResistance 1;
BA_ "SPN" SG_ 2633832958 PssngrBltTnsnrIgntrLpResistance 4823;
BA_ "SigType" SG_ 2633832958 DrvrBltTnsnrIgntrLoopResistance 1;
BA_ "SPN" SG_ 2633832958 DrvrBltTnsnrIgntrLoopResistance 4822;
BA_ "SigType" SG_ 2633832958 PssngrArbgIgntrLp2ndStgRsstance 1;
BA_ "SPN" SG_ 2633832958 PssngrArbgIgntrLp2ndStgRsstance 4821;
BA_ "SigType" SG_ 2633832958 DrvrArbgIgntrLp2ndStgResistance 1;
BA_ "SPN" SG_ 2633832958 DrvrArbgIgntrLp2ndStgResistance 4820;
BA_ "SigType" SG_ 2633832958 PssngrArbgIgntrLp1stStgRsstance 1;
BA_ "SPN" SG_ 2633832958 PssngrArbgIgntrLp1stStgRsstance 4819;
BA_ "SigType" SG_ 2633832958 DrvrArbgIgntrLp1stStgResistance 1;
BA_ "SPN" SG_ 2633832958 DrvrArbgIgntrLp1stStgResistance 4818;
BA_ "SigType" SG_ 2566719998 HighResolutionEngTotalFuelUsed 1;
BA_ "SPN" SG_ 2566719998 HighResolutionEngTotalFuelUsed 5054;
BA_ "SigType" SG_ 2566719998 HighResolutionEngTripFuel 1;
BA_ "SPN" SG_ 2566719998 HighResolutionEngTripFuel 5053;
BA_ "SigType" SG_ 2565877502 EngTurboWastegateActuator2Cmd 1;
BA_ "SPN" SG_ 2565877502 EngTurboWastegateActuator2Cmd 5387;
BA_ "SigType" SG_ 2565877502 EngTurboWastegateActuator1Cmd 1;
BA_ "SPN" SG_ 2565877502 EngTurboWastegateActuator1Cmd 5386;
BA_ "SigType" SG_ 2566713854 EngTrbWstgtActtr2OprationStatus 4;
BA_ "SPN" SG_ 2566713854 EngTrbWstgtActtr2OprationStatus 5452;
BA_ "SigType" SG_ 2566713854 EngTrbWstgtActtr1OprationStatus 4;
BA_ "SPN" SG_ 2566713854 EngTrbWstgtActtr1OprationStatus 5451;
BA_ "SigType" SG_ 2566713854 EngTrbWstgteActuator2TempStatus 4;
BA_ "SPN" SG_ 2566713854 EngTrbWstgteActuator2TempStatus 5385;
BA_ "SigType" SG_ 2566713854 EngTrbWstgtActtr2PreliminaryFMI 1;
BA_ "SPN" SG_ 2566713854 EngTrbWstgtActtr2PreliminaryFMI 5384;
BA_ "SigType" SG_ 2566714366 EngTrbCmprssrBypssActtr2OprtnStt 4;
BA_ "SPN" SG_ 2566714366 EngTrbCmprssrBypssActtr2OprtnStt 5450;
BA_ "SystemSignalLongSymbol" SG_ 2566714366 EngTrbCmprssrBypssActtr2OprtnStt "EngTrbCmprssrBypssActtr2OprtnStts";
BA_ "SigType" SG_ 2566714366 EngTrbCmprssrBypssActtr1OprtnStt 4;
BA_ "SPN" SG_ 2566714366 EngTrbCmprssrBypssActtr1OprtnStt 5449;
BA_ "SystemSignalLongSymbol" SG_ 2566714366 EngTrbCmprssrBypssActtr1OprtnStt "EngTrbCmprssrBypssActtr1OprtnStts";
BA_ "SigType" SG_ 2566714366 EngTrbCmprssrBypssActtr2TmpStts 4;
BA_ "SPN" SG_ 2566714366 EngTrbCmprssrBypssActtr2TmpStts 5391;
BA_ "SigType" SG_ 2566714366 EngTrbCmprssrBypssActtr2PrlmnryF 1;
BA_ "SPN" SG_ 2566714366 EngTrbCmprssrBypssActtr2PrlmnryF 5390;
BA_ "SystemSignalLongSymbol" SG_ 2566714366 EngTrbCmprssrBypssActtr2PrlmnryF "EngTrbCmprssrBypssActtr2PrlmnryFMI";
BA_ "SigType" SG_ 2566714366 EngDsrdTrbCmprssrBypssActtr2Pos 1;
BA_ "SPN" SG_ 2566714366 EngDsrdTrbCmprssrBypssActtr2Pos 5389;
BA_ "SigType" SG_ 2566714366 EngTrbCmprssrBypassActuator2Pos 1;
BA_ "SPN" SG_ 2566714366 EngTrbCmprssrBypassActuator2Pos 5388;
BA_ "SigType" SG_ 2566714110 EngFuelValve2OperationStatus 4;
BA_ "SPN" SG_ 2566714110 EngFuelValve2OperationStatus 5448;
BA_ "SigType" SG_ 2566714110 EngFuelValve1OperationStatus 4;
BA_ "SPN" SG_ 2566714110 EngFuelValve1OperationStatus 5447;
BA_ "SigType" SG_ 2566714110 EngThrttleValve2OperationStatus 4;
BA_ "SPN" SG_ 2566714110 EngThrttleValve2OperationStatus 5446;
BA_ "SigType" SG_ 2566714110 EngThrttleValve1OperationStatus 4;
BA_ "SPN" SG_ 2566714110 EngThrttleValve1OperationStatus 5445;
BA_ "SigType" SG_ 2566714110 EngFuelValve2TempStatus 4;
BA_ "SPN" SG_ 2566714110 EngFuelValve2TempStatus 5383;
BA_ "SigType" SG_ 2566714110 EngFuelValve2PreliminaryFMI 1;
BA_ "SPN" SG_ 2566714110 EngFuelValve2PreliminaryFMI 5382;
BA_ "SigType" SG_ 2566714110 EngFuelValve1TempStatus 4;
BA_ "SPN" SG_ 2566714110 EngFuelValve1TempStatus 5381;
BA_ "SigType" SG_ 2566714110 EngFuelValve1PreliminaryFMI 1;
BA_ "SPN" SG_ 2566714110 EngFuelValve1PreliminaryFMI 5380;
BA_ "SigType" SG_ 2566714110 EngThrottleValve2TempStatus 4;
BA_ "SPN" SG_ 2566714110 EngThrottleValve2TempStatus 5379;
BA_ "SigType" SG_ 2566714110 EngThrottleValve2PreliminaryFMI 1;
BA_ "SPN" SG_ 2566714110 EngThrottleValve2PreliminaryFMI 5378;
BA_ "SigType" SG_ 2566714110 EngDesiredThrottleValve2Pos 1;
BA_ "SPN" SG_ 2566714110 EngDesiredThrottleValve2Pos 5377;
BA_ "SigType" SG_ 2566714110 EngThrottleValve1TempStatus 4;
BA_ "SPN" SG_ 2566714110 EngThrottleValve1TempStatus 5376;
BA_ "SigType" SG_ 2566714110 EngThrottleValve1PreliminaryFMI 1;
BA_ "SPN" SG_ 2566714110 EngThrottleValve1PreliminaryFMI 5375;
BA_ "SigType" SG_ 2566714110 EngDesiredThrottleValve1Pos 1;
BA_ "SPN" SG_ 2566714110 EngDesiredThrottleValve1Pos 5374;
BA_ "SigType" SG_ 2566717438 EngExhstGsRcrcltn2MxrIntakeTemp 1;
BA_ "SPN" SG_ 2566717438 EngExhstGsRcrcltn2MxrIntakeTemp 5256;
BA_ "SigType" SG_ 2566717438 EngExhaustGasRecirculation2Temp 1;
BA_ "SPN" SG_ 2566717438 EngExhaustGasRecirculation2Temp 5255;
BA_ "SigType" SG_ 2633828606 EngOilRelativeDielectricity 1;
BA_ "SPN" SG_ 2633828606 EngOilRelativeDielectricity 5468;
BA_ "SigType" SG_ 2633828606 EngOilDensity 1;
BA_ "SPN" SG_ 2633828606 EngOilDensity 5056;
BA_ "SigType" SG_ 2633828606 EngOilViscosity 1;
BA_ "SPN" SG_ 2633828606 EngOilViscosity 5055;
BA_ "SigType" SG_ 2499607550 EngExhstMnfldBnk2FlwBlncVlvActtr 1;
BA_ "SPN" SG_ 2499607550 EngExhstMnfldBnk2FlwBlncVlvActtr 5279;
BA_ "SystemSignalLongSymbol" SG_ 2499607550 EngExhstMnfldBnk2FlwBlncVlvActtr "EngExhstMnfldBnk2FlwBlncVlvActtrPs";
BA_ "SigType" SG_ 2499607550 EngExhstMnfldBnk1FlwBlncVlvActtr 1;
BA_ "SPN" SG_ 2499607550 EngExhstMnfldBnk1FlwBlncVlvActtr 5277;
BA_ "SystemSignalLongSymbol" SG_ 2499607550 EngExhstMnfldBnk1FlwBlncVlvActtr "EngExhstMnfldBnk1FlwBlncVlvActtrPs";
BA_ "SigType" SG_ 2633825534 EngExhstMnfldBnk2FlwBlncVlv_0000 1;
BA_ "SPN" SG_ 2633825534 EngExhstMnfldBnk2FlwBlncVlv_0000 5278;
BA_ "SystemSignalLongSymbol" SG_ 2633825534 EngExhstMnfldBnk2FlwBlncVlv_0000 "EngExhstMnfldBnk2FlwBlncVlvActtrCtrl";
BA_ "SigType" SG_ 2633825534 EngExhstMnfldBnk1FlwBlncVlv_0000 1;
BA_ "SPN" SG_ 2633825534 EngExhstMnfldBnk1FlwBlncVlv_0000 5276;
BA_ "SystemSignalLongSymbol" SG_ 2633825534 EngExhstMnfldBnk1FlwBlncVlv_0000 "EngExhstMnfldBnk1FlwBlncVlvActtrCtrl";
BA_ "SigType" SG_ 2365400574 Jystck9GripXAxisDetentPosStatus 4;
BA_ "SPN" SG_ 2365400574 Jystck9GripXAxisDetentPosStatus 4712;
BA_ "SigType" SG_ 2365400574 Jystck9GripYAxisDetentPosStatus 4;
BA_ "SPN" SG_ 2365400574 Jystck9GripYAxisDetentPosStatus 4711;
BA_ "SigType" SG_ 2365400574 Jystck9ThetaAxisDetentPosStatus 4;
BA_ "SPN" SG_ 2365400574 Jystck9ThetaAxisDetentPosStatus 4710;
BA_ "SigType" SG_ 2365400574 Joystick9ThetaAxisPos 1;
BA_ "SPN" SG_ 2365400574 Joystick9ThetaAxisPos 4709;
BA_ "SigType" SG_ 2365400574 Jystck9ThtAxsClckwsPstvPsStatus 4;
BA_ "SPN" SG_ 2365400574 Jystck9ThtAxsClckwsPstvPsStatus 4708;
BA_ "SigType" SG_ 2365400574 Jystck9ThtAxsCntrClckwsNgtvPsStt 4;
BA_ "SPN" SG_ 2365400574 Jystck9ThtAxsCntrClckwsNgtvPsStt 4707;
BA_ "SystemSignalLongSymbol" SG_ 2365400574 Jystck9ThtAxsCntrClckwsNgtvPsStt "Jystck9ThtAxsCntrClckwsNgtvPsStts";
BA_ "SigType" SG_ 2365400574 Jystck9ThtaAxisNeutralPosStatus 4;
BA_ "SPN" SG_ 2365400574 Jystck9ThtaAxisNeutralPosStatus 4706;
BA_ "SigType" SG_ 2365400574 Joystick9GripYAxisPos 1;
BA_ "SPN" SG_ 2365400574 Joystick9GripYAxisPos 4705;
BA_ "SigType" SG_ 2365400574 Jystck9GrpYAxsLvrFrwrdPstvPsStts 4;
BA_ "SPN" SG_ 2365400574 Jystck9GrpYAxsLvrFrwrdPstvPsStts 4704;
BA_ "SigType" SG_ 2365400574 Jystck9GrpYAxsLvrBckNgtvPsSttus 4;
BA_ "SPN" SG_ 2365400574 Jystck9GrpYAxsLvrBckNgtvPsSttus 4703;
BA_ "SigType" SG_ 2365400574 Jystck9GrpYAxisNeutralPosStatus 4;
BA_ "SPN" SG_ 2365400574 Jystck9GrpYAxisNeutralPosStatus 4702;
BA_ "SigType" SG_ 2365400574 Joystick9GripXAxisPos 1;
BA_ "SPN" SG_ 2365400574 Joystick9GripXAxisPos 4701;
BA_ "SigType" SG_ 2365400574 Jystck9GrpXAxsLvrRghtPstvPsStts 4;
BA_ "SPN" SG_ 2365400574 Jystck9GrpXAxsLvrRghtPstvPsStts 4700;
BA_ "SigType" SG_ 2365400574 Jystck9GrpXAxsLvrLftNgtvPsSttus 4;
BA_ "SPN" SG_ 2365400574 Jystck9GrpXAxsLvrLftNgtvPsSttus 4699;
BA_ "SigType" SG_ 2365400574 Jystck9GrpXAxisNeutralPosStatus 4;
BA_ "SPN" SG_ 2365400574 Jystck9GrpXAxisNeutralPosStatus 4698;
BA_ "SigType" SG_ 2365401086 Jystck8GripXAxisDetentPosStatus 4;
BA_ "SPN" SG_ 2365401086 Jystck8GripXAxisDetentPosStatus 4675;
BA_ "SigType" SG_ 2365401086 Jystck8GripYAxisDetentPosStatus 4;
BA_ "SPN" SG_ 2365401086 Jystck8GripYAxisDetentPosStatus 4674;
BA_ "SigType" SG_ 2365401086 Jystck8ThetaAxisDetentPosStatus 4;
BA_ "SPN" SG_ 2365401086 Jystck8ThetaAxisDetentPosStatus 4673;
BA_ "SigType" SG_ 2365401086 Joystick8ThetaAxisPos 1;
BA_ "SPN" SG_ 2365401086 Joystick8ThetaAxisPos 4672;
BA_ "SigType" SG_ 2365401086 Jystck8ThtAxsClckwsPstvPsStatus 4;
BA_ "SPN" SG_ 2365401086 Jystck8ThtAxsClckwsPstvPsStatus 4671;
BA_ "SigType" SG_ 2365401086 Jystck8ThtAxsCntrClckwsNgtvPsStt 4;
BA_ "SPN" SG_ 2365401086 Jystck8ThtAxsCntrClckwsNgtvPsStt 4670;
BA_ "SystemSignalLongSymbol" SG_ 2365401086 Jystck8ThtAxsCntrClckwsNgtvPsStt "Jystck8ThtAxsCntrClckwsNgtvPsStts";
BA_ "SigType" SG_ 2365401086 Jystck8ThtaAxisNeutralPosStatus 4;
BA_ "SPN" SG_ 2365401086 Jystck8ThtaAxisNeutralPosStatus 4669;
BA_ "SigType" SG_ 2365401086 Joystick8GripYAxisPos 1;
BA_ "SPN" SG_ 2365401086 Joystick8GripYAxisPos 4668;
BA_ "SigType" SG_ 2365401086 Jystck8GrpYAxsLvrFrwrdPstvPsStts 4;
BA_ "SPN" SG_ 2365401086 Jystck8GrpYAxsLvrFrwrdPstvPsStts 4667;
BA_ "SigType" SG_ 2365401086 Jystck8GrpYAxsLvrBckNgtvPsSttus 4;
BA_ "SPN" SG_ 2365401086 Jystck8GrpYAxsLvrBckNgtvPsSttus 4666;
BA_ "SigType" SG_ 2365401086 Jystck8GrpYAxisNeutralPosStatus 4;
BA_ "SPN" SG_ 2365401086 Jystck8GrpYAxisNeutralPosStatus 4665;
BA_ "SigType" SG_ 2365401086 Joystick8GripXAxisPos 1;
BA_ "SPN" SG_ 2365401086 Joystick8GripXAxisPos 4664;
BA_ "SigType" SG_ 2365401086 Jystck8GrpXAxsLvrRghtPstvPsStts 4;
BA_ "SPN" SG_ 2365401086 Jystck8GrpXAxsLvrRghtPstvPsStts 4663;
BA_ "SigType" SG_ 2365401086 Jystck8GrpXAxsLvrLftNgtvPsSttus 4;
BA_ "SPN" SG_ 2365401086 Jystck8GrpXAxsLvrLftNgtvPsSttus 4662;
BA_ "SigType" SG_ 2365401086 Jystck8GrpXAxisNeutralPosStatus 4;
BA_ "SPN" SG_ 2365401086 Jystck8GrpXAxisNeutralPosStatus 4661;
BA_ "SigType" SG_ 2365401598 Jystck7GripXAxisDetentPosStatus 4;
BA_ "SPN" SG_ 2365401598 Jystck7GripXAxisDetentPosStatus 4638;
BA_ "SigType" SG_ 2365401598 Jystck7GripYAxisDetentPosStatus 4;
BA_ "SPN" SG_ 2365401598 Jystck7GripYAxisDetentPosStatus 4637;
BA_ "SigType" SG_ 2365401598 Jystck7ThetaAxisDetentPosStatus 4;
BA_ "SPN" SG_ 2365401598 Jystck7ThetaAxisDetentPosStatus 4636;
BA_ "SigType" SG_ 2365401598 Joystick7ThetaAxisPos 1;
BA_ "SPN" SG_ 2365401598 Joystick7ThetaAxisPos 4635;
BA_ "SigType" SG_ 2365401598 Jystck7ThtAxsClckwsPstvPsStatus 4;
BA_ "SPN" SG_ 2365401598 Jystck7ThtAxsClckwsPstvPsStatus 4634;
BA_ "SigType" SG_ 2365401598 Jystck7ThtAxsCntrClckwsNgtvPsStt 4;
BA_ "SPN" SG_ 2365401598 Jystck7ThtAxsCntrClckwsNgtvPsStt 4633;
BA_ "SystemSignalLongSymbol" SG_ 2365401598 Jystck7ThtAxsCntrClckwsNgtvPsStt "Jystck7ThtAxsCntrClckwsNgtvPsStts";
BA_ "SigType" SG_ 2365401598 Jystck7ThtaAxisNeutralPosStatus 4;
BA_ "SPN" SG_ 2365401598 Jystck7ThtaAxisNeutralPosStatus 4632;
BA_ "SigType" SG_ 2365401598 Joystick7GripYAxisPos 1;
BA_ "SPN" SG_ 2365401598 Joystick7GripYAxisPos 4631;
BA_ "SigType" SG_ 2365401598 Jystck7GrpYAxsLvrFrwrdPstvPsStts 4;
BA_ "SPN" SG_ 2365401598 Jystck7GrpYAxsLvrFrwrdPstvPsStts 4630;
BA_ "SigType" SG_ 2365401598 Jystck7GrpYAxsLvrBckNgtvPsSttus 4;
BA_ "SPN" SG_ 2365401598 Jystck7GrpYAxsLvrBckNgtvPsSttus 4629;
BA_ "SigType" SG_ 2365401598 Jystck7GrpYAxisNeutralPosStatus 4;
BA_ "SPN" SG_ 2365401598 Jystck7GrpYAxisNeutralPosStatus 4628;
BA_ "SigType" SG_ 2365401598 Joystick7GripXAxisPos 1;
BA_ "SPN" SG_ 2365401598 Joystick7GripXAxisPos 4627;
BA_ "SigType" SG_ 2365401598 Jystck7GrpXAxsLvrRghtPstvPsStts 4;
BA_ "SPN" SG_ 2365401598 Jystck7GrpXAxsLvrRghtPstvPsStts 4626;
BA_ "SigType" SG_ 2365401598 Jystck7GrpXAxsLvrLftNgtvPsSttus 4;
BA_ "SPN" SG_ 2365401598 Jystck7GrpXAxsLvrLftNgtvPsSttus 4625;
BA_ "SigType" SG_ 2365401598 Jystck7GrpXAxisNeutralPosStatus 4;
BA_ "SPN" SG_ 2365401598 Jystck7GrpXAxisNeutralPosStatus 4624;
BA_ "SigType" SG_ 2365402110 Jystck6GripXAxisDetentPosStatus 4;
BA_ "SPN" SG_ 2365402110 Jystck6GripXAxisDetentPosStatus 4601;
BA_ "SigType" SG_ 2365402110 Jystck6GripYAxisDetentPosStatus 4;
BA_ "SPN" SG_ 2365402110 Jystck6GripYAxisDetentPosStatus 4600;
BA_ "SigType" SG_ 2365402110 Jystck6ThetaAxisDetentPosStatus 4;
BA_ "SPN" SG_ 2365402110 Jystck6ThetaAxisDetentPosStatus 4599;
BA_ "SigType" SG_ 2365402110 Joystick6ThetaAxisPos 1;
BA_ "SPN" SG_ 2365402110 Joystick6ThetaAxisPos 4598;
BA_ "SigType" SG_ 2365402110 Jystck6ThtAxsClckwsPstvPsStatus 4;
BA_ "SPN" SG_ 2365402110 Jystck6ThtAxsClckwsPstvPsStatus 4597;
BA_ "SigType" SG_ 2365402110 Jystck6ThtAxsCntrClckwsNgtvPsStt 4;
BA_ "SPN" SG_ 2365402110 Jystck6ThtAxsCntrClckwsNgtvPsStt 4596;
BA_ "SystemSignalLongSymbol" SG_ 2365402110 Jystck6ThtAxsCntrClckwsNgtvPsStt "Jystck6ThtAxsCntrClckwsNgtvPsStts";
BA_ "SigType" SG_ 2365402110 Jystck6ThtaAxisNeutralPosStatus 4;
BA_ "SPN" SG_ 2365402110 Jystck6ThtaAxisNeutralPosStatus 4595;
BA_ "SigType" SG_ 2365402110 Joystick6GripYAxisPos 1;
BA_ "SPN" SG_ 2365402110 Joystick6GripYAxisPos 4594;
BA_ "SigType" SG_ 2365402110 Jystck6GrpYAxsLvrFrwrdPstvPsStts 4;
BA_ "SPN" SG_ 2365402110 Jystck6GrpYAxsLvrFrwrdPstvPsStts 4593;
BA_ "SigType" SG_ 2365402110 Jystck6GrpYAxsLvrBckNgtvPsSttus 4;
BA_ "SPN" SG_ 2365402110 Jystck6GrpYAxsLvrBckNgtvPsSttus 4592;
BA_ "SigType" SG_ 2365402110 Jystck6GrpYAxisNeutralPosStatus 4;
BA_ "SPN" SG_ 2365402110 Jystck6GrpYAxisNeutralPosStatus 4591;
BA_ "SigType" SG_ 2365402110 Joystick6GripXAxisPos 1;
BA_ "SPN" SG_ 2365402110 Joystick6GripXAxisPos 4590;
BA_ "SigType" SG_ 2365402110 Jystck6GrpXAxsLvrRghtPstvPsStts 4;
BA_ "SPN" SG_ 2365402110 Jystck6GrpXAxsLvrRghtPstvPsStts 4589;
BA_ "SigType" SG_ 2365402110 Jystck6GrpXAxsLvrLftNgtvPsSttus 4;
BA_ "SPN" SG_ 2365402110 Jystck6GrpXAxsLvrLftNgtvPsSttus 4588;
BA_ "SigType" SG_ 2365402110 Jystck6GrpXAxisNeutralPosStatus 4;
BA_ "SPN" SG_ 2365402110 Jystck6GrpXAxisNeutralPosStatus 4587;
BA_ "SigType" SG_ 2365402622 Jystck5GripXAxisDetentPosStatus 4;
BA_ "SPN" SG_ 2365402622 Jystck5GripXAxisDetentPosStatus 4564;
BA_ "SigType" SG_ 2365402622 Jystck5GripYAxisDetentPosStatus 4;
BA_ "SPN" SG_ 2365402622 Jystck5GripYAxisDetentPosStatus 4563;
BA_ "SigType" SG_ 2365402622 Jystck5ThetaAxisDetentPosStatus 4;
BA_ "SPN" SG_ 2365402622 Jystck5ThetaAxisDetentPosStatus 4562;
BA_ "SigType" SG_ 2365402622 Joystick5ThetaAxisPos 1;
BA_ "SPN" SG_ 2365402622 Joystick5ThetaAxisPos 4561;
BA_ "SigType" SG_ 2365402622 Jystck5ThtAxsClckwsPstvPsStatus 4;
BA_ "SPN" SG_ 2365402622 Jystck5ThtAxsClckwsPstvPsStatus 4560;
BA_ "SigType" SG_ 2365402622 Jystck5ThtAxsCntrClckwsNgtvPsStt 4;
BA_ "SPN" SG_ 2365402622 Jystck5ThtAxsCntrClckwsNgtvPsStt 4559;
BA_ "SystemSignalLongSymbol" SG_ 2365402622 Jystck5ThtAxsCntrClckwsNgtvPsStt "Jystck5ThtAxsCntrClckwsNgtvPsStts";
BA_ "SigType" SG_ 2365402622 Jystck5ThtaAxisNeutralPosStatus 4;
BA_ "SPN" SG_ 2365402622 Jystck5ThtaAxisNeutralPosStatus 4558;
BA_ "SigType" SG_ 2365402622 Joystick5GripYAxisPos 1;
BA_ "SPN" SG_ 2365402622 Joystick5GripYAxisPos 4557;
BA_ "SigType" SG_ 2365402622 Jystck5GrpYAxsLvrFrwrdPstvPsStts 4;
BA_ "SPN" SG_ 2365402622 Jystck5GrpYAxsLvrFrwrdPstvPsStts 4556;
BA_ "SigType" SG_ 2365402622 Jystck5GrpYAxsLvrBckNgtvPsSttus 4;
BA_ "SPN" SG_ 2365402622 Jystck5GrpYAxsLvrBckNgtvPsSttus 4555;
BA_ "SigType" SG_ 2365402622 Jystck5GrpYAxisNeutralPosStatus 4;
BA_ "SPN" SG_ 2365402622 Jystck5GrpYAxisNeutralPosStatus 4554;
BA_ "SigType" SG_ 2365402622 Joystick5GripXAxisPos 1;
BA_ "SPN" SG_ 2365402622 Joystick5GripXAxisPos 4553;
BA_ "SigType" SG_ 2365402622 Jystck5GrpXAxsLvrRghtPstvPsStts 4;
BA_ "SPN" SG_ 2365402622 Jystck5GrpXAxsLvrRghtPstvPsStts 4552;
BA_ "SigType" SG_ 2365402622 Jystck5GrpXAxsLvrLftNgtvPsSttus 4;
BA_ "SPN" SG_ 2365402622 Jystck5GrpXAxsLvrLftNgtvPsSttus 4551;
BA_ "SigType" SG_ 2365402622 Jystck5GrpXAxisNeutralPosStatus 4;
BA_ "SPN" SG_ 2365402622 Jystck5GrpXAxisNeutralPosStatus 4550;
BA_ "SigType" SG_ 2365403134 Jystck4GripXAxisDetentPosStatus 4;
BA_ "SPN" SG_ 2365403134 Jystck4GripXAxisDetentPosStatus 4527;
BA_ "SigType" SG_ 2365403134 Jystck4GripYAxisDetentPosStatus 4;
BA_ "SPN" SG_ 2365403134 Jystck4GripYAxisDetentPosStatus 4526;
BA_ "SigType" SG_ 2365403134 Jystck4ThetaAxisDetentPosStatus 4;
BA_ "SPN" SG_ 2365403134 Jystck4ThetaAxisDetentPosStatus 4525;
BA_ "SigType" SG_ 2365403134 Joystick4ThetaAxisPos 1;
BA_ "SPN" SG_ 2365403134 Joystick4ThetaAxisPos 4524;
BA_ "SigType" SG_ 2365403134 Jystck4ThtAxsClckwsPstvPsStatus 4;
BA_ "SPN" SG_ 2365403134 Jystck4ThtAxsClckwsPstvPsStatus 4523;
BA_ "SigType" SG_ 2365403134 Jystck4ThtAxsCntrClckwsNgtvPsStt 4;
BA_ "SPN" SG_ 2365403134 Jystck4ThtAxsCntrClckwsNgtvPsStt 4522;
BA_ "SystemSignalLongSymbol" SG_ 2365403134 Jystck4ThtAxsCntrClckwsNgtvPsStt "Jystck4ThtAxsCntrClckwsNgtvPsStts";
BA_ "SigType" SG_ 2365403134 Jystck4ThtaAxisNeutralPosStatus 4;
BA_ "SPN" SG_ 2365403134 Jystck4ThtaAxisNeutralPosStatus 4521;
BA_ "SigType" SG_ 2365403134 Joystick4GripYAxisPos 1;
BA_ "SPN" SG_ 2365403134 Joystick4GripYAxisPos 4520;
BA_ "SigType" SG_ 2365403134 Jystck4GrpYAxsLvrFrwrdPstvPsStts 4;
BA_ "SPN" SG_ 2365403134 Jystck4GrpYAxsLvrFrwrdPstvPsStts 4519;
BA_ "SigType" SG_ 2365403134 Jystck4GrpYAxsLvrBckNgtvPsSttus 4;
BA_ "SPN" SG_ 2365403134 Jystck4GrpYAxsLvrBckNgtvPsSttus 4518;
BA_ "SigType" SG_ 2365403134 Jystck4GrpYAxisNeutralPosStatus 4;
BA_ "SPN" SG_ 2365403134 Jystck4GrpYAxisNeutralPosStatus 4517;
BA_ "SigType" SG_ 2365403134 Joystick4GripXAxisPos 1;
BA_ "SPN" SG_ 2365403134 Joystick4GripXAxisPos 4516;
BA_ "SigType" SG_ 2365403134 Jystck4GrpXAxsLvrRghtPstvPsStts 4;
BA_ "SPN" SG_ 2365403134 Jystck4GrpXAxsLvrRghtPstvPsStts 4515;
BA_ "SigType" SG_ 2365403134 Jystck4GrpXAxsLvrLftNgtvPsSttus 4;
BA_ "SPN" SG_ 2365403134 Jystck4GrpXAxsLvrLftNgtvPsSttus 4514;
BA_ "SigType" SG_ 2365403134 Jystck4GrpXAxisNeutralPosStatus 4;
BA_ "SPN" SG_ 2365403134 Jystck4GrpXAxisNeutralPosStatus 4513;
BA_ "SigType" SG_ 2365400062 Jystck10GrpXAxisDetentPosStatus 4;
BA_ "SPN" SG_ 2365400062 Jystck10GrpXAxisDetentPosStatus 4749;
BA_ "SigType" SG_ 2365400062 Jystck10GrpYAxisDetentPosStatus 4;
BA_ "SPN" SG_ 2365400062 Jystck10GrpYAxisDetentPosStatus 4748;
BA_ "SigType" SG_ 2365400062 Jystck10ThtaAxisDetentPosStatus 4;
BA_ "SPN" SG_ 2365400062 Jystck10ThtaAxisDetentPosStatus 4747;
BA_ "SigType" SG_ 2365400062 Joystick10ThetaAxisPos 1;
BA_ "SPN" SG_ 2365400062 Joystick10ThetaAxisPos 4746;
BA_ "SigType" SG_ 2365400062 Jystck10ThtAxsClckwsPstvPsSttus 4;
BA_ "SPN" SG_ 2365400062 Jystck10ThtAxsClckwsPstvPsSttus 4745;
BA_ "SigType" SG_ 2365400062 Jystck10ThtAxsCntrClckwsNgtvPsSt 4;
BA_ "SPN" SG_ 2365400062 Jystck10ThtAxsCntrClckwsNgtvPsSt 4744;
BA_ "SystemSignalLongSymbol" SG_ 2365400062 Jystck10ThtAxsCntrClckwsNgtvPsSt "Jystck10ThtAxsCntrClckwsNgtvPsStts";
BA_ "SigType" SG_ 2365400062 Jystck10ThtAxisNeutralPosStatus 4;
BA_ "SPN" SG_ 2365400062 Jystck10ThtAxisNeutralPosStatus 4743;
BA_ "SigType" SG_ 2365400062 Joystick10GripYAxisPos 1;
BA_ "SPN" SG_ 2365400062 Joystick10GripYAxisPos 4742;
BA_ "SigType" SG_ 2365400062 Jystck10GrpYAxsLvrFrwrdPstvPsStt 4;
BA_ "SPN" SG_ 2365400062 Jystck10GrpYAxsLvrFrwrdPstvPsStt 4741;
BA_ "SystemSignalLongSymbol" SG_ 2365400062 Jystck10GrpYAxsLvrFrwrdPstvPsStt "Jystck10GrpYAxsLvrFrwrdPstvPsStts";
BA_ "SigType" SG_ 2365400062 Jystck10GrpYAxsLvrBckNgtvPsStts 4;
BA_ "SPN" SG_ 2365400062 Jystck10GrpYAxsLvrBckNgtvPsStts 4740;
BA_ "SigType" SG_ 2365400062 Jystck10GrpYAxsNeutralPosStatus 4;
BA_ "SPN" SG_ 2365400062 Jystck10GrpYAxsNeutralPosStatus 4739;
BA_ "SigType" SG_ 2365400062 Joystick10GripXAxisPos 1;
BA_ "SPN" SG_ 2365400062 Joystick10GripXAxisPos 4738;
BA_ "SigType" SG_ 2365400062 Jystck10GrpXAxsLvrRghtPstvPsStts 4;
BA_ "SPN" SG_ 2365400062 Jystck10GrpXAxsLvrRghtPstvPsStts 4737;
BA_ "SigType" SG_ 2365400062 Jystck10GrpXAxsLvrLftNgtvPsStts 4;
BA_ "SPN" SG_ 2365400062 Jystck10GrpXAxsLvrLftNgtvPsStts 4736;
BA_ "SigType" SG_ 2365400062 Jystck10GrpXAxsNeutralPosStatus 4;
BA_ "SPN" SG_ 2365400062 Jystck10GrpXAxsNeutralPosStatus 4735;
BA_ "SigType" SG_ 2566713598 EngFuelFilterIntakeAbsPress 1;
BA_ "SPN" SG_ 2566713598 EngFuelFilterIntakeAbsPress 5417;
BA_ "SigType" SG_ 2499604478 EngExhstGsRcrcltn1IntkeAbsPress 1;
BA_ "SPN" SG_ 2499604478 EngExhstGsRcrcltn1IntkeAbsPress 5430;
BA_ "SigType" SG_ 2499608830 EngExhstGsRcrcltn2IntkeAbsPress 1;
BA_ "SPN" SG_ 2499608830 EngExhstGsRcrcltn2IntkeAbsPress 5429;
BA_ "SigType" SG_ 2499608830 EngExhstGsRcrcltn2OtletAbsPress 1;
BA_ "SPN" SG_ 2499608830 EngExhstGsRcrcltn2OtletAbsPress 5254;
BA_ "SigType" SG_ 2499608830 EngExhstGsRcrcltion2IntakePress 1;
BA_ "SPN" SG_ 2499608830 EngExhstGsRcrcltion2IntakePress 5253;
BA_ "SigType" SG_ 2499608830 EngExhstGsRcrculation2DiffPress 1;
BA_ "SPN" SG_ 2499608830 EngExhstGsRcrculation2DiffPress 5252;
VAL_ 3221225472 TirePressThresholdDetection 7 "NotAvailable" 6 "ErrorIndicator" 5 "NotDefined" 4 "ExtrmUndrPrssTrPrssrIsAtALvlWhr" 3 "UndrPrssTrPrssrIsLwrThnThPrssrD" 2 "NWrnngPrssTrPrssrIsWthnThThrshl" 1 "OvrPrssTrPrssrIsHghrThnThPrssrD" 0 "ExtrmOvrPrssTrPrssrIsAtALvlWhrT" ;
VAL_ 3221225472 CTIWheelEndElectricalFault 3 "NotSupported" 2 "Error" 1 "NotDefined" 0 "Ok" ;
VAL_ 3221225472 CTITireStatus 3 "NotSupported" 2 "Error" 1 "TireLeakDetected" 0 "Ok" ;
VAL_ 3221225472 CTIWheelSensorStatus 3 "NotSupported" 2 "NotDefined" 1 "On" 0 "Off_IsolatedFromCTIPressCtrl" ;
VAL_ 3221225472 EngTorqueMode 15 "Not available" 11 "Remote accelerator" 10 "Braking system" 9 "High speed governor" 8 "Torque limiting" 7 "ABS control" 6 "Transmission control" 5 "ASR control" 4 "Road speed governor" 3 "PTO governor" 2 "Cruise control" 1 "Accelerator pedal/operator selec" 0 "Low idle governor/no request (de" ;
VAL_ 3221225472 ActlEngPrcntTrqueHighResolution 8 "1111NotAvailable" 7 "0875" 1 "0125" 0 "0000" ;
VAL_ 3221225472 EngStarterMode 15 "notAvailable" 14 "error" 12 "starterInhibitedReasonUnknown" 9 "1011Reserved" 8 "strtrInhbtdDueToStarterOvertemp" 7 "strtrInhbtdDToActiveImmobilizer" 6 "strtrInhbtdDTDrvlnEnggdOthrTrns" 5 "strtrInhbtdDTEngNtReadyForStart" 4 "strtrInhbtdDToEngAlreadyRunning" 3 "strtFnshdStrtrNtActvAftrHvngBnA" 2 "starterActiveGearEngaged" 1 "starterActiveGearNotEngaged" 0 "startNotRqed" ;
VAL_ 3221225472 MessageCounter 14 "Reserved" 13 "Reserved" 12 "Reserved" 11 "Reserved" 10 "Reserved" 9 "Reserved" 8 "Reserved" 15 "Not Available" ;
VAL_ 3221225472 ControlPurpose 5 "TemporaryPowerTrainControl" 4 "EngineProtection" 3 "RoadSpeedGovernor" 2 "PTOGovernor" 1 "CruiseControl" 0 "AcceleratorPedal" ;
VAL_ 3221225472 TransmissionRate 7 "UseStandardRate" 6 "25ms" 5 "50ms" 4 "100ms" 3 "250ms" 2 "500ms" 1 "750ms" 0 "1000ms" ;
VAL_ 3221225472 OverrideCtrlModePriority 3 "LowPriority" 2 "MdmPrrtyUsdFrPwrtrnCtrlOprtnsWh" 1 "HighPriority" 0 "HghstPrrtyUsdFrSttnsThtRqrImmdt" ;
VAL_ 3221225472 EngRqedSpeedCtrlConditions 2 "ThsCtrlCndtnHsBnOptmzdTMnmzRpmO" 3 "StbltyOptmzdFrDrvlnEnggdAnd_OrI" 1 "StbltyOptmzdFrDrvlnDsnggdAndNnl" 0 "ThsSpdGvrnrGnSlctnIsAdjstdTPrvd" ;
VAL_ 3221225472 EngOverrideCtrlMode 3 "Spd_TrqLmtCtrlLmtSpdAnd_OrTrqBs" 2 "TrqCtrlCntrlTrqTInclddDsrdTrqVl" 1 "SpdCtrlGvrnSpdTInclddDsrdSpdVle" 0 "OvrrdDsbldDsblAnyExstngCtrlCmdd" ;
VAL_ 3221225472 MessageChecksum 15 "Not Available" ;
VAL_ 3221225472 EngineRequestedTorqueHiRes 15 "Not Available" 14 "Not Available" 13 "Not Available" 12 "Not Available" 11 "Not Available" 10 "Not Available" 9 "Not Available" 8 "Not Available" ;
VAL_ 3221225472 TransCurrentGear 251 "Park" ;
VAL_ 3221225472 TransSelectedGear 251 "Park" ;
VAL_ 3221225472 TrnsTrqueConverterLockupEngaged 3 "NotAvailable" 2 "Error" 1 "TorqueConverterLockupEngaged" 0 "TorqueConverterLockupDisengaged" ;
VAL_ 3221225472 TrnsTrqCnvrtrLckpTrnstnInPrcess 3 "NotAvailable" 2 "Error" 1 "TransitionIsInProcess" 0 "TransitionIsNotInProcess" ;
VAL_ 3221225472 MomentaryEngMaxPowerEnable 3 "notAvailable" 2 "fault" 1 "mmntarilyRqingMaxPowerAvailable" 0 "notRqingMaxPowerAvailable" ;
VAL_ 3221225472 ProgressiveShiftDisable 2 "Reserved" 3 "TakeNoAction" 1 "ProgressiveShiftIsDisabled" 0 "ProgressiveShiftIsNotDisabled" ;
VAL_ 3221225472 EngMomentaryOverspeedEnable 3 "TakeNoAction" 2 "Reserved" 1 "MomentaryEngOverspeedIsEnabled" 0 "MomentaryEngOverspeedIsDisabled" ;
VAL_ 3221225472 TransShiftInProcess 3 "NotAvailable" 2 "Error" 1 "ShiftInProcess" 0 "ShiftIsNotInProcess" ;
VAL_ 3221225472 TransDrivelineEngaged 3 "NotAvailable" 2 "Error" 1 "DrivelineEngaged" 0 "DrivelineDisengaged" ;
VAL_ 2348810247 MessageCounter 14 "Reserved" 13 "Reserved" 12 "Reserved" 11 "Reserved" 10 "Reserved" 9 "Reserved" 8 "Reserved" 15 "Not Available" ;
VAL_ 2348810247 ControlPurpose 5 "TemporaryPowerTrainControl" 4 "EngineProtection" 3 "RoadSpeedGovernor" 2 "PTOGovernor" 1 "CruiseControl" 0 "AcceleratorPedal" ;
VAL_ 2348810247 TransmissionRate 7 "UseStandardRate" 6 "25ms" 5 "50ms" 4 "100ms" 3 "250ms" 2 "500ms" 1 "750ms" 0 "1000ms" ;
VAL_ 2348810247 OverrideCtrlModePriority 3 "LowPriority" 2 "MdmPrrtyUsdFrPwrtrnCtrlOprtnsWh" 1 "HighPriority" 0 "HghstPrrtyUsdFrSttnsThtRqrImmdt" ;
VAL_ 2348810247 EngRqedSpeedCtrlConditions 2 "ThsCtrlCndtnHsBnOptmzdTMnmzRpmO" 3 "StbltyOptmzdFrDrvlnEnggdAnd_OrI" 1 "StbltyOptmzdFrDrvlnDsnggdAndNnl" 0 "ThsSpdGvrnrGnSlctnIsAdjstdTPrvd" ;
VAL_ 2348810247 EngOverrideCtrlMode 3 "Spd_TrqLmtCtrlLmtSpdAnd_OrTrqBs" 2 "TrqCtrlCntrlTrqTInclddDsrdTrqVl" 1 "SpdCtrlGvrnSpdTInclddDsrdSpdVle" 0 "OvrrdDsbldDsblAnyExstngCtrlCmdd" ;
VAL_ 2348810247 MessageChecksum 15 "Not Available" ;
VAL_ 2348810247 EngineRequestedTorqueHiRes 15 "Not Available" 14 "Not Available" 13 "Not Available" 12 "Not Available" 11 "Not Available" 10 "Not Available" 9 "Not Available" 8 "Not Available" ;
VAL_ 2348814083 MessageCounter 14 "Reserved" 13 "Reserved" 12 "Reserved" 11 "Reserved" 10 "Reserved" 9 "Reserved" 8 "Reserved" 15 "Not Available" ;
VAL_ 2348814083 ControlPurpose 5 "TemporaryPowerTrainControl" 4 "EngineProtection" 3 "RoadSpeedGovernor" 2 "PTOGovernor" 1 "CruiseControl" 0 "AcceleratorPedal" ;
VAL_ 2348814083 TransmissionRate 7 "UseStandardRate" 6 "25ms" 5 "50ms" 4 "100ms" 3 "250ms" 2 "500ms" 1 "750ms" 0 "1000ms" ;
VAL_ 2348814083 OverrideCtrlModePriority 3 "LowPriority" 2 "MdmPrrtyUsdFrPwrtrnCtrlOprtnsWh" 1 "HighPriority" 0 "HghstPrrtyUsdFrSttnsThtRqrImmdt" ;
VAL_ 2348814083 EngRqedSpeedCtrlConditions 2 "ThsCtrlCndtnHsBnOptmzdTMnmzRpmO" 3 "StbltyOptmzdFrDrvlnEnggdAnd_OrI" 1 "StbltyOptmzdFrDrvlnDsnggdAndNnl" 0 "ThsSpdGvrnrGnSlctnIsAdjstdTPrvd" ;
VAL_ 2348814083 EngOverrideCtrlMode 3 "Spd_TrqLmtCtrlLmtSpdAnd_OrTrqBs" 2 "TrqCtrlCntrlTrqTInclddDsrdTrqVl" 1 "SpdCtrlGvrnSpdTInclddDsrdSpdVle" 0 "OvrrdDsbldDsblAnyExstngCtrlCmdd" ;
VAL_ 2348814083 MessageChecksum 15 "Not Available" ;
VAL_ 2348814083 EngineRequestedTorqueHiRes 15 "Not Available" 14 "Not Available" 13 "Not Available" 12 "Not Available" 11 "Not Available" 10 "Not Available" 9 "Not Available" 8 "Not Available" ;
VAL_ 2565866755 TransCurrentGear 251 "Park" ;
VAL_ 2565866755 TransSelectedGear 251 "Park" ;
VAL_ 2364539395 TrnsTrqueConverterLockupEngaged 3 "NotAvailable" 2 "Error" 1 "TorqueConverterLockupEngaged" 0 "TorqueConverterLockupDisengaged" ;
VAL_ 2364539395 TrnsTrqCnvrtrLckpTrnstnInPrcess 3 "NotAvailable" 2 "Error" 1 "TransitionIsInProcess" 0 "TransitionIsNotInProcess" ;
VAL_ 2364539395 MomentaryEngMaxPowerEnable 3 "notAvailable" 2 "fault" 1 "mmntarilyRqingMaxPowerAvailable" 0 "notRqingMaxPowerAvailable" ;
VAL_ 2364539395 ProgressiveShiftDisable 2 "Reserved" 3 "TakeNoAction" 1 "ProgressiveShiftIsDisabled" 0 "ProgressiveShiftIsNotDisabled" ;
VAL_ 2364539395 EngMomentaryOverspeedEnable 3 "TakeNoAction" 2 "Reserved" 1 "MomentaryEngOverspeedIsEnabled" 0 "MomentaryEngOverspeedIsDisabled" ;
VAL_ 2364539395 TransShiftInProcess 3 "NotAvailable" 2 "Error" 1 "ShiftInProcess" 0 "ShiftIsNotInProcess" ;
VAL_ 2364539395 TransDrivelineEngaged 3 "NotAvailable" 2 "Error" 1 "DrivelineEngaged" 0 "DrivelineDisengaged" ;
VAL_ 2348810243 MessageCounter 14 "Reserved" 13 "Reserved" 12 "Reserved" 11 "Reserved" 10 "Reserved" 9 "Reserved" 8 "Reserved" 15 "Not Available" ;
VAL_ 2348810243 ControlPurpose 5 "TemporaryPowerTrainControl" 4 "EngineProtection" 3 "RoadSpeedGovernor" 2 "PTOGovernor" 1 "CruiseControl" 0 "AcceleratorPedal" ;
VAL_ 2348810243 TransmissionRate 7 "UseStandardRate" 6 "25ms" 5 "50ms" 4 "100ms" 3 "250ms" 2 "500ms" 1 "750ms" 0 "1000ms" ;
VAL_ 2348810243 OverrideCtrlModePriority 3 "LowPriority" 2 "MdmPrrtyUsdFrPwrtrnCtrlOprtnsWh" 1 "HighPriority" 0 "HghstPrrtyUsdFrSttnsThtRqrImmdt" ;
VAL_ 2348810243 EngRqedSpeedCtrlConditions 2 "ThsCtrlCndtnHsBnOptmzdTMnmzRpmO" 3 "StbltyOptmzdFrDrvlnEnggdAnd_OrI" 1 "StbltyOptmzdFrDrvlnDsnggdAndNnl" 0 "ThsSpdGvrnrGnSlctnIsAdjstdTPrvd" ;
VAL_ 2348810243 EngOverrideCtrlMode 3 "Spd_TrqLmtCtrlLmtSpdAnd_OrTrqBs" 2 "TrqCtrlCntrlTrqTInclddDsrdTrqVl" 1 "SpdCtrlGvrnSpdTInclddDsrdSpdVle" 0 "OvrrdDsbldDsblAnyExstngCtrlCmdd" ;
VAL_ 2348810243 MessageChecksum 15 "Not Available" ;
VAL_ 2348810243 EngineRequestedTorqueHiRes 15 "Not Available" 14 "Not Available" 13 "Not Available" 12 "Not Available" 11 "Not Available" 10 "Not Available" 9 "Not Available" 8 "Not Available" ;
VAL_ 2297441790 SpprtVrblTrnsRpttnRtFrAcclrtnSns 1 "MsTransRate" ;
VAL_ 2297441790 VrtclAcclrtnExRngeFigureOfMerit 3 "NotAvailable" 2 "Error" 1 "VrtclcclrtnIsDgrddDtIsSspctDTEn" 0 "VrtclAcclrtnIsFllyFnctnlDtIsWth" ;
VAL_ 2297441790 LngtdnlAcclrtnExRngFgureOfMerit 3 "NotAvailable" 2 "Error" 1 "LngtdnlAcclrtnIsDgrddDtIsSspctD" 0 "LngtdnlAcclrtnIsFllyFnctnlDtIsW" ;
VAL_ 2297441790 LtrlAcclrtnExRangeFigureOfMerit 3 "NotAvailable" 2 "Error" 1 "LtrlAcclrtnIsDgrddDtIsSspctDTEn" 0 "LtrlAcclrtnIsFllyFnctnlDtIsWthn" ;
VAL_ 2364549630 RollAngleExRangeFigureOfMerit 3 "NotAvailable" 2 "Error" 1 "RllRtDgrddDtIsSspctDTEnvrnmntlC" 0 "RllRtFllyFnctnlDtIsWthnSnsrSpcf" ;
VAL_ 2364549630 RollAngleExRangeCompensation 3 "NotAvailable" 2 "Error" 1 "Off" 0 "On" ;
VAL_ 2364549630 PitchAngleExRangeFigureOfMerit 3 "NotAvailable" 2 "Error" 1 "PtchRtDgrddDtIsSspctDTEnvrnmntl" 0 "PtchRtFllyFnctnlDtIsWthnSnsrSpc" ;
VAL_ 2364549630 PitchAngleExRangeCompensation 3 "NotAvailable" 2 "Error" 1 "Off" 0 "On" ;
VAL_ 2499614462 OccpntClssfcationSystem10Status 3 "NotAvailable" 2 "ErrrClssfctonCannotBeDetermined" 1 "Occupied" 0 "Empty" ;
VAL_ 2499614462 OccpntClssficationSystem9Status 3 "NotAvailable" 2 "ErrrClssfctonCannotBeDetermined" 1 "Occupied" 0 "Empty" ;
VAL_ 2499614462 OccpntClssficationSystem8Status 3 "NotAvailable" 2 "ErrrClssfctonCannotBeDetermined" 1 "Occupied" 0 "Empty" ;
VAL_ 2499614462 OccpntClssficationSystem7Status 3 "NotAvailable" 2 "ErrrClssfctonCannotBeDetermined" 1 "Occupied" 0 "Empty" ;
VAL_ 2499614462 OccpntClssficationSystem6Status 3 "NotAvailable" 2 "ErrrClssfctonCannotBeDetermined" 1 "Occupied" 0 "Empty" ;
VAL_ 2499614462 OccpntClssficationSystem5Status 3 "NotAvailable" 2 "ErrrClssfctonCannotBeDetermined" 1 "Occupied" 0 "Empty" ;
VAL_ 2499614462 OccpntClssficationSystem4Status 3 "NotAvailable" 2 "ErrrClssfctonCannotBeDetermined" 1 "Occupied" 0 "Empty" ;
VAL_ 2499614462 OccpntClssficationSystem3Status 3 "NotAvailable" 2 "ErrrClssfctonCannotBeDetermined" 1 "Occupied" 0 "Empty" ;
VAL_ 2499614462 PssngrOccpntClssfctnSystmStatus 7 "NotAvailable" 5 "ErrrClssfctnOfOccpntCnntBDtrmnd" 3 "Adult" 4 "LargeAdult" 2 "SmallAdult" 1 "Child" 0 "Empty" ;
VAL_ 2499614462 DrvrOccpntClssfctonSystemStatus 7 "NotAvailable" 6 "ErrrClssfctnOfOccpntCnntBDtrmnd" 5 "Reserved" 4 "LargeAdult" 3 "Adult" 2 "SmallAdult" 1 "Child" 0 "Empty" ;
VAL_ 2560098046 CabNoiseCtrlTuningStatus 15 "NotAvailable_NotTuning_NotRqed" 14 "TuningModeError" 10 "AutomaticTuningModeSavingData" 9 "AutomaticTuningModeCmdComplete" 8 "AutomaticTuningMode" 7 "MnlTnngDndRqrsScrtyVerification" 13 "Reserved" 2 "ManualTuningModeSavingData" 1 "ManualTuningModeCmdComplete" 0 "ManualTuningMode" ;
VAL_ 2560098046 CabNoiseCtrlStatus 3 "NotAvailable_NotRqed" 2 "ErrorIndicator" 1 "CabNoiseCtrlSystemOFFLine" 0 "CabNoiseCtrlSystemONLine" ;
VAL_ 2560163582 CabNoiseCtrlTuningState 7 "DontCareNOTCmded" 6 "Reserved" 5 "ExitTuningSavingParameters" 4 "ExitTuningNotSavingParameters" 3 "RmnInTningSaveCurrentParameters" 2 "ActvtAtmtcTnngSttSvngPrmtrsExtO" 1 "ActvtAtmtcTnngWtFrSvAndExitCmds" 0 "ActvtMnlTnngWtFrSaveAndExitCmds" ;
VAL_ 2560163582 CabNoiseCtrlState 3 "DontCare_NotCmded" 2 "Reserved" 1 "BringCabNoiseCtrlSystemOnLine" 0 "TakeCabNoiseCtrlSystemOffLine" ;
VAL_ 2297441534 DropRelayCtrl 3 "TakeNoAction" 2 "Reserved" 1 "OnEnableDropRelayRq" 0 "OffDisableDropRelayRq" ;
VAL_ 2297441534 LiftRelayCtrl 3 "TakeNoAction" 2 "Reserved" 1 "OnEnableLiftRelayRq" 0 "OffDisableLiftRelayRq" ;
VAL_ 2297441534 MaterialDropActiveStatus 3 "NotAvailable" 2 "Error" 1 "On" 0 "Off" ;
VAL_ 2297441534 MaterialLiftActiveStatus 3 "NotAvailable" 2 "Error" 1 "On" 0 "Off" ;
VAL_ 2297441534 GnratorCurrentBoostActiveStatus 3 "NotAvailable" 2 "Error" 1 "On" 0 "Off" ;
VAL_ 2297441534 MaterialDropSwitch 3 "NotAvailable" 2 "Error" 1 "Drop" 0 "DontDrop" ;
VAL_ 2297441534 MaterialLiftSwitch 3 "NotAvailable" 2 "Error" 1 "Lift" 0 "DontLift" ;
VAL_ 2566722302 GneratorDutyCycleExceededStatus 3 "NotAvaiable" 2 "Error" 1 "DutyCycleExceed" 0 "DutyCycleNotExceed" ;
VAL_ 2566722302 VoltageMonitorActiveStatus 3 "NotAvailable" 2 "Error" 1 "MonitorIsOn" 0 "MonitorIsOff" ;
VAL_ 2566722302 GensetEnableActiveStatus 3 "NotAvaialble" 2 "Error" 1 "Enabled" 0 "NotEnabled" ;
VAL_ 2566722302 ReverseCurrentRangeSetting 31 "NotAvailable" 30 "Error" 16 "11101NotUsed" 15 "16" 14 "15" 13 "14" 12 "13" 11 "12" 10 "11" 9 "10" 8 "9" 7 "8" 6 "7" 5 "6" 4 "5" 3 "4" 2 "3" 1 "2" 0 "1" ;
VAL_ 2566722302 GensetSoftstartActiveStatus 3 "NotAvailable" 2 "Error" 1 "On" 0 "Off" ;
VAL_ 2566722302 Grapple_MagnetSelectionSwitch 3 "NotAvailable" 2 "Error" 1 "MagnetSelected" 0 "GrappleSelected" ;
VAL_ 2566722302 GnstSystmOtptVoltageRangeStatus 3 "NotAvailable" 2 "Error" 1 "InRange" 0 "OutOfRange" ;
VAL_ 2566722302 GeneratorOverheatStatus 3 "NotAvailable" 2 "Error" 1 "Overheat" 0 "NotOverheat" ;
VAL_ 2560032510 LwVltgDscnnctDsredOperatingMode 15 "NoChange" 6 "1110Reserved" 5 "ManualConnect" 4 "ManualDisconnect" 1 "0011Reserved" 0 "Automatic" ;
VAL_ 2566717950 LwVltgDisconnectVoutOutputState 15 "NotAvailableNotInstalled" 14 "OutputFault" 5 "1101Reserved" 4 "ConnectPendingAlarmActive" 3 "DisconnectPendingAlarmActive" 2 "DscnnctAlrmExprdOtptOffDscnnctd" 1 "OutputOnConnected" 0 "OutputOffDisconnected" ;
VAL_ 2566717950 LwVoltageDisconnectOutput1State 15 "NotAvailableNotInstalled" 14 "OutputFault" 5 "1101Reserved" 4 "ConnectPendingAlarmActive" 3 "DisconnectPendingAlarmActive" 2 "DscnnctAlrmExprdOtptOffDscnnctd" 1 "OutputOnConnected" 0 "OutputOffDisconnected" ;
VAL_ 2566717950 LwVoltageDisconnectOutput2State 15 "NotAvailableNotInstalled" 14 "OutputFault" 5 "1101Reserved" 4 "ConnectPendingAlarmActive" 3 "DisconnectPendingAlarmActive" 2 "DscnnctAlrmExprdOtptOffDscnnctd" 1 "OutputOnConnected" 0 "OutputOffDisconnected" ;
VAL_ 2566717950 LwVoltageDisconnectOutput3State 15 "NotAvailableNotInstalled" 14 "OutputFault" 5 "1101Reserved" 4 "ConnectPendingAlarmActive" 3 "DisconnectPendingAlarmActive" 2 "DscnnctAlrmExprdOtptOffDscnnctd" 1 "OutputOnConnected" 0 "OutputOffDisconnected" ;
VAL_ 2566717950 LwVltgDscnnctCrrntOperatingMode 15 "NotAvailable" 10 "1110Reserved" 9 "ManualConnectViaHardwiredInput" 8 "MnalDisconnectViaHardwiredInput" 6 "0111Reserved" 5 "ManualConnectViaJ1939Rq" 4 "ManualDisconnectViaJ1939Rq" 1 "0011Reserved" 0 "Automatic" ;
VAL_ 2566717950 LwVltgDscnnctManualConnectState 3 "NotInstalled" 2 "Error" 1 "InputOn" 0 "InputOff" ;
VAL_ 2566717950 LwVltgDscnnctMnlDisconnectState 3 "NotInstalled" 2 "Error" 1 "InputOn" 0 "InputOff" ;
VAL_ 2358902526 Joystick3Lamp10Cmd 3 "NotAvailableNotInstalled" 2 "Blinking" 1 "On" 0 "Off" ;
VAL_ 2358902526 Joystick3Lamp9Cmd 3 "NotAvailableNotInstalled" 2 "Blinking" 1 "On" 0 "Off" ;
VAL_ 2358902526 Joystick3Lamp8Cmd 3 "NotAvailableNotInstalled" 2 "Blinking" 1 "On" 0 "Off" ;
VAL_ 2358902526 Joystick3Lamp7Cmd 3 "NotAvailableNotInstalled" 2 "Blinking" 1 "On" 0 "Off" ;
VAL_ 2358902526 Joystick3Lamp6Cmd 3 "NotAvailableNotInstalled" 2 "Blinking" 1 "On" 0 "Off" ;
VAL_ 2358902526 Joystick3Lamp5Cmd 3 "NotAvailableNotInstalled" 2 "Blinking" 1 "On" 0 "Off" ;
VAL_ 2358902526 Joystick3Lamp4Cmd 3 "NotAvailableNotInstalled" 2 "Blinking" 1 "On" 0 "Off" ;
VAL_ 2358902526 Joystick3Lamp3Cmd 3 "NotAvailableNotInstalled" 2 "Blinking" 1 "On" 0 "Off" ;
VAL_ 2358902526 Joystick3Lamp2Cmd 3 "NotAvailableNotInstalled" 2 "Blinking" 1 "On" 0 "Off" ;
VAL_ 2358902526 Joystick3Lamp1Cmd 3 "NotAvailableNotInstalled" 2 "Blinking" 1 "On" 0 "Off" ;
VAL_ 2358902526 Joystick2Lamp10Cmd 3 "NotAvailableNotInstalled" 2 "Blinking" 1 "On" 0 "Off" ;
VAL_ 2358902526 Joystick2Lamp9Cmd 3 "NotAvailableNotInstalled" 2 "Blinking" 1 "On" 0 "Off" ;
VAL_ 2358902526 Joystick2Lamp8Cmd 3 "NotAvailableNotInstalled" 2 "Blinking" 1 "On" 0 "Off" ;
VAL_ 2358902526 Joystick2Lamp7Cmd 3 "NotAvailableNotInstalled" 2 "Blinking" 1 "On" 0 "Off" ;
VAL_ 2358902526 Joystick2Lamp6Cmd 3 "NotAvailableNotInstalled" 2 "Blinking" 1 "On" 0 "Off" ;
VAL_ 2358902526 Joystick2Lamp5Cmd 3 "NotAvailableNotInstalled" 2 "Blinking" 1 "On" 0 "Off" ;
VAL_ 2358902526 Joystick2Lamp4Cmd 3 "NotAvailableNotInstalled" 2 "Blinking" 1 "On" 0 "Off" ;
VAL_ 2358902526 Joystick2Lamp3Cmd 3 "NotAvailableNotInstalled" 2 "Blinking" 1 "On" 0 "Off" ;
VAL_ 2358902526 Joystick2Lamp2Cmd 3 "NotAvailableNotInstalled" 2 "Blinking" 1 "On" 0 "Off" ;
VAL_ 2358902526 Joystick2Lamp1Cmd 3 "NotAvailableNotInstalled" 2 "Blinking" 1 "On" 0 "Off" ;
VAL_ 2358902526 Joystick1Lamp10Cmd 3 "NotAvailableNotInstalled" 2 "Blinking" 1 "On" 0 "Off" ;
VAL_ 2358902526 Joystick1Lamp9Cmd 3 "NotAvailableNotInstalled" 2 "Blinking" 1 "On" 0 "Off" ;
VAL_ 2358902526 Joystick1Lamp8Cmd 3 "NotAvailableNotInstalled" 2 "Blinking" 1 "On" 0 "Off" ;
VAL_ 2358902526 Joystick1Lamp7Cmd 3 "NotAvailableNotInstalled" 2 "Blinking" 1 "On" 0 "Off" ;
VAL_ 2358902526 Joystick1Lamp6Cmd 3 "NotAvailableNotInstalled" 2 "Blinking" 1 "On" 0 "Off" ;
VAL_ 2358902526 Joystick1Lamp5Cmd 3 "NotAvailableNotInstalled" 2 "Blinking" 1 "On" 0 "Off" ;
VAL_ 2358902526 Joystick1Lamp4Cmd 3 "NotAvailableNotInstalled" 2 "Blinking" 1 "On" 0 "Off" ;
VAL_ 2358902526 Joystick1Lamp3Cmd 3 "NotAvailableNotInstalled" 2 "Blinking" 1 "On" 0 "Off" ;
VAL_ 2358902526 Joystick1Lamp2Cmd 3 "NotAvailableNotInstalled" 2 "Blinking" 1 "On" 0 "Off" ;
VAL_ 2358902526 Joystick1Lamp1Cmd 3 "NotAvailableNotInstalled" 2 "Blinking" 1 "On" 0 "Off" ;
VAL_ 2566711550 IntkVlvActtnSystmOlPrss2SlndCtrl 3 "notAvailable" 2 "reservedForSAEAssignment" 1 "on" 0 "off" ;
VAL_ 2566711550 IntkVlvActtnSystmOlPrss1SlndCtrl 3 "notAvailable" 2 "reservedForSAEAssignment" 1 "on" 0 "off" ;
VAL_ 2566713854 EngTrbWstgtActtr2OprationStatus 14 "Error" 6 "1101ReservedForFutureAssignment" 5 "UnCtrlledShutdownActive" 4 "CtrlledShutdownActive" 3 "DerateActive" 2 "AlarmHighSeverity" 1 "Alarm" 0 "Normal" ;
VAL_ 2566713854 EngTrbWstgtActtr1OprationStatus 14 "Error" 6 "1101ReservedForFutureAssignment" 5 "UnCtrlledShutdownActive" 4 "CtrlledShutdownActive" 3 "DerateActive" 2 "AlarmHighSeverity" 1 "Alarm" 0 "Normal" ;
VAL_ 2566713854 EngTrbWstgteActuator2TempStatus 7 "NotAvailable" 6 "Error" 5 "NotDefined" 4 "LowMostSevere" 3 "LowLeastSevere" 2 "InRange" 1 "HighLeastSevere" 0 "HighMostSevere" ;
VAL_ 2566714366 EngTrbCmprssrBypssActtr2OprtnStt 14 "Error" 6 "1101ReservedForFutureAssignment" 5 "UnCtrlledShutdownActive" 4 "CtrlledShutdownActive" 3 "DerateActive" 2 "AlarmHighSeverity" 1 "Alarm" 0 "Normal" ;
VAL_ 2566714366 EngTrbCmprssrBypssActtr1OprtnStt 14 "Error" 6 "1101ReservedForFutureAssignment" 5 "UnCtrlledShutdownActive" 4 "CtrlledShutdownActive" 3 "DerateActive" 2 "AlarmHighSeverity" 1 "Alarm" 0 "Normal" ;
VAL_ 2566714366 EngTrbCmprssrBypssActtr2TmpStts 7 "NotAvailable" 6 "Error" 5 "NotDefined" 4 "LowMostSevere" 3 "LowLeastSevere" 2 "InRange" 1 "HighLeastSevere" 0 "HighMostSevere" ;
VAL_ 2566714366 EngTrbCmprssrBypassActuator2Pos 4 "RprsntsBypssFllyOpnTypcllyCmprs" ;
VAL_ 2566714110 EngFuelValve2OperationStatus 14 "Error" 6 "1101ReservedForFutureAssignment" 5 "UnCtrlledShutdownActive" 4 "CtrlledShutdownActive" 3 "DerateActive" 2 "AlarmHighSeverity" 1 "Alarm" 0 "Normal" ;
VAL_ 2566714110 EngFuelValve1OperationStatus 14 "Error" 6 "1101ReservedForFutureAssignment" 5 "UnCtrlledShutdownActive" 4 "CtrlledShutdownActive" 3 "DerateActive" 2 "AlarmHighSeverity" 1 "Alarm" 0 "Normal" ;
VAL_ 2566714110 EngThrttleValve2OperationStatus 14 "Error" 6 "1101ReservedForFutureAssignment" 5 "UnCtrlledShutdownActive" 4 "CtrlledShutdownActive" 3 "DerateActive" 2 "AlarmHighSeverity" 1 "Alarm" 0 "Normal" ;
VAL_ 2566714110 EngThrttleValve1OperationStatus 15 "NotAvailable" 14 "Error" 6 "1101ReservedForFutureAssignment" 5 "UnCtrlledShutdownActive" 4 "CtrlledShutdownActive" 3 "DerateActive" 2 "AlarmHighSeverity" 1 "Alarm" 0 "Normal" ;
VAL_ 2566714110 EngFuelValve2TempStatus 7 "NotAvailable" 6 "Error" 5 "NotDefined" 4 "LowMostSevere" 3 "LowLeastSevere" 2 "InRange" 1 "HighLeastSevere" 0 "HighMostSevere" ;
VAL_ 2566714110 EngFuelValve1TempStatus 7 "NotAvailable" 6 "Error" 5 "NotDefined" 4 "LowMostSevere" 3 "LowLeastSevere" 2 "InRange" 1 "HighLeastSevere" 0 "HighMostSevere" ;
VAL_ 2566714110 EngThrottleValve2TempStatus 7 "NotAvailable" 6 "Error" 5 "NotDefined" 4 "LowMostSevere" 3 "LowLeastSevere" 2 "InRange" 1 "HighLeastSevere" 0 "HighMostSevere" ;
VAL_ 2566714110 EngThrottleValve1TempStatus 7 "NotAvailable" 6 "Error" 5 "NotDefined" 4 "LowMostSevere" 3 "LowLeastSevere" 2 "InRange" 1 "HighLeastSevere" 0 "HighMostSevere" ;
VAL_ 2499607550 EngExhstMnfldBnk1FlwBlncVlvActtr 4 "MeansMaxValveOpening" ;
VAL_ 2633825534 EngExhstMnfldBnk2FlwBlncVlv_0000 4 "MeansMaxValveOpening" ;
VAL_ 2365400574 Jystck9GripXAxisDetentPosStatus 3 "NotAvailable" 2 "ErrorIndicator" 1 "InDetentPos" 0 "NotInDetentPos" ;
VAL_ 2365400574 Jystck9GripYAxisDetentPosStatus 3 "NotAvailable" 2 "ErrorIndicator" 1 "InDetentPos" 0 "NotInDetentPos" ;
VAL_ 2365400574 Jystck9ThetaAxisDetentPosStatus 3 "NotAvailable" 2 "ErrorIndicator" 1 "InDetentPos" 0 "NotInDetentPos" ;
VAL_ 2365400574 Jystck9ThtAxsClckwsPstvPsStatus 3 "NotAvailable" 2 "ErrorIndicator" 1 "OnPositiveSideOfNeutral" 0 "NotOnPositiveSideOfNeutral" ;
VAL_ 2365400574 Jystck9ThtAxsCntrClckwsNgtvPsStt 3 "NotAvailable" 2 "ErrorIndicator" 1 "OnNegativeSideOfNeutral" 0 "NotOnNegativeSideOfNeutral" ;
VAL_ 2365400574 Jystck9ThtaAxisNeutralPosStatus 3 "NotAvailable" 2 "ErrorIndicator" 1 "InNeutralPos" 0 "NotInNeutralPos" ;
VAL_ 2365400574 Jystck9GrpYAxsLvrFrwrdPstvPsStts 3 "NotAvailable" 2 "ErrorIndicator" 1 "OnPositiveSideOfNeutral" 0 "NotOnPositiveSideOfNeutral" ;
VAL_ 2365400574 Jystck9GrpYAxsLvrBckNgtvPsSttus 3 "NotAvailable" 2 "ErrorIndicator" 1 "OnNegativeSideOfNeutral" 0 "NotOnNegativeSideOfNeutral" ;
VAL_ 2365400574 Jystck9GrpYAxisNeutralPosStatus 3 "NotAvailable" 2 "ErrorIndicator" 1 "InNeutralPos" 0 "NotInNeutralPos" ;
VAL_ 2365400574 Jystck9GrpXAxsLvrRghtPstvPsStts 3 "NotAvailable" 2 "ErrorIndicator" 1 "OnPositiveSideOfNeutral" 0 "NotOnPositiveSideOfNeutral" ;
VAL_ 2365400574 Jystck9GrpXAxsLvrLftNgtvPsSttus 3 "NotAvailable" 2 "ErrorIndicator" 1 "OnNegativeSideOfNeutral" 0 "NotOnNegativeSideOfNeutral" ;
VAL_ 2365400574 Jystck9GrpXAxisNeutralPosStatus 3 "NotAvailable" 2 "ErrorIndicator" 1 "InNeutralPos" 0 "NotInNeutralPos" ;
VAL_ 2365401086 Jystck8GripXAxisDetentPosStatus 3 "NotAvailable" 2 "ErrorIndicator" 1 "InDetentPos" 0 "NotInDetentPos" ;
VAL_ 2365401086 Jystck8GripYAxisDetentPosStatus 3 "NotAvailable" 2 "ErrorIndicator" 1 "InDetentPos" 0 "NotInDetentPos" ;
VAL_ 2365401086 Jystck8ThetaAxisDetentPosStatus 3 "NotAvailable" 2 "ErrorIndicator" 1 "InDetentPos" 0 "NotInDetentPos" ;
VAL_ 2365401086 Jystck8ThtAxsClckwsPstvPsStatus 3 "NotAvailable" 2 "ErrorIndicator" 1 "OnPositiveSideOfNeutral" 0 "NotOnPositiveSideOfNeutral" ;
VAL_ 2365401086 Jystck8ThtAxsCntrClckwsNgtvPsStt 3 "NotAvailable" 2 "ErrorIndicator" 1 "OnNegativeSideOfNeutral" 0 "NotOnNegativeSideOfNeutral" ;
VAL_ 2365401086 Jystck8ThtaAxisNeutralPosStatus 3 "NotAvailable" 2 "ErrorIndicator" 1 "InNeutralPos" 0 "NotInNeutralPos" ;
VAL_ 2365401086 Jystck8GrpYAxsLvrFrwrdPstvPsStts 3 "NotAvailable" 2 "ErrorIndicator" 1 "OnPositiveSideOfNeutral" 0 "NotOnPositiveSideOfNeutral" ;
VAL_ 2365401086 Jystck8GrpYAxsLvrBckNgtvPsSttus 3 "NotAvailable" 2 "ErrorIndicator" 1 "OnNegativeSideOfNeutral" 0 "NotOnNegativeSideOfNeutral" ;
VAL_ 2365401086 Jystck8GrpYAxisNeutralPosStatus 3 "NotAvailable" 2 "ErrorIndicator" 1 "InNeutralPos" 0 "NotInNeutralPos" ;
VAL_ 2365401086 Jystck8GrpXAxsLvrRghtPstvPsStts 3 "NotAvailable" 2 "ErrorIndicator" 1 "OnPositiveSideOfNeutral" 0 "NotOnPositiveSideOfNeutral" ;
VAL_ 2365401086 Jystck8GrpXAxsLvrLftNgtvPsSttus 3 "NotAvailable" 2 "ErrorIndicator" 1 "OnNegativeSideOfNeutral" 0 "NotOnNegativeSideOfNeutral" ;
VAL_ 2365401086 Jystck8GrpXAxisNeutralPosStatus 3 "NotAvailable" 2 "ErrorIndicator" 1 "InNeutralPos" 0 "NotInNeutralPos" ;
VAL_ 2365401598 Jystck7GripXAxisDetentPosStatus 3 "NotAvailable" 2 "ErrorIndicator" 1 "InDetentPos" 0 "NotInDetentPos" ;
VAL_ 2365401598 Jystck7GripYAxisDetentPosStatus 3 "NotAvailable" 2 "ErrorIndicator" 1 "InDetentPos" 0 "NotInDetentPos" ;
VAL_ 2365401598 Jystck7ThetaAxisDetentPosStatus 3 "NotAvailable" 2 "ErrorIndicator" 1 "InDetentPos" 0 "NotInDetentPos" ;
VAL_ 2365401598 Jystck7ThtAxsClckwsPstvPsStatus 3 "NotAvailable" 2 "ErrorIndicator" 1 "OnPositiveSideOfNeutral" 0 "NotOnPositiveSideOfNeutral" ;
VAL_ 2365401598 Jystck7ThtAxsCntrClckwsNgtvPsStt 3 "NotAvailable" 2 "ErrorIndicator" 1 "OnNegativeSideOfNeutral" 0 "NotOnNegativeSideOfNeutral" ;
VAL_ 2365401598 Jystck7ThtaAxisNeutralPosStatus 3 "NotAvailable" 2 "ErrorIndicator" 1 "InNeutralPos" 0 "NotInNeutralPos" ;
VAL_ 2365401598 Jystck7GrpYAxsLvrFrwrdPstvPsStts 3 "NotAvailable" 2 "ErrorIndicator" 1 "OnPositiveSideOfNeutral" 0 "NotOnPositiveSideOfNeutral" ;
VAL_ 2365401598 Jystck7GrpYAxsLvrBckNgtvPsSttus 3 "NotAvailable" 2 "ErrorIndicator" 1 "OnNegativeSideOfNeutral" 0 "NotOnNegativeSideOfNeutral" ;
VAL_ 2365401598 Jystck7GrpYAxisNeutralPosStatus 3 "NotAvailable" 2 "ErrorIndicator" 1 "InNeutralPos" 0 "NotInNeutralPos" ;
VAL_ 2365401598 Jystck7GrpXAxsLvrRghtPstvPsStts 3 "NotAvailable" 2 "ErrorIndicator" 1 "OnPositiveSideOfNeutral" 0 "NotOnPositiveSideOfNeutral" ;
VAL_ 2365401598 Jystck7GrpXAxsLvrLftNgtvPsSttus 3 "NotAvailable" 2 "ErrorIndicator" 1 "OnNegativeSideOfNeutral" 0 "NotOnNegativeSideOfNeutral" ;
VAL_ 2365401598 Jystck7GrpXAxisNeutralPosStatus 3 "NotAvailable" 2 "ErrorIndicator" 1 "InNeutralPos" 0 "NotInNeutralPos" ;
VAL_ 2365402110 Jystck6GripXAxisDetentPosStatus 3 "NotAvailable" 2 "ErrorIndicator" 1 "InDetentPos" 0 "NotInDetentPos" ;
VAL_ 2365402110 Jystck6GripYAxisDetentPosStatus 3 "NotAvailable" 2 "ErrorIndicator" 1 "InDetentPos" 0 "NotInDetentPos" ;
VAL_ 2365402110 Jystck6ThetaAxisDetentPosStatus 3 "NotAvailable" 2 "ErrorIndicator" 1 "InDetentPos" 0 "NotInDetentPos" ;
VAL_ 2365402110 Jystck6ThtAxsClckwsPstvPsStatus 3 "NotAvailable" 2 "ErrorIndicator" 1 "OnPositiveSideOfNeutral" 0 "NotOnPositiveSideOfNeutral" ;
VAL_ 2365402110 Jystck6ThtAxsCntrClckwsNgtvPsStt 3 "NotAvailable" 2 "ErrorIndicator" 1 "OnNegativeSideOfNeutral" 0 "NotOnNegativeSideOfNeutral" ;
VAL_ 2365402110 Jystck6ThtaAxisNeutralPosStatus 3 "NotAvailable" 2 "ErrorIndicator" 1 "InNeutralPos" 0 "NotInNeutralPos" ;
VAL_ 2365402110 Jystck6GrpYAxsLvrFrwrdPstvPsStts 3 "NotAvailable" 2 "ErrorIndicator" 1 "OnPositiveSideOfNeutral" 0 "NotOnPositiveSideOfNeutral" ;
VAL_ 2365402110 Jystck6GrpYAxsLvrBckNgtvPsSttus 3 "NotAvailable" 2 "ErrorIndicator" 1 "OnNegativeSideOfNeutral" 0 "NotOnNegativeSideOfNeutral" ;
VAL_ 2365402110 Jystck6GrpYAxisNeutralPosStatus 3 "NotAvailable" 2 "ErrorIndicator" 1 "InNeutralPos" 0 "NotInNeutralPos" ;
VAL_ 2365402110 Jystck6GrpXAxsLvrRghtPstvPsStts 3 "NotAvailable" 2 "ErrorIndicator" 1 "OnPositiveSideOfNeutral" 0 "NotOnPositiveSideOfNeutral" ;
VAL_ 2365402110 Jystck6GrpXAxsLvrLftNgtvPsSttus 3 "NotAvailable" 2 "ErrorIndicator" 1 "OnNegativeSideOfNeutral" 0 "NotOnNegativeSideOfNeutral" ;
VAL_ 2365402110 Jystck6GrpXAxisNeutralPosStatus 3 "NotAvailable" 2 "ErrorIndicator" 1 "InNeutralPos" 0 "NotInNeutralPos" ;
VAL_ 2365402622 Jystck5GripXAxisDetentPosStatus 3 "NotAvailable" 2 "ErrorIndicator" 1 "InDetentPos" 0 "NotInDetentPos" ;
VAL_ 2365402622 Jystck5GripYAxisDetentPosStatus 3 "NotAvailable" 2 "ErrorIndicator" 1 "InDetentPos" 0 "NotInDetentPos" ;
VAL_ 2365402622 Jystck5ThetaAxisDetentPosStatus 3 "NotAvailable" 2 "ErrorIndicator" 1 "InDetentPos" 0 "NotInDetentPos" ;
VAL_ 2365402622 Jystck5ThtAxsClckwsPstvPsStatus 3 "NotAvailable" 2 "ErrorIndicator" 1 "OnPositiveSideOfNeutral" 0 "NotOnPositiveSideOfNeutral" ;
VAL_ 2365402622 Jystck5ThtAxsCntrClckwsNgtvPsStt 3 "NotAvailable" 2 "ErrorIndicator" 1 "OnNegativeSideOfNeutral" 0 "NotOnNegativeSideOfNeutral" ;
VAL_ 2365402622 Jystck5ThtaAxisNeutralPosStatus 3 "NotAvailable" 2 "ErrorIndicator" 1 "InNeutralPos" 0 "NotInNeutralPos" ;
VAL_ 2365402622 Jystck5GrpYAxsLvrFrwrdPstvPsStts 3 "NotAvailable" 2 "ErrorIndicator" 1 "OnPositiveSideOfNeutral" 0 "NotOnPositiveSideOfNeutral" ;
VAL_ 2365402622 Jystck5GrpYAxsLvrBckNgtvPsSttus 3 "NotAvailable" 2 "ErrorIndicator" 1 "OnNegativeSideOfNeutral" 0 "NotOnNegativeSideOfNeutral" ;
VAL_ 2365402622 Jystck5GrpYAxisNeutralPosStatus 3 "NotAvailable" 2 "ErrorIndicator" 1 "InNeutralPos" 0 "NotInNeutralPos" ;
VAL_ 2365402622 Jystck5GrpXAxsLvrRghtPstvPsStts 3 "NotAvailable" 2 "ErrorIndicator" 1 "OnPositiveSideOfNeutral" 0 "NotOnPositiveSideOfNeutral" ;
VAL_ 2365402622 Jystck5GrpXAxsLvrLftNgtvPsSttus 3 "NotAvailable" 2 "ErrorIndicator" 1 "OnNegativeSideOfNeutral" 0 "NotOnNegativeSideOfNeutral" ;
VAL_ 2365402622 Jystck5GrpXAxisNeutralPosStatus 3 "NotAvailable" 2 "ErrorIndicator" 1 "InNeutralPos" 0 "NotInNeutralPos" ;
VAL_ 2365403134 Jystck4GripXAxisDetentPosStatus 3 "NotAvailable" 2 "ErrorIndicator" 1 "InDetentPos" 0 "NotInDetentPos" ;
VAL_ 2365403134 Jystck4GripYAxisDetentPosStatus 3 "NotAvailable" 2 "ErrorIndicator" 1 "InDetentPos" 0 "NotInDetentPos" ;
VAL_ 2365403134 Jystck4ThetaAxisDetentPosStatus 3 "NotAvailable" 2 "ErrorIndicator" 1 "InDetentPos" 0 "NotInDetentPos" ;
VAL_ 2365403134 Jystck4ThtAxsClckwsPstvPsStatus 3 "NotAvailable" 2 "ErrorIndicator" 1 "OnPositiveSideOfNeutral" 0 "NotOnPositiveSideOfNeutral" ;
VAL_ 2365403134 Jystck4ThtAxsCntrClckwsNgtvPsStt 3 "NotAvailable" 2 "ErrorIndicator" 1 "OnNegativeSideOfNeutral" 0 "NotOnNegativeSideOfNeutral" ;
VAL_ 2365403134 Jystck4ThtaAxisNeutralPosStatus 3 "NotAvailable" 2 "ErrorIndicator" 1 "InNeutralPos" 0 "NotInNeutralPos" ;
VAL_ 2365403134 Jystck4GrpYAxsLvrFrwrdPstvPsStts 3 "NotAvailable" 2 "ErrorIndicator" 1 "OnPositiveSideOfNeutral" 0 "NotOnPositiveSideOfNeutral" ;
VAL_ 2365403134 Jystck4GrpYAxsLvrBckNgtvPsSttus 3 "NotAvailable" 2 "ErrorIndicator" 1 "OnNegativeSideOfNeutral" 0 "NotOnNegativeSideOfNeutral" ;
VAL_ 2365403134 Jystck4GrpYAxisNeutralPosStatus 3 "NotAvailable" 2 "ErrorIndicator" 1 "InNeutralPos" 0 "NotInNeutralPos" ;
VAL_ 2365403134 Jystck4GrpXAxsLvrRghtPstvPsStts 3 "NotAvailable" 2 "ErrorIndicator" 1 "OnPositiveSideOfNeutral" 0 "NotOnPositiveSideOfNeutral" ;
VAL_ 2365403134 Jystck4GrpXAxsLvrLftNgtvPsSttus 3 "NotAvailable" 2 "ErrorIndicator" 1 "OnNegativeSideOfNeutral" 0 "NotOnNegativeSideOfNeutral" ;
VAL_ 2365403134 Jystck4GrpXAxisNeutralPosStatus 3 "NotAvailable" 2 "ErrorIndicator" 1 "InNeutralPos" 0 "NotInNeutralPos" ;
VAL_ 2365400062 Jystck10GrpXAxisDetentPosStatus 3 "NotAvailable" 2 "ErrorIndicator" 1 "InDetentPos" 0 "NotInDetentPos" ;
VAL_ 2365400062 Jystck10GrpYAxisDetentPosStatus 3 "NotAvailable" 2 "ErrorIndicator" 1 "InDetentPos" 0 "NotInDetentPos" ;
VAL_ 2365400062 Jystck10ThtaAxisDetentPosStatus 3 "NotAvailable" 2 "ErrorIndicator" 1 "InDetentPos" 0 "NotInDetentPos" ;
VAL_ 2365400062 Jystck10ThtAxsClckwsPstvPsSttus 3 "NotAvailable" 2 "ErrorIndicator" 1 "OnPositiveSideOfNeutral" 0 "NotOnPositiveSideOfNeutral" ;
VAL_ 2365400062 Jystck10ThtAxsCntrClckwsNgtvPsSt 3 "NotAvailable" 2 "ErrorIndicator" 1 "OnNegativeSideOfNeutral" 0 "NotOnNegativeSideOfNeutral" ;
VAL_ 2365400062 Jystck10ThtAxisNeutralPosStatus 3 "NotAvailable" 2 "ErrorIndicator" 1 "InNeutralPos" 0 "NotInNeutralPos" ;
VAL_ 2365400062 Jystck10GrpYAxsLvrFrwrdPstvPsStt 3 "NotAvailable" 2 "ErrorIndicator" 1 "OnPositiveSideOfNeutral" 0 "NotOnPositiveSideOfNeutral" ;
VAL_ 2365400062 Jystck10GrpYAxsLvrBckNgtvPsStts 3 "NotAvailable" 2 "ErrorIndicator" 1 "OnNegativeSideOfNeutral" 0 "NotOnNegativeSideOfNeutral" ;
VAL_ 2365400062 Jystck10GrpYAxsNeutralPosStatus 3 "NotAvailable" 2 "ErrorIndicator" 1 "InNeutralPos" 0 "NotInNeutralPos" ;
VAL_ 2365400062 Jystck10GrpXAxsLvrRghtPstvPsStts 3 "NotAvailable" 2 "ErrorIndicator" 1 "OnPositiveSideOfNeutral" 0 "NotOnPositiveSideOfNeutral" ;
VAL_ 2365400062 Jystck10GrpXAxsLvrLftNgtvPsStts 3 "NotAvailable" 2 "ErrorIndicator" 1 "OnNegativeSideOfNeutral" 0 "NotOnNegativeSideOfNeutral" ;
VAL_ 2365400062 Jystck10GrpXAxsNeutralPosStatus 3 "NotAvailable" 2 "ErrorIndicator" 1 "InNeutralPos" 0 "NotInNeutralPos" ;
